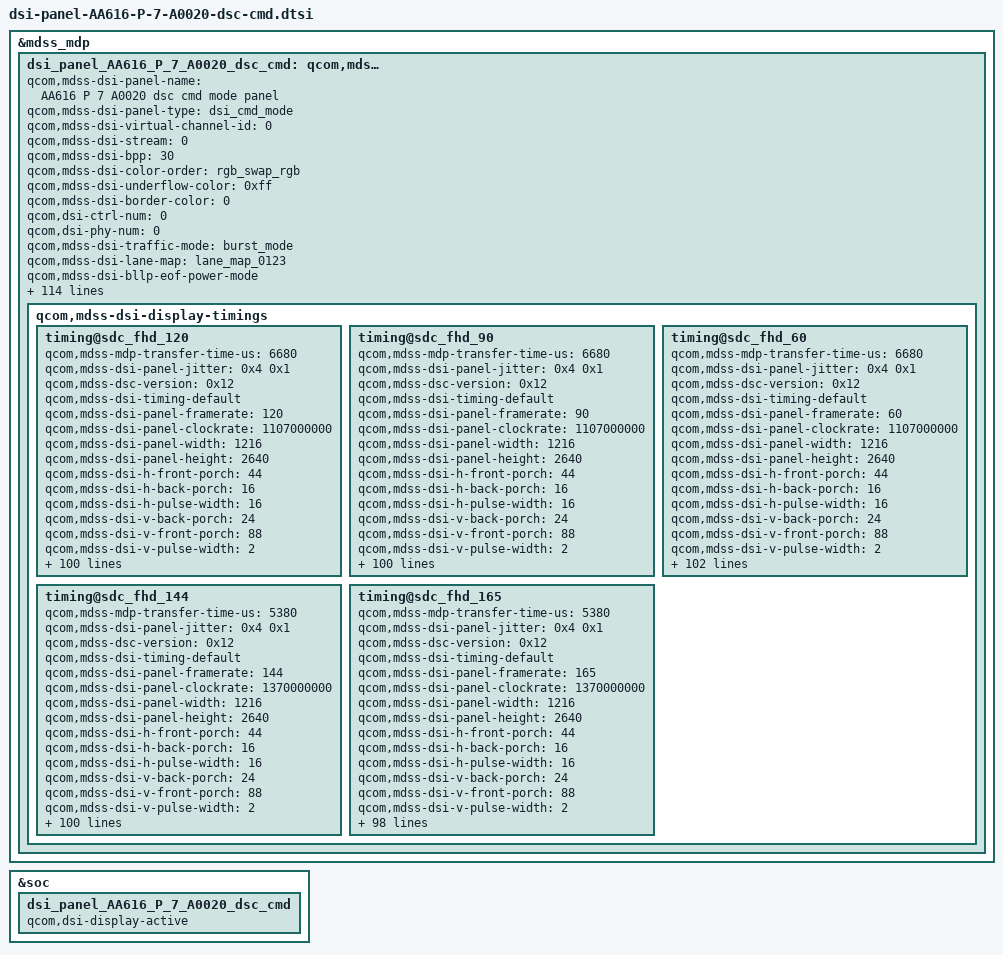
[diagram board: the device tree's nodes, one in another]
&mdss_mdp {
	dsi_panel_AA616_P_7_A0020_dsc_cmd: qcom,mdss_dsi_panel_AA616_P_7_A0020_dsc_cmd {
		qcom,mdss-dsi-panel-name = "AA616 P 7 A0020 dsc cmd mode panel";
		qcom,mdss-dsi-panel-type = "dsi_cmd_mode";
		qcom,mdss-dsi-virtual-channel-id = <0>;
		qcom,mdss-dsi-stream = <0>;
		qcom,mdss-dsi-bpp = <30>;
		qcom,mdss-dsi-color-order = "rgb_swap_rgb";
		qcom,mdss-dsi-underflow-color = <0xff>;
		qcom,mdss-dsi-border-color = <0>;
		qcom,dsi-ctrl-num = <0>;
		qcom,dsi-phy-num = <0>;
		qcom,mdss-dsi-traffic-mode = "burst_mode";
		qcom,mdss-dsi-lane-map = "lane_map_0123";
		qcom,mdss-dsi-bllp-eof-power-mode;
		qcom,mdss-dsi-bllp-power-mode;
		qcom,mdss-dsi-lane-0-state;
		qcom,mdss-dsi-lane-1-state;
		qcom,mdss-dsi-lane-2-state;
		qcom,mdss-dsi-lane-3-state;
		qcom,mdss-dsi-dma-trigger = "trigger_sw";
		qcom,mdss-dsi-dma-schedule-line = <1>;
		qcom,mdss-dsi-dma-schedule-window = <10>;
		qcom,mdss-dsi-mdp-trigger = "none";
		qcom,mdss-dsi-reset-sequence = <1 2>, <0 5>, <1 25>;
		qcom,mdss-dsi-te-pin-select = <1>;
		qcom,mdss-dsi-te-dcs-command = <1>;
		qcom,mdss-pan-physical-width-dimension = <71>;
		qcom,mdss-pan-physical-height-dimension = <157>;
		qcom,mdss-dsi-init-delay-us = <1000>;
		qcom,mdss-dsi-te-check-enable;
		qcom,mdss-dsi-te-using-te-pin;
		//qcom,mdss-dsi-lp11-init;
		qcom,mdss-dsi-wr-mem-start = <0x2c>;
		qcom,mdss-dsi-wr-mem-continue = <0x3c>;
		qcom,mdss-dsi-panel-jitter = <0x4 0x1>;
		qcom,mdss-bl-high2bit;
  		/* HDR Setting */
		qcom,mdss-dsi-panel-hdr-enabled;
		qcom,mdss-dsi-panel-hdr-color-primaries = <15635 16450 34000 16000 13250 34500 7500 3000>;
		//update for [MPC15]android.mediapc.cts.PerformanceClassTest#testDisplayHdr pass
		//qcom,mdss-dsi-panel-peak-brightness = <5400000>;
		qcom,mdss-dsi-panel-peak-brightness = <20000000>;
		qcom,mdss-dsi-panel-average-brightness = <2000000>;
		qcom,mdss-dsi-panel-blackness-level = <4000>;
		qcom,dynamic-mode-switch-enabled;
		qcom,dynamic-mode-switch-type = "dynamic-resolution-switch-immediate";
		qcom,mdss-dsi-display-timings {
			timing@sdc_fhd_120 {
				#include "dsi-panel-AA616-P-7-A0020-common.dtsi"
				#include "dsi-panel-AA616-P-7-A0020-loading-effect.dtsi"
				qcom,mdss-mdp-transfer-time-us = <6680>;
				qcom,mdss-dsi-panel-jitter = <0x4 0x1>;
				qcom,mdss-dsc-version = <0x12>;
				qcom,mdss-dsi-timing-default;
				qcom,mdss-dsi-panel-framerate = <120>;
				qcom,mdss-dsi-panel-clockrate = <1107000000>;
				qcom,mdss-dsi-panel-width = <1216>;
				qcom,mdss-dsi-panel-height = <2640>;

				qcom,mdss-dsi-h-front-porch = <44>;
				qcom,mdss-dsi-h-back-porch = <16>;
				qcom,mdss-dsi-h-pulse-width = <16>;
				qcom,mdss-dsi-v-back-porch = <24>;
				qcom,mdss-dsi-v-front-porch = <88>;
				qcom,mdss-dsi-v-pulse-width = <2>;
				qcom,mdss-dsi-h-sync-pulse = <0>;

				qcom,mdss-dsi-timing-switch-command = [
					39 00 00 40 00 00 04 FF 5A A5 08 // PAGE 08
					15 00 00 40 00 00 02 98 02 //Queue Start Close CDM FIFO Reset
					39 00 00 40 00 00 04 FF 5A A5 4F //CMD_Q
					15 00 00 40 00 00 02 80 01 //Enable MSFC
					15 00 00 40 00 00 02 81 06 //04 Rising,05Falling
					15 00 00 40 00 00 02 88 78 // cmd core0 queue start
					39 00 00 40 00 00 04 FF 5A A5 53
					39 00 00 40 00 00 06 90 44 00 00 04 00
					39 00 00 40 00 00 06 FE 44 00 00 04 00
					39 00 00 40 00 00 06 FE 44 00 00 04 00
					39 00 00 40 00 00 06 FE 44 00 00 04 00
					15 00 00 40 00 00 02 F0 01 //MURA_TUNNING
					15 00 00 40 00 00 02 00 00
					15 00 00 40 00 00 02 00 00
					15 00 00 40 00 00 02 00 00
					15 00 00 40 00 00 02 00 00
					15 00 00 40 00 00 02 00 00
					15 00 00 40 00 00 02 00 00
					15 00 00 40 00 00 02 00 00
					15 00 00 40 00 00 02 00 00
					39 00 00 40 00 00 04 FF 5A A5 63
					39 00 00 40 00 00 06 F1 20 20 20 20 20
					39 00 00 40 00 00 06 FE 20 00 00 00 00
					39 00 00 40 00 00 06 FE 00 00 00 00 00
					15 00 00 40 00 00 02 FE 00
					15 00 00 40 00 00 02 00 00
					15 00 00 40 00 00 02 00 00
					15 00 00 40 00 00 02 00 00
					15 00 00 40 00 00 02 00 00
					15 00 00 40 00 00 02 00 00
					39 00 00 40 00 00 06 F2 00 00 00 00 00
					39 00 00 40 00 00 06 FE 00 00 00 00 00
					39 00 00 40 00 00 06 FE 00 00 00 00 00
					15 00 00 40 00 00 02 FE 00
					15 00 00 40 00 00 02 00 00
					15 00 00 40 00 00 02 00 00
					15 00 00 40 00 00 02 00 00
					15 00 00 40 00 00 02 00 00
					15 00 00 40 00 00 02 00 00
					39 00 00 40 00 00 06 F3 00 00 00 00 00
					39 00 00 40 00 00 06 FE 00 20 20 20 20
					39 00 00 40 00 00 06 FE 00 00 00 00 00
					15 00 00 40 00 00 02 FE 00
					15 00 00 40 00 00 02 00 00
					15 00 00 40 00 00 02 00 00
					15 00 00 40 00 00 02 00 00
					15 00 00 40 00 00 02 00 00
					15 00 00 40 00 00 02 00 00
					39 00 00 40 00 00 06 F4 00 00 00 00 00
					39 00 00 40 00 00 06 FE 00 F0 F0 F0 F0
					39 00 00 40 00 00 06 FE 00 00 00 00 00
					15 00 00 40 00 00 02 FE 00
					15 00 00 40 00 00 02 00 00
					15 00 00 40 00 00 02 00 00
					15 00 00 40 00 00 02 00 00
					15 00 00 40 00 00 02 00 00
					15 00 00 40 00 00 02 00 00
					15 00 00 40 00 00 02 00 00
					15 00 00 40 00 00 02 00 00
					15 00 00 40 00 00 02 00 00
					39 00 00 40 00 00 04 FF 5A A5 53
					15 00 00 40 00 00 02 F0 00
					39 00 00 40 00 00 04 FF 5A A5 00 // PAGE 00
					15 00 00 40 00 00 02 60 00 //120Hz
					15 00 00 40 00 00 02 7D 00
					39 00 00 40 00 00 04 FF 5A A5 20
					15 00 00 40 00 00 02 BB 05 //sync Setting
					39 00 00 40 00 00 04 FF 5A A5 08 //ALL Done open CDM FIFO Reset
					15 00 00 40 00 00 02 98 A6
					39 00 00 40 00 00 04 FF 5A A5 00 //Dummy write
					15 00 00 40 00 00 02 00 00
					39 00 00 40 00 00 04 FF 5A A5 4F // PAGE 4F
					15 00 00 40 00 00 02 8B 78 // cmd core 0 queue all done
					39 00 00 00 00 00 04 FF 5A A5 00
				];
				qcom,mdss-dsi-on-command = [
					39 00 00 40 00 00 04 FF 5A A5 08
					15 00 00 40 00 00 02 C8 62
					39 00 00 40 00 00 04 FF 5A A5 21
					15 00 00 40 00 00 02 A4 38
					39 00 00 40 00 00 04 FF 5A A5 23
					15 00 00 40 00 00 02 85 15
					39 00 00 40 00 00 04 FF 5A A5 06
					15 00 00 40 00 00 02 C6 01
					39 00 00 40 00 00 04 FF 5A A5 08
					15 00 00 40 00 00 02 D2 05
					15 00 00 40 00 00 02 D3 01
					39 00 00 40 00 00 09 ED FF FF FF FF FF FF 45 FF
					39 00 00 40 00 00 09 EE FF FD FF FD F9 FA BE 76

					39 00 00 40 00 00 04 FF 5A A5 07
					15 00 00 40 00 00 02 8A 01
					39 00 00 40 00 00 03 8B 21 E0
					39 00 00 40 00 00 64 81 00 00 00 00 00 12 00 00 AB 21 00 0A 50 04 C0 00 14 02 60 02 60 01 55 01 D3 00 0A 01 08 00 33 00 0D 05 7A 19 5A 08 00 0B F0 07 10 20 00 06 0F 0F 33 0E 1C 2A 38 46 54 62 69 70 77 79 7B 7D 7E 00 82 11 40 19 C0 22 3E 32 7C 3A BA 3A F8 3B 38 3B 38 3B 76 4B 76 4B 74 4B 74 5B B4 73 F4 01 00 00 00 00 00
					15 00 00 40 00 00 02 91 03
					39 00 00 40 00 00 04 FF 5A A5 14
					15 00 00 40 00 00 02 80 00
					15 00 00 40 00 00 02 82 01
					39 00 00 40 00 00 04 FF 5A A5 17
					15 00 00 40 00 00 02 A0 0C
					39 00 00 40 00 00 04 FF 5A A5 13
					15 00 00 40 00 00 02 F9 3C
					39 00 00 40 00 00 04 FF 5A A5 22
					39 00 00 40 00 00 08 D8 00 F4 11 10 3E 17 17
					39 00 00 40 00 00 08 D9 00 F3 11 10 3E 17 17
					39 00 00 40 00 00 08 DA 00 EA 11 10 2B 16 16
					39 00 00 40 00 00 08 DB 00 E9 11 10 2B 16 16
					39 00 00 40 00 00 0A DC 84 94 BB 00 20 C4 A1 CC 10
					15 00 00 40 00 00 02 DD 01
					15 00 00 40 00 00 02 DE F1
					15 00 00 40 00 00 02 DF 80
					39 00 00 00 00 00 07 E0 02 00 5F 21 00 28

					39 00 00 40 00 00 04 FF 5A A5 00
					15 00 00 00 00 00 02 7D 00

					39 00 00 40 00 00 04 FF 5A A5 22
					39 00 00 40 00 00 08 D8 00 F6 11 10 38 17 17
					39 00 00 40 00 00 08 D9 00 F5 11 10 38 17 17
					39 00 00 40 00 00 08 DA 00 EA 11 10 2B 16 16
					39 00 00 40 00 00 08 DB 00 E9 11 10 2B 16 16
					39 00 00 40 00 00 0A DC 84 94 BB 00 20 C4 A1 CC 10
					15 00 00 40 00 00 02 DD 01
					15 00 00 40 00 00 02 DE F1
					15 00 00 40 00 00 02 DF 80
					39 00 00 40 00 00 07 E0 02 00 5F 21 00 28
					15 00 00 40 00 00 02 5E 01 // Skip frame Enable
					15 00 00 40 00 00 02 60 00 // Normal mode1=120Hz
					15 00 00 40 00 00 02 61 02 //AOD in Mode3=30Hz
					15 00 00 40 00 00 02 6D 01 // IRC enable
					15 00 00 40 00 00 02 35 00 // TE on
					15 00 00 00 00 00 02 53 20 // BC On

					// 120Hz
					39 00 00 40 00 00 04 FF 5A A5 00
					15 00 00 00 00 00 02 60 00
					15 00 00 00 78 00 02 11 00
					39 00 00 40 00 00 04 FF 5A A5 49
					39 00 00 40 00 00 0C 80 00 01 09 11 21 41 81 C1 01 00 01
					39 00 00 40 00 00 11 81 01 00 BD 00 18 01 41 02 42 02 A6 03 8B 05 DD 06
					39 00 00 40 00 00 13 82 01 00 BD 00 18 01 41 02 42 02 A6 03 8B 05 DD 06 00 00
					15 00 00 40 00 00 02 83 07
					15 00 00 40 00 00 02 84 0A
					39 00 00 40 00 00 04 85 80 00 02
					39 00 00 40 00 00 04 86 80 00 02
					39 00 00 40 00 00 04 A0 40 40 40
					39 00 00 40 00 00 04 A1 40 40 40
					39 00 00 40 00 00 04 A2 40 40 40
					15 00 00 40 00 00 02 A6 3F
					15 00 00 40 00 00 02 A7 03
					15 00 00 40 00 00 02 AD 01
					15 00 00 40 00 00 02 AE 00
					15 00 00 40 00 00 02 AF 00
					15 00 00 40 00 00 02 D9 02
					15 00 00 40 00 00 02 DA F7
					15 00 00 40 00 00 02 DB 9C
					15 00 00 40 00 00 02 DC 03
					15 00 00 40 00 00 02 DF 06
					15 00 00 40 00 00 02 E0 01
					39 00 00 40 00 00 04 FF 5A A5 5A
					39 00 00 40 00 00 04 80 03 D0 00
					39 00 00 40 00 00 04 81 5D D0 40
					39 00 00 40 00 00 04 82 0F 04 0B
					39 00 00 40 00 00 04 83 6D 80 0C
					39 00 00 40 00 00 04 84 50 20 4A
					39 00 00 40 00 00 04 85 18 10 2D
					39 00 00 40 00 00 04 86 7E 80 0E
					39 00 00 40 00 00 04 87 1D 13 17
					39 00 00 40 00 00 04 88 10 0F 0F
					39 00 00 40 00 00 04 89 0C 0A 06
					39 00 00 40 00 00 04 8A 7F 14 F0
					39 00 00 40 00 00 04 8B 1A 15 1B
					39 00 00 40 00 00 04 8C 18 12 1A
					39 00 00 40 00 00 04 8D 18 11 18
					39 00 00 40 00 00 04 8E 09 06 0A
					39 00 00 40 00 00 04 8F 7F 46 F6
					39 00 00 40 00 00 04 90 1C 14 1D
					39 00 00 40 00 00 04 91 1A 12 1B
					39 00 00 40 00 00 04 92 18 0A 19
					39 00 00 40 00 00 04 93 15 06 16
					39 00 00 40 00 00 04 94 0C 02 0D
					39 00 00 40 00 00 04 95 57 1D 03
					39 00 00 40 00 00 04 96 18 10 1A
					39 00 00 40 00 00 04 97 10 0F 12
					39 00 00 40 00 00 04 98 10 07 10
					39 00 00 40 00 00 04 99 0C 0A 0F
					39 00 00 40 00 00 04 9A 04 03 0A
					39 00 00 40 00 00 04 9B 03 01 03
					39 00 00 40 00 00 04 9C 52 3E 2D
					39 00 00 40 00 00 04 9D 34 32 2D
					39 00 00 40 00 00 04 9E 23 20 22
					39 00 00 40 00 00 04 9F 1D 1A 1D
					39 00 00 40 00 00 04 A0 16 12 16
					39 00 00 40 00 00 04 A1 0A 08 09
					39 00 00 40 00 00 04 A2 07 03 05
					39 00 00 40 00 00 04 A3 06 01 03
					39 00 00 40 00 00 04 A4 02 D0 00
					39 00 00 40 00 00 04 A5 14 DD 0F
					39 00 00 40 00 00 04 A6 0A E4 0C
					39 00 00 40 00 00 04 A7 4A 80 D8
					39 00 00 40 00 00 04 A8 05 02 07
					39 00 00 40 00 00 04 A9 03 00 05
					39 00 00 40 00 00 04 AA 24 80 8F
					39 00 00 40 00 00 04 AB 0A 06 09
					39 00 00 40 00 00 04 AC 07 05 07
					39 00 00 40 00 00 04 AD 03 00 05
					39 00 00 40 00 00 04 AE 32 03 04
					39 00 00 40 00 00 04 AF 13 10 12
					39 00 00 40 00 00 04 B0 10 06 0D
					39 00 00 40 00 00 04 B1 0E 04 0C
					39 00 00 40 00 00 04 B2 03 01 05
					39 00 00 40 00 00 04 B3 2A 16 02
					39 00 00 40 00 00 04 B4 0E 0C 10
					39 00 00 40 00 00 04 B5 0D 0A 0E
					39 00 00 40 00 00 04 B6 0A 07 0A
					39 00 00 40 00 00 04 B7 07 05 0B
					39 00 00 40 00 00 04 B8 05 04 06
					39 00 00 40 00 00 04 B9 1F 10 1D
					39 00 00 40 00 00 04 BA 18 0F 12
					39 00 00 40 00 00 04 BB 13 0D 0A
					39 00 00 40 00 00 04 BC 0E 08 0A
					39 00 00 40 00 00 04 BD 09 06 0C
					39 00 00 40 00 00 04 BE 07 05 08
					39 00 00 40 00 00 04 BF 04 04 06
					39 00 00 40 00 00 04 C0 37 23 2F
					39 00 00 40 00 00 04 C1 27 1F 1F
					39 00 00 40 00 00 04 C2 1D 18 0D
					39 00 00 40 00 00 04 C3 1A 12 08
					39 00 00 40 00 00 04 C4 12 10 06
					39 00 00 40 00 00 04 C5 0A 07 03
					39 00 00 40 00 00 04 C6 08 04 02
					39 00 00 40 00 00 04 C7 03 02 01
					39 00 00 40 00 00 04 C8 40 06 0A
					39 00 00 40 00 00 04 C9 25 00 12
					39 00 00 40 00 00 04 CA 16 00 06
					39 00 00 40 00 00 04 CB 5A 00 00
					39 00 00 40 00 00 04 CC 06 01 06
					39 00 00 40 00 00 04 CD 03 00 05
					39 00 00 40 00 00 04 CE 30 00 00
					39 00 00 40 00 00 04 CF 10 04 06
					39 00 00 40 00 00 04 D0 0D 02 0E
					39 00 00 40 00 00 04 D1 06 00 0A
					39 00 00 40 00 00 04 D2 20 02 08
					39 00 00 40 00 00 04 D3 0D 04 06
					39 00 00 40 00 00 04 D4 08 00 05
					39 00 00 40 00 00 04 D5 06 00 03
					39 00 00 40 00 00 04 D6 05 00 01
					39 00 00 40 00 00 04 D7 26 15 16
					39 00 00 40 00 00 04 D8 12 0D 13
					39 00 00 40 00 00 04 D9 10 0A 12
					39 00 00 40 00 00 04 DA 0D 09 08
					39 00 00 40 00 00 04 DB 07 05 07
					39 00 00 40 00 00 04 DC 04 03 05
					39 00 00 40 00 00 04 DD 26 2A 26
					39 00 00 40 00 00 04 DE 20 28 23
					39 00 00 40 00 00 04 DF 16 1A 1E
					39 00 00 40 00 00 04 E0 12 16 14
					39 00 00 40 00 00 04 E1 0D 0F 0E
					39 00 00 40 00 00 04 E2 03 04 02
					39 00 00 40 00 00 04 E3 02 03 01
					39 00 00 40 00 00 04 E4 34 23 14
					39 00 00 40 00 00 04 E5 16 13 00
					39 00 00 40 00 00 04 E6 08 0D 00
					39 00 00 40 00 00 04 E7 06 0A 00
					39 00 00 40 00 00 04 E8 05 08 00
					39 00 00 40 00 00 04 E9 03 05 00
					39 00 00 40 00 00 04 EA 02 04 00
					39 00 00 40 00 00 04 EB 00 02 00
					39 00 00 40 00 00 04 FF 5A A5 5B
					39 00 00 40 00 00 04 80 05 00 00
					39 00 00 40 00 00 04 81 2A FA 10
					39 00 00 40 00 00 04 82 04 00 01
					39 00 00 40 00 00 04 83 2C FC 15
					39 00 00 40 00 00 04 84 08 01 03
					39 00 00 40 00 00 04 85 03 01 02
					39 00 00 40 00 00 04 86 0D 08 0E
					39 00 00 40 00 00 04 87 05 03 02
					39 00 00 40 00 00 04 88 04 02 03
					39 00 00 40 00 00 04 89 03 00 01
					39 00 00 40 00 00 04 8A 16 03 06
					39 00 00 40 00 00 04 8B 04 03 03
					39 00 00 40 00 00 04 8C 02 02 02
					39 00 00 40 00 00 04 8D 01 00 01
					39 00 00 40 00 00 04 8E 00 00 00
					39 00 00 40 00 00 04 8F 24 18 1B
					39 00 00 40 00 00 04 90 18 1C 1A
					39 00 00 40 00 00 04 91 14 16 14
					39 00 00 40 00 00 04 92 10 0F 11
					39 00 00 40 00 00 04 93 0A 08 0B
					39 00 00 40 00 00 04 94 05 06 04
					39 00 00 40 00 00 04 95 25 1D 1E
					39 00 00 40 00 00 04 96 16 18 1A
					39 00 00 40 00 00 04 97 12 14 16
					39 00 00 40 00 00 04 98 10 11 12
					39 00 00 40 00 00 04 99 0A 0C 0D
					39 00 00 40 00 00 04 9A 07 08 0A
					39 00 00 40 00 00 04 9B 05 06 07
					39 00 00 40 00 00 04 9C 38 2C 44
					39 00 00 40 00 00 04 9D 36 2A 40
					39 00 00 40 00 00 04 9E 32 24 3A
					39 00 00 40 00 00 04 9F 20 1A 2A
					39 00 00 40 00 00 04 A0 1A 16 1F
					39 00 00 40 00 00 04 A1 16 10 14
					39 00 00 40 00 00 04 A2 07 08 07
					39 00 00 40 00 00 04 A3 05 06 06
					39 00 00 40 00 00 04 A4 06 00 00
					39 00 00 40 00 00 04 A5 10 09 02
					39 00 00 40 00 00 04 A6 06 00 02
					39 00 00 40 00 00 04 A7 0F 08 04
					39 00 00 40 00 00 04 A8 06 02 07
					39 00 00 40 00 00 04 A9 05 01 06
					39 00 00 40 00 00 04 AA 10 02 07
					39 00 00 40 00 00 04 AB 04 02 03
					39 00 00 40 00 00 04 AC 03 01 02
					39 00 00 40 00 00 04 AD 02 00 04
					39 00 00 40 00 00 04 AE 1A 06 09
					39 00 00 40 00 00 04 AF 09 06 09
					39 00 00 40 00 00 04 B0 08 05 07
					39 00 00 40 00 00 04 B1 07 03 05
					39 00 00 40 00 00 04 B2 04 01 03
					39 00 00 40 00 00 04 B3 1F 13 16
					39 00 00 40 00 00 04 B4 18 13 19
					39 00 00 40 00 00 04 B5 15 12 17
					39 00 00 40 00 00 04 B6 11 0D 13
					39 00 00 40 00 00 04 B7 0A 08 0D
					39 00 00 40 00 00 04 B8 04 06 07
					39 00 00 40 00 00 04 B9 26 1D 23
					39 00 00 40 00 00 04 BA 1A 18 1C
					39 00 00 40 00 00 04 BB 14 10 15
					39 00 00 40 00 00 04 BC 10 13 12
					39 00 00 40 00 00 04 BD 0B 0F 0F
					39 00 00 40 00 00 04 BE 04 05 04
					39 00 00 40 00 00 04 BF 03 02 03
					39 00 00 40 00 00 04 C0 3C 30 4C
					39 00 00 40 00 00 04 C1 3A 2A 40
					39 00 00 40 00 00 04 C2 32 24 3A
					39 00 00 40 00 00 04 C3 20 1D 2C
					39 00 00 40 00 00 04 C4 1A 16 1F
					39 00 00 40 00 00 04 C5 16 10 14
					39 00 00 40 00 00 04 C6 05 06 08
					39 00 00 40 00 00 04 C7 04 05 06
					39 00 00 40 00 00 04 C8 04 00 00
					39 00 00 40 00 00 04 C9 18 0D 10
					39 00 00 40 00 00 04 CA 18 00 02
					39 00 00 40 00 00 04 CB 0C 04 04
					39 00 00 40 00 00 04 CC 03 02 01
					39 00 00 40 00 00 04 CD 02 01 00
					39 00 00 40 00 00 04 CE 06 03 08
					39 00 00 40 00 00 04 CF 04 02 04
					39 00 00 40 00 00 04 D0 03 01 03
					39 00 00 40 00 00 04 D1 02 00 00
					39 00 00 40 00 00 04 D2 0E 0A 10
					39 00 00 40 00 00 04 D3 0A 08 0D
					39 00 00 40 00 00 04 D4 07 05 0A
					39 00 00 40 00 00 04 D5 04 03 07
					39 00 00 40 00 00 04 D6 03 01 06
					39 00 00 40 00 00 04 D7 18 12 22
					39 00 00 40 00 00 04 D8 16 10 1A
					39 00 00 40 00 00 04 D9 12 0A 14
					39 00 00 40 00 00 04 DA 0D 08 12
					39 00 00 40 00 00 04 DB 06 06 0C
					39 00 00 40 00 00 04 DC 02 04 03
					39 00 00 40 00 00 04 DD 2C 28 34
					39 00 00 40 00 00 04 DE 28 22 30
					39 00 00 40 00 00 04 DF 20 18 2A
					39 00 00 40 00 00 04 E0 16 14 1A
					39 00 00 40 00 00 04 E1 0A 08 0D
					39 00 00 40 00 00 04 E2 03 03 03
					39 00 00 40 00 00 04 E3 02 02 02
					39 00 00 40 00 00 04 E4 3C 34 40
					39 00 00 40 00 00 04 E5 3A 2A 40
					39 00 00 40 00 00 04 E6 32 24 3A
					39 00 00 40 00 00 04 E7 20 1D 2C
					39 00 00 40 00 00 04 E8 1A 16 1F
					39 00 00 40 00 00 04 E9 16 10 14
					39 00 00 40 00 00 04 EA 03 02 03
					39 00 00 40 00 00 04 EB 04 05 06
					39 00 00 40 00 00 04 FF 5A A5 5C
					39 00 00 40 00 00 04 80 03 F4 FA
					39 00 00 40 00 00 04 81 05 00 02
					39 00 00 40 00 00 04 82 02 01 03
					39 00 00 40 00 00 04 83 09 04 06
					39 00 00 40 00 00 04 84 05 02 05
					39 00 00 40 00 00 04 85 04 01 04
					39 00 00 40 00 00 04 86 08 07 05
					39 00 00 40 00 00 04 87 07 05 0A
					39 00 00 40 00 00 04 88 04 04 04
					39 00 00 40 00 00 04 89 02 02 02
					39 00 00 40 00 00 04 8A 0C 08 0F
					39 00 00 40 00 00 04 8B 0A 07 0C
					39 00 00 40 00 00 04 8C 09 06 0A
					39 00 00 00 00 00 04 8D 06 05 08
					39 00 00 40 00 00 04 8E 04 03 05
					39 00 00 40 00 00 04 8F 23 1A 26
					39 00 00 40 00 00 04 90 1C 14 1D
					39 00 00 40 00 00 04 91 12 0A 18
					39 00 00 40 00 00 04 92 0D 07 14
					39 00 00 40 00 00 04 93 06 07 0A
					39 00 00 40 00 00 04 94 02 04 03
					39 00 00 40 00 00 04 95 34 32 3A
					39 00 00 40 00 00 04 96 2B 28 34
					39 00 00 40 00 00 04 97 26 24 2A
					39 00 00 40 00 00 04 98 16 14 1A
					39 00 00 40 00 00 04 99 0A 08 0D
					39 00 00 40 00 00 04 9A 03 03 02
					39 00 00 40 00 00 04 9B 02 02 02
					39 00 00 40 00 00 04 9C 44 3E 54
					39 00 00 40 00 00 04 9D 3A 2A 40
					39 00 00 40 00 00 04 9E 34 26 3A
					39 00 00 40 00 00 04 9F 20 1D 2C
					39 00 00 40 00 00 04 A0 1A 16 1F
					39 00 00 40 00 00 04 A1 16 10 14
					39 00 00 40 00 00 04 A2 03 02 03
					39 00 00 40 00 00 04 A3 04 05 06
					39 00 00 40 00 00 04 A4 04 02 02
					39 00 00 40 00 00 04 A5 06 03 03
					39 00 00 40 00 00 04 A6 02 01 01
					39 00 00 40 00 00 04 A7 03 02 02
					39 00 00 40 00 00 04 A8 02 01 02
					39 00 00 40 00 00 04 A9 02 01 02
					39 00 00 40 00 00 04 AA 05 05 06
					39 00 00 40 00 00 04 AB 04 04 05
					39 00 00 40 00 00 04 AC 03 03 04
					39 00 00 40 00 00 04 AD 02 02 03
					39 00 00 40 00 00 04 AE 08 04 08
					39 00 00 40 00 00 04 AF 06 03 07
					39 00 00 40 00 00 04 B0 05 02 06
					39 00 00 40 00 00 04 B1 03 01 05
					39 00 00 40 00 00 04 B2 02 00 04
					39 00 00 40 00 00 04 B3 25 23 24
					39 00 00 40 00 00 04 B4 23 20 21
					39 00 00 40 00 00 04 B5 13 0D 14
					39 00 00 40 00 00 04 B6 0E 0A 10
					39 00 00 40 00 00 04 B7 06 08 0A
					39 00 00 40 00 00 04 B8 02 04 03
					39 00 00 40 00 00 04 B9 34 31 37
					39 00 00 40 00 00 04 BA 2B 28 34
					39 00 00 40 00 00 04 BB 26 24 2A
					39 00 00 40 00 00 04 BC 16 15 1A
					39 00 00 40 00 00 04 BD 0A 08 0D
					39 00 00 40 00 00 04 BE 02 03 02
					39 00 00 40 00 00 04 BF 02 01 02
					39 00 00 40 00 00 04 C0 35 33 28
					39 00 00 40 00 00 04 C1 34 2A 24
					39 00 00 40 00 00 04 C2 34 26 1C
					39 00 00 40 00 00 04 C3 20 1D 18
					39 00 00 40 00 00 04 C4 1A 16 16
					39 00 00 40 00 00 04 C5 16 10 14
					39 00 00 40 00 00 04 C6 03 02 03
					39 00 00 40 00 00 04 C7 04 05 06
					39 00 00 40 00 00 04 C8 08 04 06
					39 00 00 40 00 00 04 C9 08 04 06
					39 00 00 40 00 00 04 CA 07 03 05
					39 00 00 40 00 00 04 CB 07 03 05
					39 00 00 40 00 00 04 CC 00 00 00
					39 00 00 40 00 00 04 CD 00 00 00
					39 00 00 40 00 00 04 CE 00 00 00
					39 00 00 00 00 00 04 CF 00 00 00
					15 00 00 00 14 00 02 29 00
				];
				qcom,mdss-dsi-off-command=[
					05 00 00 00 14 00 01 28
					05 00 00 00 78 00 01 10
				];
				qcom,mdss-dsi-timing-switch-compensation-command = [
					39 00 00 40 00 00 04 FF 5A A5 08 // PAGE 08
					15 00 00 40 00 00 02 98 02 //Queue Start Close CDM FIFO Reset
					39 00 00 40 00 00 04 FF 5A A5 4F //CMD_Q
					15 00 00 40 00 00 02 80 01 //Enable MSFC
					15 00 00 40 00 00 02 81 06 //04 Rising,05Falling
					15 00 00 40 00 00 02 88 78 // cmd core0 queue start
					//queue1_str
					39 00 00 40 00 00 04 FF 5A A5 24
					39 00 00 40 00 00 06 C9 00 00 00 10 00
					39 00 00 40 00 00 04 FE 30 00 70
					39 00 00 40 00 00 06 CA 00 B0 00 E0 01 //11 13
					39 00 00 40 00 00 04 FE 10 01 30 //15 19
					39 00 00 40 00 00 06 CB 01 70 01 C0 02 //23  27
					39 00 00 40 00 00 04 FE 30 02 90 //33  41
					39 00 00 40 00 00 06 CC 03 70 03 E0 04 //55 63 79
					39 00 00 40 00 00 04 FE F0 05 F0 //95
					39 00 00 40 00 00 06 CD 07 10 08 F0 0A //113 143
					39 00 00 40 00 00 04 FE F0 0B A0 //175 186
					39 00 00 40 00 00 06 CE 0D 30 0E 10 0E //225 239
					39 00 00 40 00 00 04 FE F0 0F F0
					39 00 00 40 00 00 04 FF 5A A5 4F // PAGE 4F
					15 00 00 40 00 00 02 8A 78
					//queue2_str
					39 00 00 40 00 00 04 FF 5A A5 00 // PAGE 00
					15 00 00 40 00 00 02 60 00 //120hz
					15 00 00 40 00 00 02 7D 00
					39 00 00 40 00 00 04 FF 5A A5 20
					15 00 00 40 00 00 02 BB 05 //sync setting
					39 00 00 40 00 00 04 FF 5A A5 24
					39 00 00 40 00 00 06 C9 00 00 00 10 00
					39 00 00 40 00 00 04 FE 30 00 70
					39 00 00 40 00 00 06 CA 00 B0 00 D0 00 //11 13
					39 00 00 40 00 00 04 FE F0 01 30 //15 19
					39 00 00 40 00 00 06 CB 01 70 01 B0 02 //23  27
					39 00 00 40 00 00 04 FE 10 02 90 //33  41
					39 00 00 40 00 00 06 CC 03 70 03 F0 04 //55 63 79
					39 00 00 40 00 00 04 FE F0 05 F0 //95
					39 00 00 40 00 00 06 CD 07 10 08 F0 0A //113 143
					39 00 00 40 00 00 04 FE F0 0B A0 //175 186
					39 00 00 40 00 00 06 CE 0D 30 0E 10 0E //225 239
					39 00 00 40 00 00 04 FE F0 0F F0
					//queue2_end
					39 00 00 40 00 00 04 FF 5A A5 53
					15 00 00 40 00 00 02 F0 01 //MURA_TUNNING
					15 00 00 40 00 00 02 00 00
					15 00 00 40 00 00 02 00 00
					15 00 00 40 00 00 02 00 00
					15 00 00 40 00 00 02 00 00
					15 00 00 40 00 00 02 00 00
					15 00 00 40 00 00 02 00 00
					15 00 00 40 00 00 02 00 00
					15 00 00 40 00 00 02 00 00
					39 00 00 40 00 00 04 FF 5A A5 63
					39 00 00 40 00 00 06 F1 20 20 20 20 20
					39 00 00 40 00 00 06 FE 20 00 00 00 00
					39 00 00 40 00 00 06 FE 00 00 00 00 00
					15 00 00 40 00 00 02 FE 00
					15 00 00 40 00 00 02 00 00
					15 00 00 40 00 00 02 00 00
					15 00 00 40 00 00 02 00 00
					15 00 00 40 00 00 02 00 00
					15 00 00 40 00 00 02 00 00
					39 00 00 40 00 00 06 F2 00 00 00 00 00
					39 00 00 40 00 00 06 FE 00 00 00 00 00
					39 00 00 40 00 00 06 FE 00 00 00 00 00
					15 00 00 40 00 00 02 FE 00
					15 00 00 40 00 00 02 00 00
					15 00 00 40 00 00 02 00 00
					15 00 00 40 00 00 02 00 00
					15 00 00 40 00 00 02 00 00
					15 00 00 40 00 00 02 00 00
					39 00 00 40 00 00 06 F3 00 00 00 00 00
					39 00 00 40 00 00 06 FE 00 20 20 20 20
					39 00 00 40 00 00 06 FE 00 00 00 00 00
					15 00 00 40 00 00 02 FE 00
					15 00 00 40 00 00 02 00 00
					15 00 00 40 00 00 02 00 00
					15 00 00 40 00 00 02 00 00
					15 00 00 40 00 00 02 00 00
					15 00 00 40 00 00 02 00 00
					39 00 00 40 00 00 06 F4 00 00 00 00 00
					39 00 00 40 00 00 06 FE 00 F0 F0 F0 F0
					39 00 00 40 00 00 06 FE 00 00 00 00 00
					15 00 00 40 00 00 02 FE 00
					15 00 00 40 00 00 02 00 00
					15 00 00 40 00 00 02 00 00
					15 00 00 40 00 00 02 00 00
					15 00 00 40 00 00 02 00 00
					15 00 00 40 00 00 02 00 00
					15 00 00 40 00 00 02 00 00
					15 00 00 40 00 00 02 00 00
					15 00 00 40 00 00 02 00 00
					39 00 00 40 00 00 04 FF 5A A5 53
					15 00 00 40 00 00 02 F0 00
					39 00 00 40 00 00 04 FF 5A A5 00
					39 00 00 40 00 00 04 FF 5A A5 08 //ALL Done open CDM FIFO Reset
					15 00 00 40 00 00 02 98 A6
					39 00 00 40 00 00 04 FF 5A A5 00 //Dummy write
					15 00 00 40 00 00 02 00 00
					39 00 00 40 00 00 04 FF 5A A5 4F // PAGE 4F
					15 00 00 00 00 00 02 8B 78 // cmd core 0 queue all done
					39 00 00 00 00 00 04 FF 5A A5 00
					/* wait for te and blocking one frame */
					39 00 00 20 00 00 04 FF 5A A5 00
				];
				oplus,dsi-panel-switch-low-pwm-aod-on-command = [
				];
				oplus,dsi-panel-switch-low-pwm-aod-off-command = [
				];
				qcom,mdss-dsi-hbm-off-command = [
				];
				qcom,mdss-dsi-hbm-on-command = [
				];
				qcom,mdss-dsi-change-voltage-before-bl-0-command = [
				];
				qcom,mdss-dsi-lhbm-pressed-icon-on-command = [
				];
				qcom,mdss-dsi-lhbm-pressed-icon-off-command = [
				];
				qcom,mdss-dsi-aod-off-pwm-mode2-command = [
				];
				qcom,mdss-dsi-aod-off-compensation-command = [
				];
				qcom,mdss-dsi-aod-off-compensation-onepulse-command = [
				];
				/* pwm */
				qcom,mdss-dsi-pwm-state-l3tol2-command = [
				];
				qcom,mdss-dsi-pwm-state-l2tol3-command = [
				];
				qcom,mdss-dsi-pwm-switch-mode0-command= [
				];
				qcom,mdss-dsi-pwm-switch-mode2-command = [
				];
				qcom,mdss-dsi-timming-switch-pwm-mode2-command = [
				];
				qcom,mdss-dsi-pwm-switch-mode2-panel-on-command = [
				];
				qcom,mdss-dsi-pwm-state-l1tol3-command = [
				];
				qcom,mdss-dsi-pwm-state-l3tol1-command = [
				];
				qcom,mdss-dsi-hbm-max-command = [
				];
				qcom,mdss-dsi-hbm-exit-max-command = [
				];
				mdss-dsi-timing-switch-command-state = "dsi_hs_sync1_mode";
				qcom,mdss-dsi-lp1-command-state = "dsi_hs_sync1_mode";
				qcom,mdss-dsi-nolp-command-state = "dsi_hs_sync1_mode";
				oplus,dsi-panel-switch-low-pwm-aod-on-command-state = "dsi_hs_sync1_mode";
				oplus,dsi-panel-switch-low-pwm-aod-off-command-state = "dsi_hs_sync1_mode";
				qcom,mdss-dsi-aod-off-pwm-mode2-command-state = "dsi_hs_sync1_mode";
				qcom,mdss-dsi-aod-off-compensation-command-state = "dsi_lp_sync1_mode";
				qcom,mdss-dsi-aod-off-compensation-onepulse-command-state = "dsi_lp_sync1_mode";
				qcom,mdss-dsi-nolp-hpwm-command-state = "dsi_lp_sync1_mode";
				qcom,mdss-dsi-hbm-on-command-state = "dsi_hs_sync1_mode";
				qcom,mdss-dsi-hbm-off-command-state = "dsi_hs_sync1_mode";
				qcom,mdss-dsi-panel-read-register-open-state = "dsi_lp_mode";
				qcom,mdss-dsi-panel-read-register-close-state = "dsi_lp_mode";
				qcom,mdss-dsi-lhbm-pressed-icon-gamma-command-state = "dsi_lp_mode";
				qcom,mdss-dsi-lhbm-pressed-icon-grayscale-command-state = "dsi_lp_mode";
				qcom,mdss-dsi-lhbm-pressed-icon-on-command-state = "dsi_lp_mode";
				qcom,mdss-dsi-lhbm-pressed-icon-off-command-state = "dsi_lp_mode";
				qcom,mdss-dsi-lhbm-dbv-alpha-command-state = "dsi_hs_mode";

				qcom,mdss-dsi-reset-scanline-command-state = "dsi_hs_mode";
				qcom,mdss-dsi-recovery-scanline-command-state = "dsi_hs_mode";

				qcom,mdss-dsi-osc-track-on-command-state = "dsi_hs_mode";
				qcom,mdss-dsi-osc-track-off-command-state = "dsi_hs_mode";
				qcom,mdss-dsi-hbm-max-command-state = "dsi_hs_mode";
				qcom,mdss-dsi-hbm-exit-max-command-state = "dsi_hs_mode";

				qcom,lm-split = <608 608>;
				qcom,compression-mode = "dsc";
				qcom,mdss-dsc-encoders = <2>;
				qcom,mdss-dsc-slice-height = <20>;
				qcom,mdss-dsc-slice-width = <608>;
				qcom,mdss-dsc-slice-per-pkt = <2>;
				qcom,mdss-dsc-bit-per-component = <10>;
				qcom,mdss-dsc-bit-per-pixel = <8>;
				qcom,mdss-dsc-block-prediction-enable;
			};
			timing@sdc_fhd_90 {
				#include "dsi-panel-AA616-P-7-A0020-common.dtsi"
				#include "dsi-panel-AA616-P-7-A0020-loading-effect.dtsi"
				qcom,mdss-mdp-transfer-time-us = <6680>;
				qcom,mdss-dsi-panel-jitter = <0x4 0x1>;
				qcom,mdss-dsc-version = <0x12>;
				qcom,mdss-dsi-timing-default;
				qcom,mdss-dsi-panel-framerate = <90>;
				qcom,mdss-dsi-panel-clockrate = <1107000000>;
				qcom,mdss-dsi-panel-width = <1216>;
				qcom,mdss-dsi-panel-height = <2640>;

				qcom,mdss-dsi-h-front-porch = <44>;
				qcom,mdss-dsi-h-back-porch = <16>;
				qcom,mdss-dsi-h-pulse-width = <16>;
				qcom,mdss-dsi-v-back-porch = <24>;
				qcom,mdss-dsi-v-front-porch = <88>;
				qcom,mdss-dsi-v-pulse-width = <2>;
				qcom,mdss-dsi-h-sync-pulse = <0>;

				qcom,mdss-dsi-timing-switch-command = [
					39 00 00 40 00 00 04 FF 5A A5 08
					15 00 00 40 00 00 02 98 02
					39 00 00 40 00 00 04 FF 5A A5 4F
					15 00 00 40 00 00 02 80 01
					15 00 00 40 00 00 02 81 06
					15 00 00 40 00 00 02 88 78
					39 00 00 40 00 00 04 FF 5A A5 53
					39 00 00 40 00 00 06 90 44 00 00 03 F0
					39 00 00 40 00 00 06 FE 44 00 00 04 00
					39 00 00 40 00 00 06 FE 44 00 00 04 00
					39 00 00 40 00 00 06 FE 44 00 00 04 00
					15 00 00 40 00 00 02 F0 01
					15 00 00 40 00 00 02 00 00
					15 00 00 40 00 00 02 00 00
					15 00 00 40 00 00 02 00 00
					15 00 00 40 00 00 02 00 00
					15 00 00 40 00 00 02 00 00
					15 00 00 40 00 00 02 00 00
					15 00 00 40 00 00 02 00 00
					15 00 00 40 00 00 02 00 00
					39 00 00 40 00 00 04 FF 5A A5 63
					39 00 00 40 00 00 06 F1 20 20 20 20 20
					39 00 00 40 00 00 06 FE 20 00 00 00 00
					39 00 00 40 00 00 06 FE 00 00 00 00 00
					15 00 00 40 00 00 02 FE 00
					15 00 00 40 00 00 02 00 00
					15 00 00 40 00 00 02 00 00
					15 00 00 40 00 00 02 00 00
					15 00 00 40 00 00 02 00 00
					15 00 00 40 00 00 02 00 00
					39 00 00 40 00 00 06 F2 00 00 00 00 00
					39 00 00 40 00 00 06 FE 00 00 00 00 00
					39 00 00 40 00 00 06 FE 00 00 00 00 00
					15 00 00 40 00 00 02 FE 00
					15 00 00 40 00 00 02 00 00
					15 00 00 40 00 00 02 00 00
					15 00 00 40 00 00 02 00 00
					15 00 00 40 00 00 02 00 00
					15 00 00 40 00 00 02 00 00
					39 00 00 40 00 00 06 F3 00 00 00 00 00
					39 00 00 40 00 00 06 FE 00 20 20 20 20
					39 00 00 40 00 00 06 FE 00 00 00 00 00
					15 00 00 40 00 00 02 FE 00
					15 00 00 40 00 00 02 00 00
					15 00 00 40 00 00 02 00 00
					15 00 00 40 00 00 02 00 00
					15 00 00 40 00 00 02 00 00
					15 00 00 40 00 00 02 00 00
					39 00 00 40 00 00 06 F4 00 00 00 00 00
					39 00 00 40 00 00 06 FE 00 F0 F0 F0 F0
					39 00 00 40 00 00 06 FE 00 00 00 00 00
					15 00 00 40 00 00 02 FE 00
					15 00 00 40 00 00 02 00 00
					15 00 00 40 00 00 02 00 00
					15 00 00 40 00 00 02 00 00
					15 00 00 40 00 00 02 00 00
					15 00 00 40 00 00 02 00 00
					15 00 00 40 00 00 02 00 00
					15 00 00 40 00 00 02 00 00
					15 00 00 40 00 00 02 00 00
					39 00 00 40 00 00 04 FF 5A A5 53
					15 00 00 40 00 00 02 F0 00
					39 00 00 40 00 00 04 FF 5A A5 00
					15 00 00 40 00 00 02 60 04
					15 00 00 40 00 00 02 7D 01
					39 00 00 40 00 00 04 FF 5A A5 20
					15 00 00 40 00 00 02 BB 00
					39 00 00 40 00 00 04 FF 5A A5 08
					15 00 00 40 00 00 02 98 A6
					39 00 00 40 00 00 04 FF 5A A5 00
					15 00 00 40 00 00 02 00 00
					39 00 00 40 00 00 04 FF 5A A5 4F
					15 00 00 40 00 00 02 8B 78
					39 00 00 00 00 00 04 FF 5A A5 00
				];
				qcom,mdss-dsi-on-command = [
					39 00 00 40 00 00 04 FF 5A A5 08
					15 00 00 40 00 00 02 C8 62
					39 00 00 40 00 00 04 FF 5A A5 21
					15 00 00 40 00 00 02 A4 38
					39 00 00 40 00 00 04 FF 5A A5 23
					15 00 00 40 00 00 02 85 15
					39 00 00 40 00 00 04 FF 5A A5 06
					15 00 00 40 00 00 02 C6 01
					39 00 00 40 00 00 04 FF 5A A5 08
					15 00 00 40 00 00 02 D2 05
					15 00 00 40 00 00 02 D3 01
					39 00 00 40 00 00 09 ED FF FF FF FF FF FF 45 FF
					39 00 00 40 00 00 09 EE FF FD FF FD F9 FA BE 76

					39 00 00 40 00 00 04 FF 5A A5 07
					15 00 00 40 00 00 02 8A 01
					39 00 00 40 00 00 03 8B 21 E0
					39 00 00 40 00 00 64 81 00 00 00 00 00 12 00 00 AB 21 00 0A 50 04 C0 00 14 02 60 02 60 01 55 01 D3 00 0A 01 08 00 33 00 0D 05 7A 19 5A 08 00 0B F0 07 10 20 00 06 0F 0F 33 0E 1C 2A 38 46 54 62 69 70 77 79 7B 7D 7E 00 82 11 40 19 C0 22 3E 32 7C 3A BA 3A F8 3B 38 3B 38 3B 76 4B 76 4B 74 4B 74 5B B4 73 F4 01 00 00 00 00 00
					15 00 00 40 00 00 02 91 03
					39 00 00 40 00 00 04 FF 5A A5 14
					15 00 00 40 00 00 02 80 00
					15 00 00 40 00 00 02 82 01
					39 00 00 40 00 00 04 FF 5A A5 17
					15 00 00 40 00 00 02 A0 0C
					39 00 00 40 00 00 04 FF 5A A5 13
					15 00 00 40 00 00 02 F9 3C
					39 00 00 40 00 00 04 FF 5A A5 22
					39 00 00 40 00 00 08 D8 00 F4 11 10 3E 17 17
					39 00 00 40 00 00 08 D9 00 F3 11 10 3E 17 17
					39 00 00 40 00 00 08 DA 00 EA 11 10 2B 16 16
					39 00 00 40 00 00 08 DB 00 E9 11 10 2B 16 16
					39 00 00 40 00 00 0A DC 84 94 BB 00 20 C4 A1 CC 10
					15 00 00 40 00 00 02 DD 01
					15 00 00 40 00 00 02 DE F1
					15 00 00 40 00 00 02 DF 80
					39 00 00 00 00 00 07 E0 02 00 5F 21 00 28

					39 00 00 40 00 00 04 FF 5A A5 00
					15 00 00 00 00 00 02 7D 00

					39 00 00 40 00 00 04 FF 5A A5 22
					39 00 00 40 00 00 08 D8 00 F6 11 10 38 17 17
					39 00 00 40 00 00 08 D9 00 F5 11 10 38 17 17
					39 00 00 40 00 00 08 DA 00 EA 11 10 2B 16 16
					39 00 00 40 00 00 08 DB 00 E9 11 10 2B 16 16
					39 00 00 40 00 00 0A DC 84 94 BB 00 20 C4 A1 CC 10
					15 00 00 40 00 00 02 DD 01
					15 00 00 40 00 00 02 DE F1
					15 00 00 40 00 00 02 DF 80
					39 00 00 40 00 00 07 E0 02 00 5F 21 00 28
					15 00 00 40 00 00 02 5E 01 // Skip frame Enable
					15 00 00 40 00 00 02 60 00 // Normal mode1=120Hz
					15 00 00 40 00 00 02 61 02 //AOD in Mode3=30Hz
					15 00 00 40 00 00 02 6D 01 // IRC enable
					15 00 00 40 00 00 02 35 00 // TE on
					15 00 00 00 00 00 02 53 20 // BC On

					// 90Hz
					39 00 00 40 00 00 04 FF 5A A5 00
					15 00 00 00 00 00 02 60 04
					15 00 00 00 78 00 02 11 00
					39 00 00 40 00 00 04 FF 5A A5 49
					39 00 00 40 00 00 0C 80 00 01 09 11 21 41 81 C1 01 00 01
					39 00 00 40 00 00 11 81 01 00 BD 00 18 01 41 02 42 02 A6 03 8B 05 DD 06
					39 00 00 40 00 00 13 82 01 00 BD 00 18 01 41 02 42 02 A6 03 8B 05 DD 06 00 00
					15 00 00 40 00 00 02 83 07
					15 00 00 40 00 00 02 84 0A
					39 00 00 40 00 00 04 85 80 00 02
					39 00 00 40 00 00 04 86 80 00 02
					39 00 00 40 00 00 04 A0 40 40 40
					39 00 00 40 00 00 04 A1 40 40 40
					39 00 00 40 00 00 04 A2 40 40 40
					15 00 00 40 00 00 02 A6 3F
					15 00 00 40 00 00 02 A7 03
					15 00 00 40 00 00 02 AD 01
					15 00 00 40 00 00 02 AE 00
					15 00 00 40 00 00 02 AF 00
					15 00 00 40 00 00 02 D9 02
					15 00 00 40 00 00 02 DA F7
					15 00 00 40 00 00 02 DB 9C
					15 00 00 40 00 00 02 DC 03
					15 00 00 40 00 00 02 DF 06
					15 00 00 40 00 00 02 E0 01
					39 00 00 40 00 00 04 FF 5A A5 5A
					39 00 00 40 00 00 04 80 03 D0 00
					39 00 00 40 00 00 04 81 5D D0 40
					39 00 00 40 00 00 04 82 0F 04 0B
					39 00 00 40 00 00 04 83 6D 80 0C
					39 00 00 40 00 00 04 84 50 20 4A
					39 00 00 40 00 00 04 85 18 10 2D
					39 00 00 40 00 00 04 86 7E 80 0E
					39 00 00 40 00 00 04 87 1D 13 17
					39 00 00 40 00 00 04 88 10 0F 0F
					39 00 00 40 00 00 04 89 0C 0A 06
					39 00 00 40 00 00 04 8A 7F 14 F0
					39 00 00 40 00 00 04 8B 1A 15 1B
					39 00 00 40 00 00 04 8C 18 12 1A
					39 00 00 40 00 00 04 8D 18 11 18
					39 00 00 40 00 00 04 8E 09 06 0A
					39 00 00 40 00 00 04 8F 7F 46 F6
					39 00 00 40 00 00 04 90 1C 14 1D
					39 00 00 40 00 00 04 91 1A 12 1B
					39 00 00 40 00 00 04 92 18 0A 19
					39 00 00 40 00 00 04 93 15 06 16
					39 00 00 40 00 00 04 94 0C 02 0D
					39 00 00 40 00 00 04 95 57 1D 03
					39 00 00 40 00 00 04 96 18 10 1A
					39 00 00 40 00 00 04 97 10 0F 12
					39 00 00 40 00 00 04 98 10 07 10
					39 00 00 40 00 00 04 99 0C 0A 0F
					39 00 00 40 00 00 04 9A 04 03 0A
					39 00 00 40 00 00 04 9B 03 01 03
					39 00 00 40 00 00 04 9C 52 3E 2D
					39 00 00 40 00 00 04 9D 34 32 2D
					39 00 00 40 00 00 04 9E 23 20 22
					39 00 00 40 00 00 04 9F 1D 1A 1D
					39 00 00 40 00 00 04 A0 16 12 16
					39 00 00 40 00 00 04 A1 0A 08 09
					39 00 00 40 00 00 04 A2 07 03 05
					39 00 00 40 00 00 04 A3 06 01 03
					39 00 00 40 00 00 04 A4 02 D0 00
					39 00 00 40 00 00 04 A5 14 DD 0F
					39 00 00 40 00 00 04 A6 0A E4 0C
					39 00 00 40 00 00 04 A7 4A 80 D8
					39 00 00 40 00 00 04 A8 05 02 07
					39 00 00 40 00 00 04 A9 03 00 05
					39 00 00 40 00 00 04 AA 24 80 8F
					39 00 00 40 00 00 04 AB 0A 06 09
					39 00 00 40 00 00 04 AC 07 05 07
					39 00 00 40 00 00 04 AD 03 00 05
					39 00 00 40 00 00 04 AE 32 03 04
					39 00 00 40 00 00 04 AF 13 10 12
					39 00 00 40 00 00 04 B0 10 06 0D
					39 00 00 40 00 00 04 B1 0E 04 0C
					39 00 00 40 00 00 04 B2 03 01 05
					39 00 00 40 00 00 04 B3 2A 16 02
					39 00 00 40 00 00 04 B4 0E 0C 10
					39 00 00 40 00 00 04 B5 0D 0A 0E
					39 00 00 40 00 00 04 B6 0A 07 0A
					39 00 00 40 00 00 04 B7 07 05 0B
					39 00 00 40 00 00 04 B8 05 04 06
					39 00 00 40 00 00 04 B9 1F 10 1D
					39 00 00 40 00 00 04 BA 18 0F 12
					39 00 00 40 00 00 04 BB 13 0D 0A
					39 00 00 40 00 00 04 BC 0E 08 0A
					39 00 00 40 00 00 04 BD 09 06 0C
					39 00 00 40 00 00 04 BE 07 05 08
					39 00 00 40 00 00 04 BF 04 04 06
					39 00 00 40 00 00 04 C0 37 23 2F
					39 00 00 40 00 00 04 C1 27 1F 1F
					39 00 00 40 00 00 04 C2 1D 18 0D
					39 00 00 40 00 00 04 C3 1A 12 08
					39 00 00 40 00 00 04 C4 12 10 06
					39 00 00 40 00 00 04 C5 0A 07 03
					39 00 00 40 00 00 04 C6 08 04 02
					39 00 00 40 00 00 04 C7 03 02 01
					39 00 00 40 00 00 04 C8 40 06 0A
					39 00 00 40 00 00 04 C9 25 00 12
					39 00 00 40 00 00 04 CA 16 00 06
					39 00 00 40 00 00 04 CB 5A 00 00
					39 00 00 40 00 00 04 CC 06 01 06
					39 00 00 40 00 00 04 CD 03 00 05
					39 00 00 40 00 00 04 CE 30 00 00
					39 00 00 40 00 00 04 CF 10 04 06
					39 00 00 40 00 00 04 D0 0D 02 0E
					39 00 00 40 00 00 04 D1 06 00 0A
					39 00 00 40 00 00 04 D2 20 02 08
					39 00 00 40 00 00 04 D3 0D 04 06
					39 00 00 40 00 00 04 D4 08 00 05
					39 00 00 40 00 00 04 D5 06 00 03
					39 00 00 40 00 00 04 D6 05 00 01
					39 00 00 40 00 00 04 D7 26 15 16
					39 00 00 40 00 00 04 D8 12 0D 13
					39 00 00 40 00 00 04 D9 10 0A 12
					39 00 00 40 00 00 04 DA 0D 09 08
					39 00 00 40 00 00 04 DB 07 05 07
					39 00 00 40 00 00 04 DC 04 03 05
					39 00 00 40 00 00 04 DD 26 2A 26
					39 00 00 40 00 00 04 DE 20 28 23
					39 00 00 40 00 00 04 DF 16 1A 1E
					39 00 00 40 00 00 04 E0 12 16 14
					39 00 00 40 00 00 04 E1 0D 0F 0E
					39 00 00 40 00 00 04 E2 03 04 02
					39 00 00 40 00 00 04 E3 02 03 01
					39 00 00 40 00 00 04 E4 34 23 14
					39 00 00 40 00 00 04 E5 16 13 00
					39 00 00 40 00 00 04 E6 08 0D 00
					39 00 00 40 00 00 04 E7 06 0A 00
					39 00 00 40 00 00 04 E8 05 08 00
					39 00 00 40 00 00 04 E9 03 05 00
					39 00 00 40 00 00 04 EA 02 04 00
					39 00 00 40 00 00 04 EB 00 02 00
					39 00 00 40 00 00 04 FF 5A A5 5B
					39 00 00 40 00 00 04 80 05 00 00
					39 00 00 40 00 00 04 81 2A FA 10
					39 00 00 40 00 00 04 82 04 00 01
					39 00 00 40 00 00 04 83 2C FC 15
					39 00 00 40 00 00 04 84 08 01 03
					39 00 00 40 00 00 04 85 03 01 02
					39 00 00 40 00 00 04 86 0D 08 0E
					39 00 00 40 00 00 04 87 05 03 02
					39 00 00 40 00 00 04 88 04 02 03
					39 00 00 40 00 00 04 89 03 00 01
					39 00 00 40 00 00 04 8A 16 03 06
					39 00 00 40 00 00 04 8B 04 03 03
					39 00 00 40 00 00 04 8C 02 02 02
					39 00 00 40 00 00 04 8D 01 00 01
					39 00 00 40 00 00 04 8E 00 00 00
					39 00 00 40 00 00 04 8F 24 18 1B
					39 00 00 40 00 00 04 90 18 1C 1A
					39 00 00 40 00 00 04 91 14 16 14
					39 00 00 40 00 00 04 92 10 0F 11
					39 00 00 40 00 00 04 93 0A 08 0B
					39 00 00 40 00 00 04 94 05 06 04
					39 00 00 40 00 00 04 95 25 1D 1E
					39 00 00 40 00 00 04 96 16 18 1A
					39 00 00 40 00 00 04 97 12 14 16
					39 00 00 40 00 00 04 98 10 11 12
					39 00 00 40 00 00 04 99 0A 0C 0D
					39 00 00 40 00 00 04 9A 07 08 0A
					39 00 00 40 00 00 04 9B 05 06 07
					39 00 00 40 00 00 04 9C 38 2C 44
					39 00 00 40 00 00 04 9D 36 2A 40
					39 00 00 40 00 00 04 9E 32 24 3A
					39 00 00 40 00 00 04 9F 20 1A 2A
					39 00 00 40 00 00 04 A0 1A 16 1F
					39 00 00 40 00 00 04 A1 16 10 14
					39 00 00 40 00 00 04 A2 07 08 07
					39 00 00 40 00 00 04 A3 05 06 06
					39 00 00 40 00 00 04 A4 06 00 00
					39 00 00 40 00 00 04 A5 10 09 02
					39 00 00 40 00 00 04 A6 06 00 02
					39 00 00 40 00 00 04 A7 0F 08 04
					39 00 00 40 00 00 04 A8 06 02 07
					39 00 00 40 00 00 04 A9 05 01 06
					39 00 00 40 00 00 04 AA 10 02 07
					39 00 00 40 00 00 04 AB 04 02 03
					39 00 00 40 00 00 04 AC 03 01 02
					39 00 00 40 00 00 04 AD 02 00 04
					39 00 00 40 00 00 04 AE 1A 06 09
					39 00 00 40 00 00 04 AF 09 06 09
					39 00 00 40 00 00 04 B0 08 05 07
					39 00 00 40 00 00 04 B1 07 03 05
					39 00 00 40 00 00 04 B2 04 01 03
					39 00 00 40 00 00 04 B3 1F 13 16
					39 00 00 40 00 00 04 B4 18 13 19
					39 00 00 40 00 00 04 B5 15 12 17
					39 00 00 40 00 00 04 B6 11 0D 13
					39 00 00 40 00 00 04 B7 0A 08 0D
					39 00 00 40 00 00 04 B8 04 06 07
					39 00 00 40 00 00 04 B9 26 1D 23
					39 00 00 40 00 00 04 BA 1A 18 1C
					39 00 00 40 00 00 04 BB 14 10 15
					39 00 00 40 00 00 04 BC 10 13 12
					39 00 00 40 00 00 04 BD 0B 0F 0F
					39 00 00 40 00 00 04 BE 04 05 04
					39 00 00 40 00 00 04 BF 03 02 03
					39 00 00 40 00 00 04 C0 3C 30 4C
					39 00 00 40 00 00 04 C1 3A 2A 40
					39 00 00 40 00 00 04 C2 32 24 3A
					39 00 00 40 00 00 04 C3 20 1D 2C
					39 00 00 40 00 00 04 C4 1A 16 1F
					39 00 00 40 00 00 04 C5 16 10 14
					39 00 00 40 00 00 04 C6 05 06 08
					39 00 00 40 00 00 04 C7 04 05 06
					39 00 00 40 00 00 04 C8 04 00 00
					39 00 00 40 00 00 04 C9 18 0D 10
					39 00 00 40 00 00 04 CA 18 00 02
					39 00 00 40 00 00 04 CB 0C 04 04
					39 00 00 40 00 00 04 CC 03 02 01
					39 00 00 40 00 00 04 CD 02 01 00
					39 00 00 40 00 00 04 CE 06 03 08
					39 00 00 40 00 00 04 CF 04 02 04
					39 00 00 40 00 00 04 D0 03 01 03
					39 00 00 40 00 00 04 D1 02 00 00
					39 00 00 40 00 00 04 D2 0E 0A 10
					39 00 00 40 00 00 04 D3 0A 08 0D
					39 00 00 40 00 00 04 D4 07 05 0A
					39 00 00 40 00 00 04 D5 04 03 07
					39 00 00 40 00 00 04 D6 03 01 06
					39 00 00 40 00 00 04 D7 18 12 22
					39 00 00 40 00 00 04 D8 16 10 1A
					39 00 00 40 00 00 04 D9 12 0A 14
					39 00 00 40 00 00 04 DA 0D 08 12
					39 00 00 40 00 00 04 DB 06 06 0C
					39 00 00 40 00 00 04 DC 02 04 03
					39 00 00 40 00 00 04 DD 2C 28 34
					39 00 00 40 00 00 04 DE 28 22 30
					39 00 00 40 00 00 04 DF 20 18 2A
					39 00 00 40 00 00 04 E0 16 14 1A
					39 00 00 40 00 00 04 E1 0A 08 0D
					39 00 00 40 00 00 04 E2 03 03 03
					39 00 00 40 00 00 04 E3 02 02 02
					39 00 00 40 00 00 04 E4 3C 34 40
					39 00 00 40 00 00 04 E5 3A 2A 40
					39 00 00 40 00 00 04 E6 32 24 3A
					39 00 00 40 00 00 04 E7 20 1D 2C
					39 00 00 40 00 00 04 E8 1A 16 1F
					39 00 00 40 00 00 04 E9 16 10 14
					39 00 00 40 00 00 04 EA 03 02 03
					39 00 00 40 00 00 04 EB 04 05 06
					39 00 00 40 00 00 04 FF 5A A5 5C
					39 00 00 40 00 00 04 80 03 F4 FA
					39 00 00 40 00 00 04 81 05 00 02
					39 00 00 40 00 00 04 82 02 01 03
					39 00 00 40 00 00 04 83 09 04 06
					39 00 00 40 00 00 04 84 05 02 05
					39 00 00 40 00 00 04 85 04 01 04
					39 00 00 40 00 00 04 86 08 07 05
					39 00 00 40 00 00 04 87 07 05 0A
					39 00 00 40 00 00 04 88 04 04 04
					39 00 00 40 00 00 04 89 02 02 02
					39 00 00 40 00 00 04 8A 0C 08 0F
					39 00 00 40 00 00 04 8B 0A 07 0C
					39 00 00 40 00 00 04 8C 09 06 0A
					39 00 00 00 00 00 04 8D 06 05 08
					39 00 00 40 00 00 04 8E 04 03 05
					39 00 00 40 00 00 04 8F 23 1A 26
					39 00 00 40 00 00 04 90 1C 14 1D
					39 00 00 40 00 00 04 91 12 0A 18
					39 00 00 40 00 00 04 92 0D 07 14
					39 00 00 40 00 00 04 93 06 07 0A
					39 00 00 40 00 00 04 94 02 04 03
					39 00 00 40 00 00 04 95 34 32 3A
					39 00 00 40 00 00 04 96 2B 28 34
					39 00 00 40 00 00 04 97 26 24 2A
					39 00 00 40 00 00 04 98 16 14 1A
					39 00 00 40 00 00 04 99 0A 08 0D
					39 00 00 40 00 00 04 9A 03 03 02
					39 00 00 40 00 00 04 9B 02 02 02
					39 00 00 40 00 00 04 9C 44 3E 54
					39 00 00 40 00 00 04 9D 3A 2A 40
					39 00 00 40 00 00 04 9E 34 26 3A
					39 00 00 40 00 00 04 9F 20 1D 2C
					39 00 00 40 00 00 04 A0 1A 16 1F
					39 00 00 40 00 00 04 A1 16 10 14
					39 00 00 40 00 00 04 A2 03 02 03
					39 00 00 40 00 00 04 A3 04 05 06
					39 00 00 40 00 00 04 A4 04 02 02
					39 00 00 40 00 00 04 A5 06 03 03
					39 00 00 40 00 00 04 A6 02 01 01
					39 00 00 40 00 00 04 A7 03 02 02
					39 00 00 40 00 00 04 A8 02 01 02
					39 00 00 40 00 00 04 A9 02 01 02
					39 00 00 40 00 00 04 AA 05 05 06
					39 00 00 40 00 00 04 AB 04 04 05
					39 00 00 40 00 00 04 AC 03 03 04
					39 00 00 40 00 00 04 AD 02 02 03
					39 00 00 40 00 00 04 AE 08 04 08
					39 00 00 40 00 00 04 AF 06 03 07
					39 00 00 40 00 00 04 B0 05 02 06
					39 00 00 40 00 00 04 B1 03 01 05
					39 00 00 40 00 00 04 B2 02 00 04
					39 00 00 40 00 00 04 B3 25 23 24
					39 00 00 40 00 00 04 B4 23 20 21
					39 00 00 40 00 00 04 B5 13 0D 14
					39 00 00 40 00 00 04 B6 0E 0A 10
					39 00 00 40 00 00 04 B7 06 08 0A
					39 00 00 40 00 00 04 B8 02 04 03
					39 00 00 40 00 00 04 B9 34 31 37
					39 00 00 40 00 00 04 BA 2B 28 34
					39 00 00 40 00 00 04 BB 26 24 2A
					39 00 00 40 00 00 04 BC 16 15 1A
					39 00 00 40 00 00 04 BD 0A 08 0D
					39 00 00 40 00 00 04 BE 02 03 02
					39 00 00 40 00 00 04 BF 02 01 02
					39 00 00 40 00 00 04 C0 35 33 28
					39 00 00 40 00 00 04 C1 34 2A 24
					39 00 00 40 00 00 04 C2 34 26 1C
					39 00 00 40 00 00 04 C3 20 1D 18
					39 00 00 40 00 00 04 C4 1A 16 16
					39 00 00 40 00 00 04 C5 16 10 14
					39 00 00 40 00 00 04 C6 03 02 03
					39 00 00 40 00 00 04 C7 04 05 06
					39 00 00 40 00 00 04 C8 08 04 06
					39 00 00 40 00 00 04 C9 08 04 06
					39 00 00 40 00 00 04 CA 07 03 05
					39 00 00 40 00 00 04 CB 07 03 05
					39 00 00 40 00 00 04 CC 00 00 00
					39 00 00 40 00 00 04 CD 00 00 00
					39 00 00 40 00 00 04 CE 00 00 00
					39 00 00 00 00 00 04 CF 00 00 00
					15 00 00 00 14 00 02 29 00
				];
				qcom,mdss-dsi-off-command=[
					05 00 00 00 14 00 01 28
					05 00 00 00 78 00 01 10
				];
				oplus,dsi-panel-switch-low-pwm-aod-on-command = [
				];
				oplus,dsi-panel-switch-low-pwm-aod-off-command = [
				];
				qcom,mdss-dsi-timing-switch-compensation-command = [
					39 00 00 40 00 00 04 FF 5A A5 08 // PAGE 08
					15 00 00 40 00 00 02 98 02 //Queue Start Close CDM FIFO Reset
					39 00 00 40 00 00 04 FF 5A A5 4F //CMD_Q
					15 00 00 40 00 00 02 80 01 //Enable MSFC
					15 00 00 40 00 00 02 81 06 //04 Rising,05Falling
					15 00 00 40 00 00 02 88 78 // cmd core0 queue start
					//queue1_str
					39 00 00 40 00 00 04 FF 5A A5 24
					39 00 00 40 00 00 06 C9 00 00 00 10 00 //0  1
					39 00 00 40 00 00 04 FE 30 00 70 //3  7
					39 00 00 40 00 00 06 CA 00 B0 00 E0 01 //11 13
					39 00 00 40 00 00 04 FE 10 01 30 //15 19
					39 00 00 40 00 00 06 CB 01 70 01 C0 02 //23  27
					39 00 00 40 00 00 04 FE 30 02 90 //33  41
					39 00 00 40 00 00 06 CC 03 70 03 E0 04 //55 63
					39 00 00 40 00 00 04 FE F0 05 F0 //79  95
					39 00 00 40 00 00 06 CD 07 10 08 F0 0A //113 143
					39 00 00 40 00 00 04 FE F0 0B A0 //175 186
					39 00 00 40 00 00 06 CE 0D 30 0E 10 0E //211 225
					39 00 00 40 00 00 04 FE F0 0F F0 //239 255
					//queue1_end
					39 00 00 40 00 00 04 FF 5A A5 4F // PAGE 4F
					15 00 00 40 00 00 02 8A 78
					//queue2_str
					39 00 00 40 00 00 04 FF 5A A5 00 // PAGE 00
					15 00 00 40 00 00 02 60 04 //90hz
					15 00 00 40 00 00 02 7D 01
					39 00 00 40 00 00 04 FF 5A A5 20
					15 00 00 40 00 00 02 BB 00 //sync setting
					39 00 00 40 00 00 04 FF 5A A5 24
					39 00 00 40 00 00 06 C9 00 00 00 10 00
					39 00 00 40 00 00 04 FE 30 00 70
					39 00 00 40 00 00 06 CA 00 B0 00 D0 00 //11 13
					39 00 00 40 00 00 04 FE F0 01 30 //15 19
					39 00 00 40 00 00 06 CB 01 70 01 B0 02 //23  27
					39 00 00 40 00 00 04 FE 10 02 90 //33  41
					39 00 00 40 00 00 06 CC 03 70 03 F0 04 //55 63 79
					39 00 00 40 00 00 04 FE F0 05 F0 //95
					39 00 00 40 00 00 06 CD 07 10 08 F0 0A //113 143
					39 00 00 40 00 00 04 FE F0 0B A0 //175 186
					39 00 00 40 00 00 06 CE 0D 30 0E 10 0E //225 239
					39 00 00 40 00 00 04 FE F0 0F F0
					//queue2_end
					39 00 00 40 00 00 04 FF 5A A5 53
					39 00 00 40 00 00 06 90 44 00 00 03 F0
					39 00 00 40 00 00 06 FE 44 00 00 04 00
					39 00 00 40 00 00 06 FE 44 00 00 04 00
					39 00 00 40 00 00 06 FE 44 00 00 04 00
					15 00 00 40 00 00 02 F0 01 //MURA_TUNNING
					15 00 00 40 00 00 02 00 00
					15 00 00 40 00 00 02 00 00
					15 00 00 40 00 00 02 00 00
					15 00 00 40 00 00 02 00 00
					15 00 00 40 00 00 02 00 00
					15 00 00 40 00 00 02 00 00
					15 00 00 40 00 00 02 00 00
					15 00 00 40 00 00 02 00 00
					39 00 00 40 00 00 04 FF 5A A5 63
					39 00 00 40 00 00 06 F1 20 20 20 20 20
					39 00 00 40 00 00 06 FE 20 00 00 00 00
					39 00 00 40 00 00 06 FE 00 00 00 00 00
					15 00 00 40 00 00 02 FE 00
					15 00 00 40 00 00 02 00 00
					15 00 00 40 00 00 02 00 00
					15 00 00 40 00 00 02 00 00
					15 00 00 40 00 00 02 00 00
					15 00 00 40 00 00 02 00 00
					39 00 00 40 00 00 06 F2 00 00 00 00 00
					39 00 00 40 00 00 06 FE 00 00 00 00 00
					39 00 00 40 00 00 06 FE 00 00 00 00 00
					15 00 00 40 00 00 02 FE 00
					15 00 00 40 00 00 02 00 00
					15 00 00 40 00 00 02 00 00
					15 00 00 40 00 00 02 00 00
					15 00 00 40 00 00 02 00 00
					15 00 00 40 00 00 02 00 00
					39 00 00 40 00 00 06 F3 00 00 00 00 00
					39 00 00 40 00 00 06 FE 00 20 20 20 20
					39 00 00 40 00 00 06 FE 00 00 00 00 00
					15 00 00 40 00 00 02 FE 00
					15 00 00 40 00 00 02 00 00
					15 00 00 40 00 00 02 00 00
					15 00 00 40 00 00 02 00 00
					15 00 00 40 00 00 02 00 00
					15 00 00 40 00 00 02 00 00
					39 00 00 40 00 00 06 F4 00 00 00 00 00
					39 00 00 40 00 00 06 FE 00 F0 F0 F0 F0
					39 00 00 40 00 00 06 FE 00 00 00 00 00
					15 00 00 40 00 00 02 FE 00
					15 00 00 40 00 00 02 00 00
					15 00 00 40 00 00 02 00 00
					15 00 00 40 00 00 02 00 00
					15 00 00 40 00 00 02 00 00
					15 00 00 40 00 00 02 00 00
					15 00 00 40 00 00 02 00 00
					15 00 00 40 00 00 02 00 00
					15 00 00 40 00 00 02 00 00
					39 00 00 40 00 00 04 FF 5A A5 53
					15 00 00 40 00 00 02 F0 00
					39 00 00 40 00 00 04 FF 5A A5 00
					39 00 00 40 00 00 04 FF 5A A5 08 //ALL Done open CDM FIFO Reset
					15 00 00 40 00 00 02 98 A6
					39 00 00 40 00 00 04 FF 5A A5 00 //Dummy write
					15 00 00 40 00 00 02 00 00
					39 00 00 40 00 00 04 FF 5A A5 4F // PAGE 4F
					15 00 00 40 00 00 02 8B 78 // cmd core 0 queue all done
					39 00 00 00 00 00 04 FF 5A A5 00
					/* wait for te and blocking one frame */
					39 00 00 20 00 00 04 FF 5A A5 00
				];
				qcom,mdss-dsi-hbm-off-command = [
				];
				qcom,mdss-dsi-hbm-on-command = [
				];
				qcom,mdss-dsi-change-voltage-before-bl-0-command = [
				];
				qcom,mdss-dsi-lhbm-pressed-icon-on-command = [
				];
				qcom,mdss-dsi-lhbm-pressed-icon-off-command = [
				];
				qcom,mdss-dsi-aod-off-pwm-mode2-command = [
				];
				qcom,mdss-dsi-aod-off-compensation-command = [
				];
				qcom,mdss-dsi-aod-off-compensation-onepulse-command = [
				];
				/* pwm */
				qcom,mdss-dsi-pwm-state-l3tol2-command = [
				];
				qcom,mdss-dsi-pwm-state-l2tol3-command = [
				];
				qcom,mdss-dsi-pwm-switch-mode0-command= [
				];
				qcom,mdss-dsi-pwm-switch-mode2-command = [
				];
				qcom,mdss-dsi-timming-switch-pwm-mode2-command = [
				];
				qcom,mdss-dsi-pwm-switch-mode2-panel-on-command = [
				];
				qcom,mdss-dsi-pwm-state-l1tol3-command = [
				];
				qcom,mdss-dsi-pwm-state-l3tol1-command = [
				];
				qcom,mdss-dsi-hbm-max-command = [
				];
				qcom,mdss-dsi-hbm-exit-max-command = [
				];
				mdss-dsi-timing-switch-command-state = "dsi_hs_sync1_mode";
				qcom,mdss-dsi-lp1-command-state = "dsi_hs_sync1_mode";
				qcom,mdss-dsi-nolp-command-state = "dsi_hs_sync1_mode";
				oplus,dsi-panel-switch-low-pwm-aod-on-command-state = "dsi_hs_sync1_mode";
				oplus,dsi-panel-switch-low-pwm-aod-off-command-state = "dsi_hs_sync1_mode";
				qcom,mdss-dsi-aod-off-pwm-mode2-command-state = "dsi_hs_sync1_mode";
				qcom,mdss-dsi-aod-off-compensation-command-state = "dsi_lp_sync1_mode";
				qcom,mdss-dsi-aod-off-compensation-onepulse-command-state = "dsi_lp_sync1_mode";
				qcom,mdss-dsi-nolp-hpwm-command-state = "dsi_lp_sync1_mode";
				qcom,mdss-dsi-hbm-on-command-state = "dsi_hs_sync1_mode";
				qcom,mdss-dsi-hbm-off-command-state = "dsi_hs_sync1_mode";
				qcom,mdss-dsi-panel-read-register-open-state = "dsi_lp_mode";
				qcom,mdss-dsi-panel-read-register-close-state = "dsi_lp_mode";
				qcom,mdss-dsi-lhbm-pressed-icon-gamma-command-state = "dsi_lp_mode";
				qcom,mdss-dsi-lhbm-pressed-icon-grayscale-command-state = "dsi_lp_mode";
				qcom,mdss-dsi-lhbm-pressed-icon-on-command-state = "dsi_lp_mode";
				qcom,mdss-dsi-lhbm-pressed-icon-off-command-state = "dsi_lp_mode";
				qcom,mdss-dsi-lhbm-dbv-alpha-command-state = "dsi_hs_mode";

				qcom,mdss-dsi-reset-scanline-command-state = "dsi_hs_mode";
				qcom,mdss-dsi-recovery-scanline-command-state = "dsi_hs_mode";

				qcom,mdss-dsi-osc-track-on-command-state = "dsi_hs_mode";
				qcom,mdss-dsi-osc-track-off-command-state = "dsi_hs_mode";
				qcom,mdss-dsi-hbm-max-command-state = "dsi_hs_mode";
				qcom,mdss-dsi-hbm-exit-max-command-state = "dsi_hs_mode";

				qcom,lm-split = <608 608>;
				qcom,compression-mode = "dsc";
				qcom,mdss-dsc-encoders = <2>;
				qcom,mdss-dsc-slice-height = <20>;
				qcom,mdss-dsc-slice-width = <608>;
				qcom,mdss-dsc-slice-per-pkt = <2>;
				qcom,mdss-dsc-bit-per-component = <10>;
				qcom,mdss-dsc-bit-per-pixel = <8>;
				qcom,mdss-dsc-block-prediction-enable;
			};
			timing@sdc_fhd_60 {
				#include "dsi-panel-AA616-P-7-A0020-common.dtsi"
				#include "dsi-panel-AA616-P-7-A0020-loading-effect.dtsi"
				qcom,mdss-mdp-transfer-time-us = <6680>;
				qcom,mdss-dsi-panel-jitter = <0x4 0x1>;
				qcom,mdss-dsc-version = <0x12>;
				qcom,mdss-dsi-timing-default;
				qcom,mdss-dsi-panel-framerate = <60>;
				qcom,mdss-dsi-panel-clockrate = <1107000000>;
				qcom,mdss-dsi-panel-width = <1216>;
				qcom,mdss-dsi-panel-height = <2640>;

				qcom,mdss-dsi-h-front-porch = <44>;
				qcom,mdss-dsi-h-back-porch = <16>;
				qcom,mdss-dsi-h-pulse-width = <16>;
				qcom,mdss-dsi-v-back-porch = <24>;
				qcom,mdss-dsi-v-front-porch = <88>;
				qcom,mdss-dsi-v-pulse-width = <2>;
				qcom,mdss-dsi-h-sync-pulse = <0>;

				/* Send 51 cmd in the second half frame at 60Hz timing */
				oplus,apollo-panel-async-bl-delay = <9000>;
				oplus,apollo-panel-vsync-width = <9000>;

				qcom,mdss-dsi-timing-switch-command = [
					39 00 00 40 00 00 04 FF 5A A5 08 // PAGE 08
					15 00 00 40 00 00 02 98 02 //Queue Start Close CDM FIFO Reset
					39 00 00 40 00 00 04 FF 5A A5 4F //CMD_Q
					15 00 00 40 00 00 02 80 01 //Enable MSFC
					15 00 00 40 00 00 02 81 06 //04 Rising,05Falling
					15 00 00 40 00 00 02 88 78 // cmd core0 queue start
					39 00 00 40 00 00 04 FF 5A A5 53
					39 00 00 40 00 00 06 90 44 00 00 03 70
					39 00 00 40 00 00 06 FE 44 00 00 04 00
					39 00 00 40 00 00 06 FE 44 00 00 04 00
					39 00 00 40 00 00 06 FE 44 00 00 04 00
					15 00 00 40 00 00 02 F0 01 //MURA_TUNNING
					15 00 00 40 00 00 02 00 00
					15 00 00 40 00 00 02 00 00
					15 00 00 40 00 00 02 00 00
					15 00 00 40 00 00 02 00 00
					15 00 00 40 00 00 02 00 00
					15 00 00 40 00 00 02 00 00
					15 00 00 40 00 00 02 00 00
					15 00 00 40 00 00 02 00 00
					39 00 00 40 00 00 04 FF 5A A5 63
					39 00 00 40 00 00 06 F1 20 20 20 20 20
					39 00 00 40 00 00 06 FE 20 00 00 00 00
					39 00 00 40 00 00 06 FE 00 00 00 00 00
					15 00 00 40 00 00 02 FE 00
					15 00 00 40 00 00 02 00 00
					15 00 00 40 00 00 02 00 00
					15 00 00 40 00 00 02 00 00
					15 00 00 40 00 00 02 00 00
					15 00 00 40 00 00 02 00 00
					39 00 00 40 00 00 06 F2 00 00 00 00 00
					39 00 00 40 00 00 06 FE 00 00 00 00 00
					39 00 00 40 00 00 06 FE 00 00 00 00 00
					15 00 00 40 00 00 02 FE 00
					15 00 00 40 00 00 02 00 00
					15 00 00 40 00 00 02 00 00
					15 00 00 40 00 00 02 00 00
					15 00 00 40 00 00 02 00 00
					15 00 00 40 00 00 02 00 00
					39 00 00 40 00 00 06 F3 00 00 00 00 00
					39 00 00 40 00 00 06 FE 00 20 20 20 20
					39 00 00 40 00 00 06 FE 00 00 00 00 00
					15 00 00 40 00 00 02 FE 00
					15 00 00 40 00 00 02 00 00
					15 00 00 40 00 00 02 00 00
					15 00 00 40 00 00 02 00 00
					15 00 00 40 00 00 02 00 00
					15 00 00 40 00 00 02 00 00
					39 00 00 40 00 00 06 F4 00 00 00 00 00
					39 00 00 40 00 00 06 FE 00 F0 F0 F0 F0
					39 00 00 40 00 00 06 FE 00 00 00 00 00
					15 00 00 40 00 00 02 FE 00
					15 00 00 40 00 00 02 00 00
					15 00 00 40 00 00 02 00 00
					15 00 00 40 00 00 02 00 00
					15 00 00 40 00 00 02 00 00
					15 00 00 40 00 00 02 00 00
					15 00 00 40 00 00 02 00 00
					15 00 00 40 00 00 02 00 00
					15 00 00 40 00 00 02 00 00
					39 00 00 40 00 00 04 FF 5A A5 53
					15 00 00 40 00 00 02 F0 00
					39 00 00 40 00 00 04 FF 5A A5 00 // PAGE 00
					15 00 00 40 00 00 02 60 05 //60Hz
					15 00 00 40 00 00 02 7D 00
					39 00 00 40 00 00 04 FF 5A A5 20
					15 00 00 40 00 00 02 BB 06 //sync Setting
					39 00 00 40 00 00 04 FF 5A A5 08 //ALL Done open CDM FIFO Reset
					15 00 00 40 00 00 02 98 A6
					39 00 00 40 00 00 04 FF 5A A5 00 //Dummy write
					15 00 00 40 00 00 02 00 00
					39 00 00 40 00 00 04 FF 5A A5 4F // PAGE 4F
					15 00 00 40 00 00 02 8B 78 // cmd core 0 queue all done
					39 00 00 00 00 00 04 FF 5A A5 00
				];
				qcom,mdss-dsi-on-command = [
					39 00 00 40 00 00 04 FF 5A A5 08
					15 00 00 40 00 00 02 C8 62
					39 00 00 40 00 00 04 FF 5A A5 21
					15 00 00 40 00 00 02 A4 38
					39 00 00 40 00 00 04 FF 5A A5 23
					15 00 00 40 00 00 02 85 15
					39 00 00 40 00 00 04 FF 5A A5 06
					15 00 00 40 00 00 02 C6 01
					39 00 00 40 00 00 04 FF 5A A5 08
					15 00 00 40 00 00 02 D2 05
					15 00 00 40 00 00 02 D3 01
					39 00 00 40 00 00 09 ED FF FF FF FF FF FF 45 FF
					39 00 00 40 00 00 09 EE FF FD FF FD F9 FA BE 76

					39 00 00 40 00 00 04 FF 5A A5 07
					15 00 00 40 00 00 02 8A 01
					39 00 00 40 00 00 03 8B 21 E0
					39 00 00 40 00 00 64 81 00 00 00 00 00 12 00 00 AB 21 00 0A 50 04 C0 00 14 02 60 02 60 01 55 01 D3 00 0A 01 08 00 33 00 0D 05 7A 19 5A 08 00 0B F0 07 10 20 00 06 0F 0F 33 0E 1C 2A 38 46 54 62 69 70 77 79 7B 7D 7E 00 82 11 40 19 C0 22 3E 32 7C 3A BA 3A F8 3B 38 3B 38 3B 76 4B 76 4B 74 4B 74 5B B4 73 F4 01 00 00 00 00 00
					15 00 00 40 00 00 02 91 03
					39 00 00 40 00 00 04 FF 5A A5 14
					15 00 00 40 00 00 02 80 00
					15 00 00 40 00 00 02 82 01
					39 00 00 40 00 00 04 FF 5A A5 17
					15 00 00 40 00 00 02 A0 0C
					39 00 00 40 00 00 04 FF 5A A5 13
					15 00 00 40 00 00 02 F9 3C
					39 00 00 40 00 00 04 FF 5A A5 22
					39 00 00 40 00 00 08 D8 00 F4 11 10 3E 17 17
					39 00 00 40 00 00 08 D9 00 F3 11 10 3E 17 17
					39 00 00 40 00 00 08 DA 00 EA 11 10 2B 16 16
					39 00 00 40 00 00 08 DB 00 E9 11 10 2B 16 16
					39 00 00 40 00 00 0A DC 84 94 BB 00 20 C4 A1 CC 10
					15 00 00 40 00 00 02 DD 01
					15 00 00 40 00 00 02 DE F1
					15 00 00 40 00 00 02 DF 80
					39 00 00 00 00 00 07 E0 02 00 5F 21 00 28

					39 00 00 40 00 00 04 FF 5A A5 00
					15 00 00 00 00 00 02 7D 00

					39 00 00 40 00 00 04 FF 5A A5 22
					39 00 00 40 00 00 08 D8 00 F6 11 10 38 17 17
					39 00 00 40 00 00 08 D9 00 F5 11 10 38 17 17
					39 00 00 40 00 00 08 DA 00 EA 11 10 2B 16 16
					39 00 00 40 00 00 08 DB 00 E9 11 10 2B 16 16
					39 00 00 40 00 00 0A DC 84 94 BB 00 20 C4 A1 CC 10
					15 00 00 40 00 00 02 DD 01
					15 00 00 40 00 00 02 DE F1
					15 00 00 40 00 00 02 DF 80
					39 00 00 40 00 00 07 E0 02 00 5F 21 00 28
					15 00 00 40 00 00 02 5E 01 // Skip frame Enable
					15 00 00 40 00 00 02 60 00 // Normal mode1=120Hz
					15 00 00 40 00 00 02 61 02 //AOD in Mode3=30Hz
					15 00 00 40 00 00 02 6D 01 // IRC enable
					15 00 00 40 00 00 02 35 00 // TE on
					15 00 00 00 00 00 02 53 20 // BC On

					// 60Hz
					39 00 00 40 00 00 04 FF 5A A5 00
					15 00 00 00 00 00 02 60 05
					15 00 00 00 78 00 02 11 00
					39 00 00 40 00 00 04 FF 5A A5 49
					39 00 00 40 00 00 0C 80 00 01 09 11 21 41 81 C1 01 00 01
					39 00 00 40 00 00 11 81 01 00 BD 00 18 01 41 02 42 02 A6 03 8B 05 DD 06
					39 00 00 40 00 00 13 82 01 00 BD 00 18 01 41 02 42 02 A6 03 8B 05 DD 06 00 00
					15 00 00 40 00 00 02 83 07
					15 00 00 40 00 00 02 84 0A
					39 00 00 40 00 00 04 85 80 00 02
					39 00 00 40 00 00 04 86 80 00 02
					39 00 00 40 00 00 04 A0 40 40 40
					39 00 00 40 00 00 04 A1 40 40 40
					39 00 00 40 00 00 04 A2 40 40 40
					15 00 00 40 00 00 02 A6 3F
					15 00 00 40 00 00 02 A7 03
					15 00 00 40 00 00 02 AD 01
					15 00 00 40 00 00 02 AE 00
					15 00 00 40 00 00 02 AF 00
					15 00 00 40 00 00 02 D9 02
					15 00 00 40 00 00 02 DA F7
					15 00 00 40 00 00 02 DB 9C
					15 00 00 40 00 00 02 DC 03
					15 00 00 40 00 00 02 DF 06
					15 00 00 40 00 00 02 E0 01
					39 00 00 40 00 00 04 FF 5A A5 5A
					39 00 00 40 00 00 04 80 03 D0 00
					39 00 00 40 00 00 04 81 5D D0 40
					39 00 00 40 00 00 04 82 0F 04 0B
					39 00 00 40 00 00 04 83 6D 80 0C
					39 00 00 40 00 00 04 84 50 20 4A
					39 00 00 40 00 00 04 85 18 10 2D
					39 00 00 40 00 00 04 86 7E 80 0E
					39 00 00 40 00 00 04 87 1D 13 17
					39 00 00 40 00 00 04 88 10 0F 0F
					39 00 00 40 00 00 04 89 0C 0A 06
					39 00 00 40 00 00 04 8A 7F 14 F0
					39 00 00 40 00 00 04 8B 1A 15 1B
					39 00 00 40 00 00 04 8C 18 12 1A
					39 00 00 40 00 00 04 8D 18 11 18
					39 00 00 40 00 00 04 8E 09 06 0A
					39 00 00 40 00 00 04 8F 7F 46 F6
					39 00 00 40 00 00 04 90 1C 14 1D
					39 00 00 40 00 00 04 91 1A 12 1B
					39 00 00 40 00 00 04 92 18 0A 19
					39 00 00 40 00 00 04 93 15 06 16
					39 00 00 40 00 00 04 94 0C 02 0D
					39 00 00 40 00 00 04 95 57 1D 03
					39 00 00 40 00 00 04 96 18 10 1A
					39 00 00 40 00 00 04 97 10 0F 12
					39 00 00 40 00 00 04 98 10 07 10
					39 00 00 40 00 00 04 99 0C 0A 0F
					39 00 00 40 00 00 04 9A 04 03 0A
					39 00 00 40 00 00 04 9B 03 01 03
					39 00 00 40 00 00 04 9C 52 3E 2D
					39 00 00 40 00 00 04 9D 34 32 2D
					39 00 00 40 00 00 04 9E 23 20 22
					39 00 00 40 00 00 04 9F 1D 1A 1D
					39 00 00 40 00 00 04 A0 16 12 16
					39 00 00 40 00 00 04 A1 0A 08 09
					39 00 00 40 00 00 04 A2 07 03 05
					39 00 00 40 00 00 04 A3 06 01 03
					39 00 00 40 00 00 04 A4 02 D0 00
					39 00 00 40 00 00 04 A5 14 DD 0F
					39 00 00 40 00 00 04 A6 0A E4 0C
					39 00 00 40 00 00 04 A7 4A 80 D8
					39 00 00 40 00 00 04 A8 05 02 07
					39 00 00 40 00 00 04 A9 03 00 05
					39 00 00 40 00 00 04 AA 24 80 8F
					39 00 00 40 00 00 04 AB 0A 06 09
					39 00 00 40 00 00 04 AC 07 05 07
					39 00 00 40 00 00 04 AD 03 00 05
					39 00 00 40 00 00 04 AE 32 03 04
					39 00 00 40 00 00 04 AF 13 10 12
					39 00 00 40 00 00 04 B0 10 06 0D
					39 00 00 40 00 00 04 B1 0E 04 0C
					39 00 00 40 00 00 04 B2 03 01 05
					39 00 00 40 00 00 04 B3 2A 16 02
					39 00 00 40 00 00 04 B4 0E 0C 10
					39 00 00 40 00 00 04 B5 0D 0A 0E
					39 00 00 40 00 00 04 B6 0A 07 0A
					39 00 00 40 00 00 04 B7 07 05 0B
					39 00 00 40 00 00 04 B8 05 04 06
					39 00 00 40 00 00 04 B9 1F 10 1D
					39 00 00 40 00 00 04 BA 18 0F 12
					39 00 00 40 00 00 04 BB 13 0D 0A
					39 00 00 40 00 00 04 BC 0E 08 0A
					39 00 00 40 00 00 04 BD 09 06 0C
					39 00 00 40 00 00 04 BE 07 05 08
					39 00 00 40 00 00 04 BF 04 04 06
					39 00 00 40 00 00 04 C0 37 23 2F
					39 00 00 40 00 00 04 C1 27 1F 1F
					39 00 00 40 00 00 04 C2 1D 18 0D
					39 00 00 40 00 00 04 C3 1A 12 08
					39 00 00 40 00 00 04 C4 12 10 06
					39 00 00 40 00 00 04 C5 0A 07 03
					39 00 00 40 00 00 04 C6 08 04 02
					39 00 00 40 00 00 04 C7 03 02 01
					39 00 00 40 00 00 04 C8 40 06 0A
					39 00 00 40 00 00 04 C9 25 00 12
					39 00 00 40 00 00 04 CA 16 00 06
					39 00 00 40 00 00 04 CB 5A 00 00
					39 00 00 40 00 00 04 CC 06 01 06
					39 00 00 40 00 00 04 CD 03 00 05
					39 00 00 40 00 00 04 CE 30 00 00
					39 00 00 40 00 00 04 CF 10 04 06
					39 00 00 40 00 00 04 D0 0D 02 0E
					39 00 00 40 00 00 04 D1 06 00 0A
					39 00 00 40 00 00 04 D2 20 02 08
					39 00 00 40 00 00 04 D3 0D 04 06
					39 00 00 40 00 00 04 D4 08 00 05
					39 00 00 40 00 00 04 D5 06 00 03
					39 00 00 40 00 00 04 D6 05 00 01
					39 00 00 40 00 00 04 D7 26 15 16
					39 00 00 40 00 00 04 D8 12 0D 13
					39 00 00 40 00 00 04 D9 10 0A 12
					39 00 00 40 00 00 04 DA 0D 09 08
					39 00 00 40 00 00 04 DB 07 05 07
					39 00 00 40 00 00 04 DC 04 03 05
					39 00 00 40 00 00 04 DD 26 2A 26
					39 00 00 40 00 00 04 DE 20 28 23
					39 00 00 40 00 00 04 DF 16 1A 1E
					39 00 00 40 00 00 04 E0 12 16 14
					39 00 00 40 00 00 04 E1 0D 0F 0E
					39 00 00 40 00 00 04 E2 03 04 02
					39 00 00 40 00 00 04 E3 02 03 01
					39 00 00 40 00 00 04 E4 34 23 14
					39 00 00 40 00 00 04 E5 16 13 00
					39 00 00 40 00 00 04 E6 08 0D 00
					39 00 00 40 00 00 04 E7 06 0A 00
					39 00 00 40 00 00 04 E8 05 08 00
					39 00 00 40 00 00 04 E9 03 05 00
					39 00 00 40 00 00 04 EA 02 04 00
					39 00 00 40 00 00 04 EB 00 02 00
					39 00 00 40 00 00 04 FF 5A A5 5B
					39 00 00 40 00 00 04 80 05 00 00
					39 00 00 40 00 00 04 81 2A FA 10
					39 00 00 40 00 00 04 82 04 00 01
					39 00 00 40 00 00 04 83 2C FC 15
					39 00 00 40 00 00 04 84 08 01 03
					39 00 00 40 00 00 04 85 03 01 02
					39 00 00 40 00 00 04 86 0D 08 0E
					39 00 00 40 00 00 04 87 05 03 02
					39 00 00 40 00 00 04 88 04 02 03
					39 00 00 40 00 00 04 89 03 00 01
					39 00 00 40 00 00 04 8A 16 03 06
					39 00 00 40 00 00 04 8B 04 03 03
					39 00 00 40 00 00 04 8C 02 02 02
					39 00 00 40 00 00 04 8D 01 00 01
					39 00 00 40 00 00 04 8E 00 00 00
					39 00 00 40 00 00 04 8F 24 18 1B
					39 00 00 40 00 00 04 90 18 1C 1A
					39 00 00 40 00 00 04 91 14 16 14
					39 00 00 40 00 00 04 92 10 0F 11
					39 00 00 40 00 00 04 93 0A 08 0B
					39 00 00 40 00 00 04 94 05 06 04
					39 00 00 40 00 00 04 95 25 1D 1E
					39 00 00 40 00 00 04 96 16 18 1A
					39 00 00 40 00 00 04 97 12 14 16
					39 00 00 40 00 00 04 98 10 11 12
					39 00 00 40 00 00 04 99 0A 0C 0D
					39 00 00 40 00 00 04 9A 07 08 0A
					39 00 00 40 00 00 04 9B 05 06 07
					39 00 00 40 00 00 04 9C 38 2C 44
					39 00 00 40 00 00 04 9D 36 2A 40
					39 00 00 40 00 00 04 9E 32 24 3A
					39 00 00 40 00 00 04 9F 20 1A 2A
					39 00 00 40 00 00 04 A0 1A 16 1F
					39 00 00 40 00 00 04 A1 16 10 14
					39 00 00 40 00 00 04 A2 07 08 07
					39 00 00 40 00 00 04 A3 05 06 06
					39 00 00 40 00 00 04 A4 06 00 00
					39 00 00 40 00 00 04 A5 10 09 02
					39 00 00 40 00 00 04 A6 06 00 02
					39 00 00 40 00 00 04 A7 0F 08 04
					39 00 00 40 00 00 04 A8 06 02 07
					39 00 00 40 00 00 04 A9 05 01 06
					39 00 00 40 00 00 04 AA 10 02 07
					39 00 00 40 00 00 04 AB 04 02 03
					39 00 00 40 00 00 04 AC 03 01 02
					39 00 00 40 00 00 04 AD 02 00 04
					39 00 00 40 00 00 04 AE 1A 06 09
					39 00 00 40 00 00 04 AF 09 06 09
					39 00 00 40 00 00 04 B0 08 05 07
					39 00 00 40 00 00 04 B1 07 03 05
					39 00 00 40 00 00 04 B2 04 01 03
					39 00 00 40 00 00 04 B3 1F 13 16
					39 00 00 40 00 00 04 B4 18 13 19
					39 00 00 40 00 00 04 B5 15 12 17
					39 00 00 40 00 00 04 B6 11 0D 13
					39 00 00 40 00 00 04 B7 0A 08 0D
					39 00 00 40 00 00 04 B8 04 06 07
					39 00 00 40 00 00 04 B9 26 1D 23
					39 00 00 40 00 00 04 BA 1A 18 1C
					39 00 00 40 00 00 04 BB 14 10 15
					39 00 00 40 00 00 04 BC 10 13 12
					39 00 00 40 00 00 04 BD 0B 0F 0F
					39 00 00 40 00 00 04 BE 04 05 04
					39 00 00 40 00 00 04 BF 03 02 03
					39 00 00 40 00 00 04 C0 3C 30 4C
					39 00 00 40 00 00 04 C1 3A 2A 40
					39 00 00 40 00 00 04 C2 32 24 3A
					39 00 00 40 00 00 04 C3 20 1D 2C
					39 00 00 40 00 00 04 C4 1A 16 1F
					39 00 00 40 00 00 04 C5 16 10 14
					39 00 00 40 00 00 04 C6 05 06 08
					39 00 00 40 00 00 04 C7 04 05 06
					39 00 00 40 00 00 04 C8 04 00 00
					39 00 00 40 00 00 04 C9 18 0D 10
					39 00 00 40 00 00 04 CA 18 00 02
					39 00 00 40 00 00 04 CB 0C 04 04
					39 00 00 40 00 00 04 CC 03 02 01
					39 00 00 40 00 00 04 CD 02 01 00
					39 00 00 40 00 00 04 CE 06 03 08
					39 00 00 40 00 00 04 CF 04 02 04
					39 00 00 40 00 00 04 D0 03 01 03
					39 00 00 40 00 00 04 D1 02 00 00
					39 00 00 40 00 00 04 D2 0E 0A 10
					39 00 00 40 00 00 04 D3 0A 08 0D
					39 00 00 40 00 00 04 D4 07 05 0A
					39 00 00 40 00 00 04 D5 04 03 07
					39 00 00 40 00 00 04 D6 03 01 06
					39 00 00 40 00 00 04 D7 18 12 22
					39 00 00 40 00 00 04 D8 16 10 1A
					39 00 00 40 00 00 04 D9 12 0A 14
					39 00 00 40 00 00 04 DA 0D 08 12
					39 00 00 40 00 00 04 DB 06 06 0C
					39 00 00 40 00 00 04 DC 02 04 03
					39 00 00 40 00 00 04 DD 2C 28 34
					39 00 00 40 00 00 04 DE 28 22 30
					39 00 00 40 00 00 04 DF 20 18 2A
					39 00 00 40 00 00 04 E0 16 14 1A
					39 00 00 40 00 00 04 E1 0A 08 0D
					39 00 00 40 00 00 04 E2 03 03 03
					39 00 00 40 00 00 04 E3 02 02 02
					39 00 00 40 00 00 04 E4 3C 34 40
					39 00 00 40 00 00 04 E5 3A 2A 40
					39 00 00 40 00 00 04 E6 32 24 3A
					39 00 00 40 00 00 04 E7 20 1D 2C
					39 00 00 40 00 00 04 E8 1A 16 1F
					39 00 00 40 00 00 04 E9 16 10 14
					39 00 00 40 00 00 04 EA 03 02 03
					39 00 00 40 00 00 04 EB 04 05 06
					39 00 00 40 00 00 04 FF 5A A5 5C
					39 00 00 40 00 00 04 80 03 F4 FA
					39 00 00 40 00 00 04 81 05 00 02
					39 00 00 40 00 00 04 82 02 01 03
					39 00 00 40 00 00 04 83 09 04 06
					39 00 00 40 00 00 04 84 05 02 05
					39 00 00 40 00 00 04 85 04 01 04
					39 00 00 40 00 00 04 86 08 07 05
					39 00 00 40 00 00 04 87 07 05 0A
					39 00 00 40 00 00 04 88 04 04 04
					39 00 00 40 00 00 04 89 02 02 02
					39 00 00 40 00 00 04 8A 0C 08 0F
					39 00 00 40 00 00 04 8B 0A 07 0C
					39 00 00 40 00 00 04 8C 09 06 0A
					39 00 00 00 00 00 04 8D 06 05 08
					39 00 00 40 00 00 04 8E 04 03 05
					39 00 00 40 00 00 04 8F 23 1A 26
					39 00 00 40 00 00 04 90 1C 14 1D
					39 00 00 40 00 00 04 91 12 0A 18
					39 00 00 40 00 00 04 92 0D 07 14
					39 00 00 40 00 00 04 93 06 07 0A
					39 00 00 40 00 00 04 94 02 04 03
					39 00 00 40 00 00 04 95 34 32 3A
					39 00 00 40 00 00 04 96 2B 28 34
					39 00 00 40 00 00 04 97 26 24 2A
					39 00 00 40 00 00 04 98 16 14 1A
					39 00 00 40 00 00 04 99 0A 08 0D
					39 00 00 40 00 00 04 9A 03 03 02
					39 00 00 40 00 00 04 9B 02 02 02
					39 00 00 40 00 00 04 9C 44 3E 54
					39 00 00 40 00 00 04 9D 3A 2A 40
					39 00 00 40 00 00 04 9E 34 26 3A
					39 00 00 40 00 00 04 9F 20 1D 2C
					39 00 00 40 00 00 04 A0 1A 16 1F
					39 00 00 40 00 00 04 A1 16 10 14
					39 00 00 40 00 00 04 A2 03 02 03
					39 00 00 40 00 00 04 A3 04 05 06
					39 00 00 40 00 00 04 A4 04 02 02
					39 00 00 40 00 00 04 A5 06 03 03
					39 00 00 40 00 00 04 A6 02 01 01
					39 00 00 40 00 00 04 A7 03 02 02
					39 00 00 40 00 00 04 A8 02 01 02
					39 00 00 40 00 00 04 A9 02 01 02
					39 00 00 40 00 00 04 AA 05 05 06
					39 00 00 40 00 00 04 AB 04 04 05
					39 00 00 40 00 00 04 AC 03 03 04
					39 00 00 40 00 00 04 AD 02 02 03
					39 00 00 40 00 00 04 AE 08 04 08
					39 00 00 40 00 00 04 AF 06 03 07
					39 00 00 40 00 00 04 B0 05 02 06
					39 00 00 40 00 00 04 B1 03 01 05
					39 00 00 40 00 00 04 B2 02 00 04
					39 00 00 40 00 00 04 B3 25 23 24
					39 00 00 40 00 00 04 B4 23 20 21
					39 00 00 40 00 00 04 B5 13 0D 14
					39 00 00 40 00 00 04 B6 0E 0A 10
					39 00 00 40 00 00 04 B7 06 08 0A
					39 00 00 40 00 00 04 B8 02 04 03
					39 00 00 40 00 00 04 B9 34 31 37
					39 00 00 40 00 00 04 BA 2B 28 34
					39 00 00 40 00 00 04 BB 26 24 2A
					39 00 00 40 00 00 04 BC 16 15 1A
					39 00 00 40 00 00 04 BD 0A 08 0D
					39 00 00 40 00 00 04 BE 02 03 02
					39 00 00 40 00 00 04 BF 02 01 02
					39 00 00 40 00 00 04 C0 35 33 28
					39 00 00 40 00 00 04 C1 34 2A 24
					39 00 00 40 00 00 04 C2 34 26 1C
					39 00 00 40 00 00 04 C3 20 1D 18
					39 00 00 40 00 00 04 C4 1A 16 16
					39 00 00 40 00 00 04 C5 16 10 14
					39 00 00 40 00 00 04 C6 03 02 03
					39 00 00 40 00 00 04 C7 04 05 06
					39 00 00 40 00 00 04 C8 08 04 06
					39 00 00 40 00 00 04 C9 08 04 06
					39 00 00 40 00 00 04 CA 07 03 05
					39 00 00 40 00 00 04 CB 07 03 05
					39 00 00 40 00 00 04 CC 00 00 00
					39 00 00 40 00 00 04 CD 00 00 00
					39 00 00 40 00 00 04 CE 00 00 00
					39 00 00 00 00 00 04 CF 00 00 00
					15 00 00 00 14 00 02 29 00
				];
				qcom,mdss-dsi-off-command=[
					05 00 00 00 14 00 01 28
					05 00 00 00 78 00 01 10
				];
				qcom,mdss-dsi-timing-switch-compensation-command = [
					39 00 00 40 00 00 04 FF 5A A5 08 // PAGE 08
					15 00 00 40 00 00 02 98 02 //Queue Start Close CDM FIFO Reset
					39 00 00 40 00 00 04 FF 5A A5 4F //CMD_Q
					15 00 00 40 00 00 02 80 01 //Enable MSFC
					15 00 00 40 00 00 02 81 06 //04 Rising,05Falling
					15 00 00 40 00 00 02 88 78 // cmd core0 queue start
					//queue1_str
					39 00 00 40 00 00 04 FF 5A A5 24
					39 00 00 40 00 00 06 C9 00 00 00 10 00 //0  1
					39 00 00 40 00 00 04 FE 30 00 70 //3  7
					39 00 00 40 00 00 06 CA 00 B0 00 E0 01 //11 13
					39 00 00 40 00 00 04 FE 10 01 30 //15 19
					39 00 00 40 00 00 06 CB 01 70 01 C0 02 //23  27
					39 00 00 40 00 00 04 FE 30 02 90 //33  41
					39 00 00 40 00 00 06 CC 03 70 03 E0 04 //55 63
					39 00 00 40 00 00 04 FE F0 05 F0 //79  95
					39 00 00 40 00 00 06 CD 07 10 08 F0 0A //113 143
					39 00 00 40 00 00 04 FE F0 0B A0 //175 186
					39 00 00 40 00 00 06 CE 0D 30 0E 10 0E //211 225
					39 00 00 40 00 00 04 FE F0 0F F0 //239 255
					//queue1_end
					39 00 00 40 00 00 04 FF 5A A5 4F // PAGE 4F
					15 00 00 40 00 00 02 8A 78
					//queue2_str
					39 00 00 40 00 00 04 FF 5A A5 00 // PAGE 00
					15 00 00 40 00 00 02 60 05 // 60hz-64Pulse
					15 00 00 40 00 00 02 7D 00
					39 00 00 40 00 00 04 FF 5A A5 20
					15 00 00 40 00 00 02 BB 06 //sync setting
					39 00 00 40 00 00 04 FF 5A A5 24
					39 00 00 40 00 00 06 C9 00 00 00 10 00
					39 00 00 40 00 00 04 FE 30 00 70
					39 00 00 40 00 00 06 CA 00 B0 00 D0 00 //11 13
					39 00 00 40 00 00 04 FE F0 01 30 //15 19
					39 00 00 40 00 00 06 CB 01 70 01 B0 02 //23  27
					39 00 00 40 00 00 04 FE 10 02 90 //33  41
					39 00 00 40 00 00 06 CC 03 70 03 F0 04 //55 63 79
					39 00 00 40 00 00 04 FE F0 05 F0 //95
					39 00 00 40 00 00 06 CD 07 10 08 F0 0A //113 143
					39 00 00 40 00 00 04 FE F0 0B A0 //175 186
					39 00 00 40 00 00 06 CE 0D 30 0E 10 0E //225 239
					39 00 00 40 00 00 04 FE F0 0F F0
					//queue2_end
					39 00 00 40 00 00 04 FF 5A A5 53
					39 00 00 40 00 00 06 90 44 00 00 03 70
					39 00 00 40 00 00 06 FE 44 00 00 04 00
					39 00 00 40 00 00 06 FE 44 00 00 04 00
					39 00 00 40 00 00 06 FE 44 00 00 04 00
					15 00 00 40 00 00 02 F0 01 //MURA_TUNNING
					15 00 00 40 00 00 02 00 00
					15 00 00 40 00 00 02 00 00
					15 00 00 40 00 00 02 00 00
					15 00 00 40 00 00 02 00 00
					15 00 00 40 00 00 02 00 00
					15 00 00 40 00 00 02 00 00
					15 00 00 40 00 00 02 00 00
					15 00 00 40 00 00 02 00 00
					39 00 00 40 00 00 04 FF 5A A5 63
					39 00 00 40 00 00 06 F1 20 20 20 20 20
					39 00 00 40 00 00 06 FE 20 00 00 00 00
					39 00 00 40 00 00 06 FE 00 00 00 00 00
					15 00 00 40 00 00 02 FE 00
					15 00 00 40 00 00 02 00 00
					15 00 00 40 00 00 02 00 00
					15 00 00 40 00 00 02 00 00
					15 00 00 40 00 00 02 00 00
					15 00 00 40 00 00 02 00 00
					39 00 00 40 00 00 06 F2 00 00 00 00 00
					39 00 00 40 00 00 06 FE 00 00 00 00 00
					39 00 00 40 00 00 06 FE 00 00 00 00 00
					15 00 00 40 00 00 02 FE 00
					15 00 00 40 00 00 02 00 00
					15 00 00 40 00 00 02 00 00
					15 00 00 40 00 00 02 00 00
					15 00 00 40 00 00 02 00 00
					15 00 00 40 00 00 02 00 00
					39 00 00 40 00 00 06 F3 00 00 00 00 00
					39 00 00 40 00 00 06 FE 00 20 20 20 20
					39 00 00 40 00 00 06 FE 00 00 00 00 00
					15 00 00 40 00 00 02 FE 00
					15 00 00 40 00 00 02 00 00
					15 00 00 40 00 00 02 00 00
					15 00 00 40 00 00 02 00 00
					15 00 00 40 00 00 02 00 00
					15 00 00 40 00 00 02 00 00
					39 00 00 40 00 00 06 F4 00 00 00 00 00
					39 00 00 40 00 00 06 FE 00 F0 F0 F0 F0
					39 00 00 40 00 00 06 FE 00 00 00 00 00
					15 00 00 40 00 00 02 FE 00
					15 00 00 40 00 00 02 00 00
					15 00 00 40 00 00 02 00 00
					15 00 00 40 00 00 02 00 00
					15 00 00 40 00 00 02 00 00
					15 00 00 40 00 00 02 00 00
					15 00 00 40 00 00 02 00 00
					15 00 00 40 00 00 02 00 00
					15 00 00 40 00 00 02 00 00
					39 00 00 40 00 00 04 FF 5A A5 53
					15 00 00 40 00 00 02 F0 00
					39 00 00 40 00 00 04 FF 5A A5 00
					39 00 00 40 00 00 04 FF 5A A5 08 //ALL Done open CDM FIFO Reset
					15 00 00 40 00 00 02 98 A6
					39 00 00 40 00 00 04 FF 5A A5 00 //Dummy write
					15 00 00 40 00 00 02 00 00
					39 00 00 40 00 00 04 FF 5A A5 4F // PAGE 4F
					15 00 00 40 00 00 02 8B 78 // cmd core 0 queue all done
					39 00 00 00 00 00 04 FF 5A A5 00
					/* wait for te and blocking one frame */
					39 00 00 20 00 00 04 FF 5A A5 00
				];
				oplus,dsi-panel-switch-low-pwm-aod-on-command = [
					39 00 00 40 00 00 04 FF 5A A5 53
					39 00 00 40 00 00 15 90 44 00 00 03 00 44 00 00 04 00 44 00 00 04 00 44 00 00 04 00
                                        39 00 00 40 00 00 04 FF 5A A5 00
					15 00 00 00 00 00 02 60 06
				];
				oplus,dsi-panel-switch-low-pwm-aod-off-command = [
                                        39 00 00 40 00 00 04 FF 5A A5 53
                                        39 00 00 40 00 00 15 90 44 00 00 03 70 44 00 00 04 00 44 00 00 04 00 44 00 00 04 00
					39 00 00 40 00 00 04 FF 5A A5 00
					15 00 00 00 00 00 02 60 05
				];
				qcom,mdss-dsi-hbm-off-command = [
				];
				qcom,mdss-dsi-hbm-on-command = [
				];
				qcom,mdss-dsi-change-voltage-before-bl-0-command = [
				];
				qcom,mdss-dsi-lhbm-pressed-icon-on-command = [
				];
				qcom,mdss-dsi-lhbm-pressed-icon-off-command = [
				];
				qcom,mdss-dsi-aod-off-pwm-mode2-command = [
				];
				qcom,mdss-dsi-aod-off-compensation-command = [
				];
				qcom,mdss-dsi-aod-off-compensation-onepulse-command = [
				];
				/* pwm */
				qcom,mdss-dsi-pwm-state-l3tol2-command = [
				];
				qcom,mdss-dsi-pwm-state-l2tol3-command = [
				];
				qcom,mdss-dsi-pwm-switch-mode0-command= [
				];
				qcom,mdss-dsi-pwm-switch-mode2-command = [
				];
				qcom,mdss-dsi-timming-switch-pwm-mode2-command = [
				];
				qcom,mdss-dsi-pwm-switch-mode2-panel-on-command = [
				];
				qcom,mdss-dsi-pwm-state-l1tol3-command = [
				];
				qcom,mdss-dsi-pwm-state-l3tol1-command = [
				];
				qcom,mdss-dsi-hbm-max-command = [
				];
				qcom,mdss-dsi-hbm-exit-max-command = [
				];
				mdss-dsi-timing-switch-command-state = "dsi_hs_sync1_mode";
				qcom,mdss-dsi-lp1-command-state = "dsi_hs_sync1_mode";
				qcom,mdss-dsi-nolp-command-state = "dsi_hs_sync1_mode";
				oplus,dsi-panel-switch-low-pwm-aod-on-command-state = "dsi_hs_sync1_mode";
				oplus,dsi-panel-switch-low-pwm-aod-off-command-state = "dsi_hs_sync1_mode";
				qcom,mdss-dsi-aod-off-pwm-mode2-command-state = "dsi_hs_sync1_mode";
				qcom,mdss-dsi-aod-off-compensation-command-state = "dsi_lp_sync1_mode";
				qcom,mdss-dsi-aod-off-compensation-onepulse-command-state = "dsi_lp_sync1_mode";
				qcom,mdss-dsi-nolp-hpwm-command-state = "dsi_lp_sync1_mode";
				qcom,mdss-dsi-hbm-on-command-state = "dsi_hs_sync1_mode";
				qcom,mdss-dsi-hbm-off-command-state = "dsi_hs_sync1_mode";
				qcom,mdss-dsi-panel-read-register-open-state = "dsi_lp_mode";
				qcom,mdss-dsi-panel-read-register-close-state = "dsi_lp_mode";
				qcom,mdss-dsi-lhbm-pressed-icon-gamma-command-state = "dsi_lp_mode";
				qcom,mdss-dsi-lhbm-pressed-icon-grayscale-command-state = "dsi_lp_mode";
				qcom,mdss-dsi-lhbm-pressed-icon-on-command-state = "dsi_lp_mode";
				qcom,mdss-dsi-lhbm-pressed-icon-off-command-state = "dsi_lp_mode";
				qcom,mdss-dsi-lhbm-dbv-alpha-command-state = "dsi_hs_mode";

				qcom,mdss-dsi-reset-scanline-command-state = "dsi_hs_mode";
				qcom,mdss-dsi-recovery-scanline-command-state = "dsi_hs_mode";

				qcom,mdss-dsi-osc-track-on-command-state = "dsi_hs_mode";
				qcom,mdss-dsi-osc-track-off-command-state = "dsi_hs_mode";
				qcom,mdss-dsi-hbm-max-command-state = "dsi_hs_mode";
				qcom,mdss-dsi-hbm-exit-max-command-state = "dsi_hs_mode";

				qcom,lm-split = <608 608>;
				qcom,compression-mode = "dsc";
				qcom,mdss-dsc-encoders = <2>;
				qcom,mdss-dsc-slice-height = <20>;
				qcom,mdss-dsc-slice-width = <608>;
				qcom,mdss-dsc-slice-per-pkt = <2>;
				qcom,mdss-dsc-bit-per-component = <10>;
				qcom,mdss-dsc-bit-per-pixel = <8>;
				qcom,mdss-dsc-block-prediction-enable;
			};
			timing@sdc_fhd_144 {
				#include "dsi-panel-AA616-P-7-A0020-common.dtsi"
				#include "dsi-panel-AA616-P-7-A0020-loading-effect.dtsi"
				qcom,mdss-mdp-transfer-time-us = <5380>;
				qcom,mdss-dsi-panel-jitter = <0x4 0x1>;
				qcom,mdss-dsc-version = <0x12>;
				qcom,mdss-dsi-timing-default;
				qcom,mdss-dsi-panel-framerate = <144>;
				qcom,mdss-dsi-panel-clockrate = <1370000000>;
				qcom,mdss-dsi-panel-width = <1216>;
				qcom,mdss-dsi-panel-height = <2640>;

				qcom,mdss-dsi-h-front-porch = <44>;
				qcom,mdss-dsi-h-back-porch = <16>;
				qcom,mdss-dsi-h-pulse-width = <16>;
				qcom,mdss-dsi-v-back-porch = <24>;
				qcom,mdss-dsi-v-front-porch = <88>;
				qcom,mdss-dsi-v-pulse-width = <2>;
				qcom,mdss-dsi-h-sync-pulse = <0>;


				qcom,mdss-dsi-timing-switch-command = [
					39 00 00 40 00 00 04 FF 5A A5 08 // PAGE 08
					15 00 00 40 00 00 02 98 02 //Queue Start Close CDM FIFO Reset
					39 00 00 40 00 00 04 FF 5A A5 4F // PAGE 4F
					15 00 00 40 00 00 02 80 01 //Enable MSFC
					15 00 00 40 00 00 02 81 06 //04 Rising,05Falling
					15 00 00 40 00 00 02 88 78 // cmd core0 queue start
					39 00 00 40 00 00 04 FF 5A A5 53
					39 00 00 40 00 00 06 90 44 00 00 04 00
					39 00 00 40 00 00 06 FE 44 00 00 04 00
					39 00 00 40 00 00 06 FE 44 00 00 04 00
					39 00 00 40 00 00 06 FE 44 00 00 04 00
					15 00 00 40 00 00 02 F0 01 //MURA_TUNNING
					15 00 00 40 00 00 02 00 00
					15 00 00 40 00 00 02 00 00
					15 00 00 40 00 00 02 00 00
					15 00 00 40 00 00 02 00 00
					15 00 00 40 00 00 02 00 00
					15 00 00 40 00 00 02 00 00
					15 00 00 40 00 00 02 00 00
					15 00 00 40 00 00 02 00 00
					39 00 00 40 00 00 04 FF 5A A5 63
					39 00 00 40 00 00 06 F1 20 20 20 20 20
					39 00 00 40 00 00 06 FE 20 00 00 00 00
					39 00 00 40 00 00 06 FE 00 00 00 00 00
					15 00 00 40 00 00 02 FE 00
					15 00 00 40 00 00 02 00 00
					15 00 00 40 00 00 02 00 00
					15 00 00 40 00 00 02 00 00
					15 00 00 40 00 00 02 00 00
					15 00 00 40 00 00 02 00 00
					39 00 00 40 00 00 06 F2 00 00 00 00 00
					39 00 00 40 00 00 06 FE 00 00 00 00 00
					39 00 00 40 00 00 06 FE 00 00 00 00 00
					15 00 00 40 00 00 02 FE 00
					15 00 00 40 00 00 02 00 00
					15 00 00 40 00 00 02 00 00
					15 00 00 40 00 00 02 00 00
					15 00 00 40 00 00 02 00 00
					15 00 00 40 00 00 02 00 00
					39 00 00 40 00 00 06 F3 00 00 00 00 00
					39 00 00 40 00 00 06 FE 00 20 20 20 20
					39 00 00 40 00 00 06 FE 00 00 00 00 00
					15 00 00 40 00 00 02 FE 00
					15 00 00 40 00 00 02 00 00
					15 00 00 40 00 00 02 00 00
					15 00 00 40 00 00 02 00 00
					15 00 00 40 00 00 02 00 00
					15 00 00 40 00 00 02 00 00
					39 00 00 40 00 00 06 F4 00 00 00 00 00
					39 00 00 40 00 00 06 FE 00 F0 F0 F0 F0
					39 00 00 40 00 00 06 FE 00 00 00 00 00
					15 00 00 40 00 00 02 FE 00
					15 00 00 40 00 00 02 00 00
					15 00 00 40 00 00 02 00 00
					15 00 00 40 00 00 02 00 00
					15 00 00 40 00 00 02 00 00
					15 00 00 40 00 00 02 00 00
					15 00 00 40 00 00 02 00 00
					15 00 00 40 00 00 02 00 00
					15 00 00 40 00 00 02 00 00
					39 00 00 40 00 00 04 FF 5A A5 53
					15 00 00 40 00 00 02 F0 00
					39 00 00 40 00 00 04 FF 5A A5 00 // PAGE 00
					15 00 00 40 00 00 02 60 01 //144Hz
					15 00 00 40 00 00 02 7D 02
					39 00 00 40 00 00 04 FF 5A A5 20
					15 00 00 40 00 00 02 BB 05 //sync setting
					39 00 00 40 00 00 04 FF 5A A5 08 //ALL Done open CDM FIFO Reset
					15 00 00 40 00 00 02 98 A6
					39 00 00 40 00 00 04 FF 5A A5 00 //Dummy write
					15 00 00 40 00 00 02 00 00
					39 00 00 40 00 00 04 FF 5A A5 4F // PAGE 4F
					15 00 00 40 00 00 02 8B 78 // cmd core 0 queue all done
					39 00 00 00 00 00 04 FF 5A A5 00
				];
				qcom,mdss-dsi-on-command = [
					39 00 00 40 00 00 04 FF 5A A5 08
					15 00 00 40 00 00 02 C8 62
					39 00 00 40 00 00 04 FF 5A A5 21
					15 00 00 40 00 00 02 A4 38
					39 00 00 40 00 00 04 FF 5A A5 23
					15 00 00 40 00 00 02 85 15
					39 00 00 40 00 00 04 FF 5A A5 06
					15 00 00 40 00 00 02 C6 01
					39 00 00 40 00 00 04 FF 5A A5 08
					15 00 00 40 00 00 02 D2 05
					15 00 00 40 00 00 02 D3 01
					39 00 00 40 00 00 09 ED FF FF FF FF FF FF 45 FF
					39 00 00 40 00 00 09 EE FF FD FF FD F9 FA BE 76

					39 00 00 40 00 00 04 FF 5A A5 07
					15 00 00 40 00 00 02 8A 01
					39 00 00 40 00 00 03 8B 21 E0
					39 00 00 40 00 00 64 81 00 00 00 00 00 12 00 00 AB 21 00 0A 50 04 C0 00 14 02 60 02 60 01 55 01 D3 00 0A 01 08 00 33 00 0D 05 7A 19 5A 08 00 0B F0 07 10 20 00 06 0F 0F 33 0E 1C 2A 38 46 54 62 69 70 77 79 7B 7D 7E 00 82 11 40 19 C0 22 3E 32 7C 3A BA 3A F8 3B 38 3B 38 3B 76 4B 76 4B 74 4B 74 5B B4 73 F4 01 00 00 00 00 00
					15 00 00 40 00 00 02 91 03
					39 00 00 40 00 00 04 FF 5A A5 14
					15 00 00 40 00 00 02 80 00
					15 00 00 40 00 00 02 82 01
					39 00 00 40 00 00 04 FF 5A A5 17
					15 00 00 40 00 00 02 A0 0C
					39 00 00 40 00 00 04 FF 5A A5 13
					15 00 00 40 00 00 02 F9 3C
					39 00 00 40 00 00 04 FF 5A A5 22
					39 00 00 40 00 00 08 D8 00 F4 11 10 3E 17 17
					39 00 00 40 00 00 08 D9 00 F3 11 10 3E 17 17
					39 00 00 40 00 00 08 DA 00 EA 11 10 2B 16 16
					39 00 00 40 00 00 08 DB 00 E9 11 10 2B 16 16
					39 00 00 40 00 00 0A DC 84 94 BB 00 20 C4 A1 CC 10
					15 00 00 40 00 00 02 DD 01
					15 00 00 40 00 00 02 DE F1
					15 00 00 40 00 00 02 DF 80
					39 00 00 00 00 00 07 E0 02 00 5F 21 00 28

					39 00 00 40 00 00 04 FF 5A A5 00
					15 00 00 00 00 00 02 7D 00

					39 00 00 40 00 00 04 FF 5A A5 53
					39 00 00 40 00 00 06 90 44 00 00 04 00
					39 00 00 40 00 00 06 FE 44 00 00 04 00
					39 00 00 40 00 00 06 FE 44 00 00 04 00
					39 00 00 40 00 00 06 FE 44 00 00 04 00
					15 00 00 40 00 00 02 F0 01 //MURA_TUNNING
					15 00 00 40 00 00 02 00 00
					15 00 00 40 00 00 02 00 00
					15 00 00 40 00 00 02 00 00
					15 00 00 40 00 00 02 00 00
					15 00 00 40 00 00 02 00 00
					15 00 00 40 00 00 02 00 00
					15 00 00 40 00 00 02 00 00
					15 00 00 40 00 00 02 00 00
					39 00 00 40 00 00 04 FF 5A A5 63
					39 00 00 40 00 00 06 F1 20 20 20 20 20
					39 00 00 40 00 00 06 FE 20 00 00 00 00
					39 00 00 40 00 00 06 FE 00 00 00 00 00
					15 00 00 40 00 00 02 FE 00
					15 00 00 40 00 00 02 00 00
					15 00 00 40 00 00 02 00 00
					15 00 00 40 00 00 02 00 00
					15 00 00 40 00 00 02 00 00
					15 00 00 40 00 00 02 00 00
					39 00 00 40 00 00 06 F2 00 00 00 00 00
					39 00 00 40 00 00 06 FE 00 00 00 00 00
					39 00 00 40 00 00 06 FE 00 00 00 00 00
					15 00 00 40 00 00 02 FE 00
					15 00 00 40 00 00 02 00 00
					15 00 00 40 00 00 02 00 00
					15 00 00 40 00 00 02 00 00
					15 00 00 40 00 00 02 00 00
					15 00 00 40 00 00 02 00 00
					39 00 00 40 00 00 06 F3 00 00 00 00 00
					39 00 00 40 00 00 06 FE 00 20 20 20 20
					39 00 00 40 00 00 06 FE 00 00 00 00 00
					15 00 00 40 00 00 02 FE 00
					15 00 00 40 00 00 02 00 00
					15 00 00 40 00 00 02 00 00
					15 00 00 40 00 00 02 00 00
					15 00 00 40 00 00 02 00 00
					15 00 00 40 00 00 02 00 00
					39 00 00 40 00 00 06 F4 00 00 00 00 00
					39 00 00 40 00 00 06 FE 00 F0 F0 F0 F0
					39 00 00 40 00 00 06 FE 00 00 00 00 00
					15 00 00 40 00 00 02 FE 00
					15 00 00 40 00 00 02 00 00
					15 00 00 40 00 00 02 00 00
					15 00 00 40 00 00 02 00 00
					15 00 00 40 00 00 02 00 00
					15 00 00 40 00 00 02 00 00
					15 00 00 40 00 00 02 00 00
					15 00 00 40 00 00 02 00 00
					15 00 00 40 00 00 02 00 00
					39 00 00 40 00 00 04 FF 5A A5 53
					15 00 00 40 00 00 02 F0 00
					39 00 00 40 00 00 04 FF 5A A5 00 // PAGE 00
					15 00 00 40 00 00 02 60 01 //144Hz
					15 00 00 40 00 00 02 7D 02
					39 00 00 40 00 00 04 FF 5A A5 20
					15 00 00 40 00 00 02 BB 05 //sync setting
					39 00 00 40 00 00 04 FF 5A A5 22
					39 00 00 40 00 00 08 D8 00 F6 11 10 38 17 17
					39 00 00 40 00 00 08 D9 00 F5 11 10 38 17 17
					39 00 00 40 00 00 08 DA 00 EA 11 10 2B 16 16
					39 00 00 40 00 00 08 DB 00 E9 11 10 2B 16 16
					39 00 00 40 00 00 0A DC 84 94 BB 00 20 C4 A1 CC 10
					15 00 00 40 00 00 02 DD 01
					15 00 00 40 00 00 02 DE F1
					15 00 00 40 00 00 02 DF 80
					39 00 00 40 00 00 07 E0 02 00 5F 21 00 28
					15 00 00 40 00 00 02 5E 01 // Skip frame Enable
					15 00 00 40 00 00 02 60 00 // Normal mode1=120Hz
					15 00 00 40 00 00 02 61 02 //AOD in Mode3=30Hz
					15 00 00 40 00 00 02 6D 01 // IRC enable
					15 00 00 40 00 00 02 35 00 // TE on
					15 00 00 00 00 00 02 53 20 // BC On

					//144Hz
					39 00 00 40 00 00 04 FF 5A A5 00
					15 00 00 00 00 00 02 60 01
					15 00 00 00 78 00 02 11 00
					39 00 00 40 00 00 04 FF 5A A5 49
					39 00 00 40 00 00 0C 80 00 01 09 11 21 41 81 C1 01 00 01
					39 00 00 40 00 00 11 81 01 00 BD 00 18 01 41 02 42 02 A6 03 8B 05 DD 06
					39 00 00 40 00 00 13 82 01 00 BD 00 18 01 41 02 42 02 A6 03 8B 05 DD 06 00 00
					15 00 00 40 00 00 02 83 07
					15 00 00 40 00 00 02 84 0A
					39 00 00 40 00 00 04 85 80 00 02
					39 00 00 40 00 00 04 86 80 00 02
					39 00 00 40 00 00 04 A0 40 40 40
					39 00 00 40 00 00 04 A1 40 40 40
					39 00 00 40 00 00 04 A2 40 40 40
					15 00 00 40 00 00 02 A6 3F
					15 00 00 40 00 00 02 A7 03
					15 00 00 40 00 00 02 AD 01
					15 00 00 40 00 00 02 AE 00
					15 00 00 40 00 00 02 AF 00
					15 00 00 40 00 00 02 D9 02
					15 00 00 40 00 00 02 DA F7
					15 00 00 40 00 00 02 DB 9C
					15 00 00 40 00 00 02 DC 03
					15 00 00 40 00 00 02 DF 06
					15 00 00 40 00 00 02 E0 01
					39 00 00 40 00 00 04 FF 5A A5 5A
					39 00 00 40 00 00 04 80 03 D0 00
					39 00 00 40 00 00 04 81 5D D0 40
					39 00 00 40 00 00 04 82 0F 04 0B
					39 00 00 40 00 00 04 83 6D 80 0C
					39 00 00 40 00 00 04 84 50 20 4A
					39 00 00 40 00 00 04 85 18 10 2D
					39 00 00 40 00 00 04 86 7E 80 0E
					39 00 00 40 00 00 04 87 1D 13 17
					39 00 00 40 00 00 04 88 10 0F 0F
					39 00 00 40 00 00 04 89 0C 0A 06
					39 00 00 40 00 00 04 8A 7F 14 F0
					39 00 00 40 00 00 04 8B 1A 15 1B
					39 00 00 40 00 00 04 8C 18 12 1A
					39 00 00 40 00 00 04 8D 18 11 18
					39 00 00 40 00 00 04 8E 09 06 0A
					39 00 00 40 00 00 04 8F 7F 46 F6
					39 00 00 40 00 00 04 90 1C 14 1D
					39 00 00 40 00 00 04 91 1A 12 1B
					39 00 00 40 00 00 04 92 18 0A 19
					39 00 00 40 00 00 04 93 15 06 16
					39 00 00 40 00 00 04 94 0C 02 0D
					39 00 00 40 00 00 04 95 57 1D 03
					39 00 00 40 00 00 04 96 18 10 1A
					39 00 00 40 00 00 04 97 10 0F 12
					39 00 00 40 00 00 04 98 10 07 10
					39 00 00 40 00 00 04 99 0C 0A 0F
					39 00 00 40 00 00 04 9A 04 03 0A
					39 00 00 40 00 00 04 9B 03 01 03
					39 00 00 40 00 00 04 9C 52 3E 2D
					39 00 00 40 00 00 04 9D 34 32 2D
					39 00 00 40 00 00 04 9E 23 20 22
					39 00 00 40 00 00 04 9F 1D 1A 1D
					39 00 00 40 00 00 04 A0 16 12 16
					39 00 00 40 00 00 04 A1 0A 08 09
					39 00 00 40 00 00 04 A2 07 03 05
					39 00 00 40 00 00 04 A3 06 01 03
					39 00 00 40 00 00 04 A4 02 D0 00
					39 00 00 40 00 00 04 A5 14 DD 0F
					39 00 00 40 00 00 04 A6 0A E4 0C
					39 00 00 40 00 00 04 A7 4A 80 D8
					39 00 00 40 00 00 04 A8 05 02 07
					39 00 00 40 00 00 04 A9 03 00 05
					39 00 00 40 00 00 04 AA 24 80 8F
					39 00 00 40 00 00 04 AB 0A 06 09
					39 00 00 40 00 00 04 AC 07 05 07
					39 00 00 40 00 00 04 AD 03 00 05
					39 00 00 40 00 00 04 AE 32 03 04
					39 00 00 40 00 00 04 AF 13 10 12
					39 00 00 40 00 00 04 B0 10 06 0D
					39 00 00 40 00 00 04 B1 0E 04 0C
					39 00 00 40 00 00 04 B2 03 01 05
					39 00 00 40 00 00 04 B3 2A 16 02
					39 00 00 40 00 00 04 B4 0E 0C 10
					39 00 00 40 00 00 04 B5 0D 0A 0E
					39 00 00 40 00 00 04 B6 0A 07 0A
					39 00 00 40 00 00 04 B7 07 05 0B
					39 00 00 40 00 00 04 B8 05 04 06
					39 00 00 40 00 00 04 B9 1F 10 1D
					39 00 00 40 00 00 04 BA 18 0F 12
					39 00 00 40 00 00 04 BB 13 0D 0A
					39 00 00 40 00 00 04 BC 0E 08 0A
					39 00 00 40 00 00 04 BD 09 06 0C
					39 00 00 40 00 00 04 BE 07 05 08
					39 00 00 40 00 00 04 BF 04 04 06
					39 00 00 40 00 00 04 C0 37 23 2F
					39 00 00 40 00 00 04 C1 27 1F 1F
					39 00 00 40 00 00 04 C2 1D 18 0D
					39 00 00 40 00 00 04 C3 1A 12 08
					39 00 00 40 00 00 04 C4 12 10 06
					39 00 00 40 00 00 04 C5 0A 07 03
					39 00 00 40 00 00 04 C6 08 04 02
					39 00 00 40 00 00 04 C7 03 02 01
					39 00 00 40 00 00 04 C8 40 06 0A
					39 00 00 40 00 00 04 C9 25 00 12
					39 00 00 40 00 00 04 CA 16 00 06
					39 00 00 40 00 00 04 CB 5A 00 00
					39 00 00 40 00 00 04 CC 06 01 06
					39 00 00 40 00 00 04 CD 03 00 05
					39 00 00 40 00 00 04 CE 30 00 00
					39 00 00 40 00 00 04 CF 10 04 06
					39 00 00 40 00 00 04 D0 0D 02 0E
					39 00 00 40 00 00 04 D1 06 00 0A
					39 00 00 40 00 00 04 D2 20 02 08
					39 00 00 40 00 00 04 D3 0D 04 06
					39 00 00 40 00 00 04 D4 08 00 05
					39 00 00 40 00 00 04 D5 06 00 03
					39 00 00 40 00 00 04 D6 05 00 01
					39 00 00 40 00 00 04 D7 26 15 16
					39 00 00 40 00 00 04 D8 12 0D 13
					39 00 00 40 00 00 04 D9 10 0A 12
					39 00 00 40 00 00 04 DA 0D 09 08
					39 00 00 40 00 00 04 DB 07 05 07
					39 00 00 40 00 00 04 DC 04 03 05
					39 00 00 40 00 00 04 DD 26 2A 26
					39 00 00 40 00 00 04 DE 20 28 23
					39 00 00 40 00 00 04 DF 16 1A 1E
					39 00 00 40 00 00 04 E0 12 16 14
					39 00 00 40 00 00 04 E1 0D 0F 0E
					39 00 00 40 00 00 04 E2 03 04 02
					39 00 00 40 00 00 04 E3 02 03 01
					39 00 00 40 00 00 04 E4 34 23 14
					39 00 00 40 00 00 04 E5 16 13 00
					39 00 00 40 00 00 04 E6 08 0D 00
					39 00 00 40 00 00 04 E7 06 0A 00
					39 00 00 40 00 00 04 E8 05 08 00
					39 00 00 40 00 00 04 E9 03 05 00
					39 00 00 40 00 00 04 EA 02 04 00
					39 00 00 40 00 00 04 EB 00 02 00
					39 00 00 40 00 00 04 FF 5A A5 5B
					39 00 00 40 00 00 04 80 05 00 00
					39 00 00 40 00 00 04 81 2A FA 10
					39 00 00 40 00 00 04 82 04 00 01
					39 00 00 40 00 00 04 83 2C FC 15
					39 00 00 40 00 00 04 84 08 01 03
					39 00 00 40 00 00 04 85 03 01 02
					39 00 00 40 00 00 04 86 0D 08 0E
					39 00 00 40 00 00 04 87 05 03 02
					39 00 00 40 00 00 04 88 04 02 03
					39 00 00 40 00 00 04 89 03 00 01
					39 00 00 40 00 00 04 8A 16 03 06
					39 00 00 40 00 00 04 8B 04 03 03
					39 00 00 40 00 00 04 8C 02 02 02
					39 00 00 40 00 00 04 8D 01 00 01
					39 00 00 40 00 00 04 8E 00 00 00
					39 00 00 40 00 00 04 8F 24 18 1B
					39 00 00 40 00 00 04 90 18 1C 1A
					39 00 00 40 00 00 04 91 14 16 14
					39 00 00 40 00 00 04 92 10 0F 11
					39 00 00 40 00 00 04 93 0A 08 0B
					39 00 00 40 00 00 04 94 05 06 04
					39 00 00 40 00 00 04 95 25 1D 1E
					39 00 00 40 00 00 04 96 16 18 1A
					39 00 00 40 00 00 04 97 12 14 16
					39 00 00 40 00 00 04 98 10 11 12
					39 00 00 40 00 00 04 99 0A 0C 0D
					39 00 00 40 00 00 04 9A 07 08 0A
					39 00 00 40 00 00 04 9B 05 06 07
					39 00 00 40 00 00 04 9C 38 2C 44
					39 00 00 40 00 00 04 9D 36 2A 40
					39 00 00 40 00 00 04 9E 32 24 3A
					39 00 00 40 00 00 04 9F 20 1A 2A
					39 00 00 40 00 00 04 A0 1A 16 1F
					39 00 00 40 00 00 04 A1 16 10 14
					39 00 00 40 00 00 04 A2 07 08 07
					39 00 00 40 00 00 04 A3 05 06 06
					39 00 00 40 00 00 04 A4 06 00 00
					39 00 00 40 00 00 04 A5 10 09 02
					39 00 00 40 00 00 04 A6 06 00 02
					39 00 00 40 00 00 04 A7 0F 08 04
					39 00 00 40 00 00 04 A8 06 02 07
					39 00 00 40 00 00 04 A9 05 01 06
					39 00 00 40 00 00 04 AA 10 02 07
					39 00 00 40 00 00 04 AB 04 02 03
					39 00 00 40 00 00 04 AC 03 01 02
					39 00 00 40 00 00 04 AD 02 00 04
					39 00 00 40 00 00 04 AE 1A 06 09
					39 00 00 40 00 00 04 AF 09 06 09
					39 00 00 40 00 00 04 B0 08 05 07
					39 00 00 40 00 00 04 B1 07 03 05
					39 00 00 40 00 00 04 B2 04 01 03
					39 00 00 40 00 00 04 B3 1F 13 16
					39 00 00 40 00 00 04 B4 18 13 19
					39 00 00 40 00 00 04 B5 15 12 17
					39 00 00 40 00 00 04 B6 11 0D 13
					39 00 00 40 00 00 04 B7 0A 08 0D
					39 00 00 40 00 00 04 B8 04 06 07
					39 00 00 40 00 00 04 B9 26 1D 23
					39 00 00 40 00 00 04 BA 1A 18 1C
					39 00 00 40 00 00 04 BB 14 10 15
					39 00 00 40 00 00 04 BC 10 13 12
					39 00 00 40 00 00 04 BD 0B 0F 0F
					39 00 00 40 00 00 04 BE 04 05 04
					39 00 00 40 00 00 04 BF 03 02 03
					39 00 00 40 00 00 04 C0 3C 30 4C
					39 00 00 40 00 00 04 C1 3A 2A 40
					39 00 00 40 00 00 04 C2 32 24 3A
					39 00 00 40 00 00 04 C3 20 1D 2C
					39 00 00 40 00 00 04 C4 1A 16 1F
					39 00 00 40 00 00 04 C5 16 10 14
					39 00 00 40 00 00 04 C6 05 06 08
					39 00 00 40 00 00 04 C7 04 05 06
					39 00 00 40 00 00 04 C8 04 00 00
					39 00 00 40 00 00 04 C9 18 0D 10
					39 00 00 40 00 00 04 CA 18 00 02
					39 00 00 40 00 00 04 CB 0C 04 04
					39 00 00 40 00 00 04 CC 03 02 01
					39 00 00 40 00 00 04 CD 02 01 00
					39 00 00 40 00 00 04 CE 06 03 08
					39 00 00 40 00 00 04 CF 04 02 04
					39 00 00 40 00 00 04 D0 03 01 03
					39 00 00 40 00 00 04 D1 02 00 00
					39 00 00 40 00 00 04 D2 0E 0A 10
					39 00 00 40 00 00 04 D3 0A 08 0D
					39 00 00 40 00 00 04 D4 07 05 0A
					39 00 00 40 00 00 04 D5 04 03 07
					39 00 00 40 00 00 04 D6 03 01 06
					39 00 00 40 00 00 04 D7 18 12 22
					39 00 00 40 00 00 04 D8 16 10 1A
					39 00 00 40 00 00 04 D9 12 0A 14
					39 00 00 40 00 00 04 DA 0D 08 12
					39 00 00 40 00 00 04 DB 06 06 0C
					39 00 00 40 00 00 04 DC 02 04 03
					39 00 00 40 00 00 04 DD 2C 28 34
					39 00 00 40 00 00 04 DE 28 22 30
					39 00 00 40 00 00 04 DF 20 18 2A
					39 00 00 40 00 00 04 E0 16 14 1A
					39 00 00 40 00 00 04 E1 0A 08 0D
					39 00 00 40 00 00 04 E2 03 03 03
					39 00 00 40 00 00 04 E3 02 02 02
					39 00 00 40 00 00 04 E4 3C 34 40
					39 00 00 40 00 00 04 E5 3A 2A 40
					39 00 00 40 00 00 04 E6 32 24 3A
					39 00 00 40 00 00 04 E7 20 1D 2C
					39 00 00 40 00 00 04 E8 1A 16 1F
					39 00 00 40 00 00 04 E9 16 10 14
					39 00 00 40 00 00 04 EA 03 02 03
					39 00 00 40 00 00 04 EB 04 05 06
					39 00 00 40 00 00 04 FF 5A A5 5C
					39 00 00 40 00 00 04 80 03 F4 FA
					39 00 00 40 00 00 04 81 05 00 02
					39 00 00 40 00 00 04 82 02 01 03
					39 00 00 40 00 00 04 83 09 04 06
					39 00 00 40 00 00 04 84 05 02 05
					39 00 00 40 00 00 04 85 04 01 04
					39 00 00 40 00 00 04 86 08 07 05
					39 00 00 40 00 00 04 87 07 05 0A
					39 00 00 40 00 00 04 88 04 04 04
					39 00 00 40 00 00 04 89 02 02 02
					39 00 00 40 00 00 04 8A 0C 08 0F
					39 00 00 40 00 00 04 8B 0A 07 0C
					39 00 00 40 00 00 04 8C 09 06 0A
					39 00 00 00 00 00 04 8D 06 05 08
					39 00 00 40 00 00 04 8E 04 03 05
					39 00 00 40 00 00 04 8F 23 1A 26
					39 00 00 40 00 00 04 90 1C 14 1D
					39 00 00 40 00 00 04 91 12 0A 18
					39 00 00 40 00 00 04 92 0D 07 14
					39 00 00 40 00 00 04 93 06 07 0A
					39 00 00 40 00 00 04 94 02 04 03
					39 00 00 40 00 00 04 95 34 32 3A
					39 00 00 40 00 00 04 96 2B 28 34
					39 00 00 40 00 00 04 97 26 24 2A
					39 00 00 40 00 00 04 98 16 14 1A
					39 00 00 40 00 00 04 99 0A 08 0D
					39 00 00 40 00 00 04 9A 03 03 02
					39 00 00 40 00 00 04 9B 02 02 02
					39 00 00 40 00 00 04 9C 44 3E 54
					39 00 00 40 00 00 04 9D 3A 2A 40
					39 00 00 40 00 00 04 9E 34 26 3A
					39 00 00 40 00 00 04 9F 20 1D 2C
					39 00 00 40 00 00 04 A0 1A 16 1F
					39 00 00 40 00 00 04 A1 16 10 14
					39 00 00 40 00 00 04 A2 03 02 03
					39 00 00 40 00 00 04 A3 04 05 06
					39 00 00 40 00 00 04 A4 04 02 02
					39 00 00 40 00 00 04 A5 06 03 03
					39 00 00 40 00 00 04 A6 02 01 01
					39 00 00 40 00 00 04 A7 03 02 02
					39 00 00 40 00 00 04 A8 02 01 02
					39 00 00 40 00 00 04 A9 02 01 02
					39 00 00 40 00 00 04 AA 05 05 06
					39 00 00 40 00 00 04 AB 04 04 05
					39 00 00 40 00 00 04 AC 03 03 04
					39 00 00 40 00 00 04 AD 02 02 03
					39 00 00 40 00 00 04 AE 08 04 08
					39 00 00 40 00 00 04 AF 06 03 07
					39 00 00 40 00 00 04 B0 05 02 06
					39 00 00 40 00 00 04 B1 03 01 05
					39 00 00 40 00 00 04 B2 02 00 04
					39 00 00 40 00 00 04 B3 25 23 24
					39 00 00 40 00 00 04 B4 23 20 21
					39 00 00 40 00 00 04 B5 13 0D 14
					39 00 00 40 00 00 04 B6 0E 0A 10
					39 00 00 40 00 00 04 B7 06 08 0A
					39 00 00 40 00 00 04 B8 02 04 03
					39 00 00 40 00 00 04 B9 34 31 37
					39 00 00 40 00 00 04 BA 2B 28 34
					39 00 00 40 00 00 04 BB 26 24 2A
					39 00 00 40 00 00 04 BC 16 15 1A
					39 00 00 40 00 00 04 BD 0A 08 0D
					39 00 00 40 00 00 04 BE 02 03 02
					39 00 00 40 00 00 04 BF 02 01 02
					39 00 00 40 00 00 04 C0 35 33 28
					39 00 00 40 00 00 04 C1 34 2A 24
					39 00 00 40 00 00 04 C2 34 26 1C
					39 00 00 40 00 00 04 C3 20 1D 18
					39 00 00 40 00 00 04 C4 1A 16 16
					39 00 00 40 00 00 04 C5 16 10 14
					39 00 00 40 00 00 04 C6 03 02 03
					39 00 00 40 00 00 04 C7 04 05 06
					39 00 00 40 00 00 04 C8 08 04 06
					39 00 00 40 00 00 04 C9 08 04 06
					39 00 00 40 00 00 04 CA 07 03 05
					39 00 00 40 00 00 04 CB 07 03 05
					39 00 00 40 00 00 04 CC 00 00 00
					39 00 00 40 00 00 04 CD 00 00 00
					39 00 00 40 00 00 04 CE 00 00 00
					39 00 00 00 00 00 04 CF 00 00 00
					15 00 00 00 14 00 02 29 00
				];
				qcom,mdss-dsi-off-command=[
					05 00 00 00 14 00 01 28
					05 00 00 00 78 00 01 10
				];
				oplus,dsi-panel-switch-low-pwm-aod-on-command = [
				];
				oplus,dsi-panel-switch-low-pwm-aod-off-command = [
				];
				qcom,mdss-dsi-timing-switch-compensation-command = [
					39 00 00 40 00 00 04 FF 5A A5 08 // PAGE 08
					15 00 00 40 00 00 02 98 02 //Queue Start Close CDM FIFO Reset
					39 00 00 40 00 00 04 FF 5A A5 4F //CMD_Q
					15 00 00 40 00 00 02 80 01 //Enable MSFC
					15 00 00 40 00 00 02 81 06 //04 Rising,05Falling
					15 00 00 40 00 00 02 88 78 // cmd core0 queue start
					//queue1_str
					39 00 00 40 00 00 04 FF 5A A5 24
					39 00 00 40 00 00 06 C9 00 00 00 10 00
					39 00 00 40 00 00 04 FE 30 00 70
					39 00 00 40 00 00 06 CA 00 B0 00 E0 01 //11 13
					39 00 00 40 00 00 04 FE 10 01 30 //15 19
					39 00 00 40 00 00 06 CB 01 70 01 C0 02 //23  27
					39 00 00 40 00 00 04 FE 30 02 90 //33  41
					39 00 00 40 00 00 06 CC 03 70 03 E0 04 //55 63 79
					39 00 00 40 00 00 04 FE F0 05 F0 //95
					39 00 00 40 00 00 06 CD 07 10 08 F0 0A //113 143
					39 00 00 40 00 00 04 FE F0 0B A0 //175 186
					39 00 00 40 00 00 06 CE 0D 30 0E 10 0E //225 239
					39 00 00 40 00 00 04 FE F0 0F F0
					39 00 00 40 00 00 04 FF 5A A5 4F // PAGE 4F
					15 00 00 40 00 00 02 8A 78
					//queue2_str
					39 00 00 40 00 00 04 FF 5A A5 00 // PAGE 00
					15 00 00 40 00 00 02 60 01 //144hz
					15 00 00 40 00 00 02 7D 02
					39 00 00 40 00 00 04 FF 5A A5 20
					15 00 00 40 00 00 02 BB 05 //sync setting
					39 00 00 40 00 00 04 FF 5A A5 24
					39 00 00 40 00 00 06 C9 00 00 00 10 00
					39 00 00 40 00 00 04 FE 30 00 70
					39 00 00 40 00 00 06 CA 00 B0 00 D0 00 //11 13
					39 00 00 40 00 00 04 FE F0 01 30 //15 19
					39 00 00 40 00 00 06 CB 01 70 01 B0 02 //23  27
					39 00 00 40 00 00 04 FE 10 02 90 //33  41
					39 00 00 40 00 00 06 CC 03 70 03 F0 04 //55 63 79
					39 00 00 40 00 00 04 FE F0 05 F0 //95
					39 00 00 40 00 00 06 CD 07 10 08 F0 0A //113 143
					39 00 00 40 00 00 04 FE F0 0B A0 //175 186
					39 00 00 40 00 00 06 CE 0D 30 0E 10 0E //225 239
					39 00 00 40 00 00 04 FE F0 0F F0
					//queue2_end
					39 00 00 40 00 00 04 FF 5A A5 00
					39 00 00 40 00 00 04 FF 5A A5 08 //ALL Done open CDM FIFO Reset
					15 00 00 40 00 00 02 98 A6
					39 00 00 40 00 00 04 FF 5A A5 00 //Dummy write
					15 00 00 40 00 00 02 00 00
					39 00 00 40 00 00 04 FF 5A A5 4F // PAGE 4F
					15 00 00 00 00 00 02 8B 78 // cmd core 0 queue all done
					39 00 00 00 00 00 04 FF 5A A5 00
					/* wait for te and blocking one frame */
					39 00 00 20 00 00 04 FF 5A A5 00
				];
				qcom,mdss-dsi-hbm-off-command = [
				];
				qcom,mdss-dsi-hbm-on-command = [
				];
				qcom,mdss-dsi-change-voltage-before-bl-0-command = [
				];
				qcom,mdss-dsi-lhbm-pressed-icon-on-command = [
				];
				qcom,mdss-dsi-lhbm-pressed-icon-off-command = [
				];
				qcom,mdss-dsi-aod-off-pwm-mode2-command = [
				];
				qcom,mdss-dsi-aod-off-compensation-command = [
				];
				qcom,mdss-dsi-aod-off-compensation-onepulse-command = [
				];
				/* pwm */
				qcom,mdss-dsi-pwm-state-l3tol2-command = [
				];
				qcom,mdss-dsi-pwm-state-l2tol3-command = [
				];
				qcom,mdss-dsi-pwm-switch-mode0-command= [
				];
				qcom,mdss-dsi-pwm-switch-mode2-command = [
				];
				qcom,mdss-dsi-timming-switch-pwm-mode2-command = [
				];
				qcom,mdss-dsi-pwm-switch-mode2-panel-on-command = [
				];
				qcom,mdss-dsi-pwm-state-l1tol3-command = [
				];
				qcom,mdss-dsi-pwm-state-l3tol1-command = [
				];
				qcom,mdss-dsi-hbm-max-command = [
				];
				qcom,mdss-dsi-hbm-exit-max-command = [
				];
				mdss-dsi-timing-switch-command-state = "dsi_hs_sync1_mode";
				qcom,mdss-dsi-lp1-command-state = "dsi_hs_sync1_mode";
				qcom,mdss-dsi-nolp-command-state = "dsi_hs_sync1_mode";
				oplus,dsi-panel-switch-low-pwm-aod-on-command-state = "dsi_hs_sync1_mode";
				oplus,dsi-panel-switch-low-pwm-aod-off-command-state = "dsi_hs_sync1_mode";
				qcom,mdss-dsi-aod-off-pwm-mode2-command-state = "dsi_hs_sync1_mode";
				qcom,mdss-dsi-aod-off-compensation-command-state = "dsi_lp_sync1_mode";
				qcom,mdss-dsi-aod-off-compensation-onepulse-command-state = "dsi_lp_sync1_mode";
				qcom,mdss-dsi-nolp-hpwm-command-state = "dsi_lp_sync1_mode";
				qcom,mdss-dsi-hbm-on-command-state = "dsi_hs_sync1_mode";
				qcom,mdss-dsi-hbm-off-command-state = "dsi_hs_sync1_mode";
				qcom,mdss-dsi-panel-read-register-open-state = "dsi_lp_mode";
				qcom,mdss-dsi-panel-read-register-close-state = "dsi_lp_mode";
				qcom,mdss-dsi-lhbm-pressed-icon-gamma-command-state = "dsi_lp_mode";
				qcom,mdss-dsi-lhbm-pressed-icon-grayscale-command-state = "dsi_lp_mode";
				qcom,mdss-dsi-lhbm-pressed-icon-on-command-state = "dsi_lp_mode";
				qcom,mdss-dsi-lhbm-pressed-icon-off-command-state = "dsi_lp_mode";
				qcom,mdss-dsi-lhbm-dbv-alpha-command-state = "dsi_hs_mode";

				qcom,mdss-dsi-reset-scanline-command-state = "dsi_hs_mode";
				qcom,mdss-dsi-recovery-scanline-command-state = "dsi_hs_mode";

				qcom,mdss-dsi-osc-track-on-command-state = "dsi_hs_mode";
				qcom,mdss-dsi-osc-track-off-command-state = "dsi_hs_mode";
				qcom,mdss-dsi-hbm-max-command-state = "dsi_hs_mode";
				qcom,mdss-dsi-hbm-exit-max-command-state = "dsi_hs_mode";

				qcom,lm-split = <608 608>;
				qcom,compression-mode = "dsc";
				qcom,mdss-dsc-encoders = <2>;
				qcom,mdss-dsc-slice-height = <20>;
				qcom,mdss-dsc-slice-width = <608>;
				qcom,mdss-dsc-slice-per-pkt = <2>;
				qcom,mdss-dsc-bit-per-component = <10>;
				qcom,mdss-dsc-bit-per-pixel = <8>;
				qcom,mdss-dsc-block-prediction-enable;
			};
			timing@sdc_fhd_165 {
				#include "dsi-panel-AA616-P-7-A0020-common.dtsi"
				#include "dsi-panel-AA616-P-7-A0020-loading-effect.dtsi"
				qcom,mdss-mdp-transfer-time-us = <5380>;
				qcom,mdss-dsi-panel-jitter = <0x4 0x1>;
				qcom,mdss-dsc-version = <0x12>;
				qcom,mdss-dsi-timing-default;
				qcom,mdss-dsi-panel-framerate = <165>;
				qcom,mdss-dsi-panel-clockrate = <1370000000>;
				qcom,mdss-dsi-panel-width = <1216>;
				qcom,mdss-dsi-panel-height = <2640>;

				qcom,mdss-dsi-h-front-porch = <44>;
				qcom,mdss-dsi-h-back-porch = <16>;
				qcom,mdss-dsi-h-pulse-width = <16>;
				qcom,mdss-dsi-v-back-porch = <24>;
				qcom,mdss-dsi-v-front-porch = <88>;
				qcom,mdss-dsi-v-pulse-width = <2>;
				qcom,mdss-dsi-h-sync-pulse = <0>;

				qcom,mdss-dsi-timing-switch-compensation-command = [
					39 00 00 40 00 00 04 FF 5A A5 08 // PAGE 08
					15 00 00 40 00 00 02 98 02 //Queue Start Close CDM FIFO Reset
					39 00 00 40 00 00 04 FF 5A A5 4F // PAGE 4F
					15 00 00 40 00 00 02 80 01 //Enable MSFC
					15 00 00 40 00 00 02 81 06 //04 Rising,05Falling
					15 00 00 40 00 00 02 88 78 // cmd core0 queue start
					//queue1_str
					39 00 00 40 00 00 04 FF 5A A5 24
					39 00 00 40 00 00 06 C9 00 00 00 10 00 //0 1
					39 00 00 40 00 00 04 FE 30 00 70 //3  7
					39 00 00 40 00 00 06 CA 00 A0 00 B0 00 //11  13
					39 00 00 40 00 00 04 FE D0 01 30 //15  19
					39 00 00 40 00 00 06 CB 01 70 01 A0 02 //23  27
					39 00 00 40 00 00 04 FE 10 02 90 //33  41
					39 00 00 40 00 00 06 CC 03 70 04 00 04 //55  63
					39 00 00 40 00 00 04 FE F0 05 F0 //79 95
					39 00 00 40 00 00 06 CD 07 10 08 F0 0A //113 143
					39 00 00 40 00 00 04 FE F0 0B A0 //175 186
					39 00 00 40 00 00 06 CE 0D 30 0E 10 0E //211 225
					39 00 00 40 00 00 04 FE F0 0F F0 //239 255
					//queue1_end
					39 00 00 40 00 00 04 FF 5A A5 4F // PAGE 4F
					15 00 00 40 00 00 02 8A 78
					//queue2_str
					39 00 00 40 00 00 04 FF 5A A5 00 // PAGE 00
					15 00 00 40 00 00 02 60 03 //165Hz
					15 00 00 40 00 00 02 7D 03
					39 00 00 40 00 00 04 FF 5A A5 20
					15 00 00 40 00 00 02 BB 05 //sync setting
					//queue1_str
					39 00 00 40 00 00 04 FF 5A A5 24
					39 00 00 40 00 00 06 C9 00 00 00 10 00
					39 00 00 40 00 00 04 FE 30 00 70
					39 00 00 40 00 00 06 CA 00 B0 00 D0 00 //11 13
					39 00 00 40 00 00 04 FE F0 01 30 //15 19
					39 00 00 40 00 00 06 CB 01 70 01 B0 02 //23  27
					39 00 00 40 00 00 04 FE 10 02 90 //33  41
					39 00 00 40 00 00 06 CC 03 70 03 F0 04 //55 63 79
					39 00 00 40 00 00 04 FE F0 05 F0 //95
					39 00 00 40 00 00 06 CD 07 10 08 F0 0A //113 143
					39 00 00 40 00 00 04 FE F0 0B A0 //175 186
					39 00 00 40 00 00 06 CE 0D 30 0E 10 0E //225 239
					39 00 00 40 00 00 04 FE F0 0F F0
					39 00 00 40 00 00 04 FF 5A A5 53
					39 00 00 40 00 00 06 90 44 00 00 04 00
					39 00 00 40 00 00 06 FE 44 00 00 04 00
					39 00 00 40 00 00 06 FE 44 00 00 04 00
					39 00 00 40 00 00 06 FE 44 00 00 04 00
					15 00 00 40 00 00 02 F0 01 //MURA_TUNNING
					15 00 00 40 00 00 02 00 00
					15 00 00 40 00 00 02 00 00
					15 00 00 40 00 00 02 00 00
					15 00 00 40 00 00 02 00 00
					15 00 00 40 00 00 02 00 00
					15 00 00 40 00 00 02 00 00
					15 00 00 40 00 00 02 00 00
					15 00 00 40 00 00 02 00 00
					39 00 00 40 00 00 04 FF 5A A5 63
					39 00 00 40 00 00 06 F1 20 20 20 20 20
					39 00 00 40 00 00 06 FE 20 00 00 00 00
					39 00 00 40 00 00 06 FE 00 00 00 00 00
					15 00 00 40 00 00 02 FE 00
					15 00 00 40 00 00 02 00 00
					15 00 00 40 00 00 02 00 00
					15 00 00 40 00 00 02 00 00
					15 00 00 40 00 00 02 00 00
					15 00 00 40 00 00 02 00 00
					39 00 00 40 00 00 06 F2 00 00 00 00 00
					39 00 00 40 00 00 06 FE 00 20 20 20 20
					39 00 00 40 00 00 06 FE 00 00 00 00 00
					15 00 00 40 00 00 02 FE 00
					15 00 00 40 00 00 02 00 00
					15 00 00 40 00 00 02 00 00
					15 00 00 40 00 00 02 00 00
					15 00 00 40 00 00 02 00 00
					15 00 00 40 00 00 02 00 00
					39 00 00 40 00 00 06 F3 00 00 00 00 00
					39 00 00 40 00 00 06 FE 00 00 00 00 00
					39 00 00 40 00 00 06 FE 00 00 00 00 00
					15 00 00 40 00 00 02 FE 00
					15 00 00 40 00 00 02 00 00
					15 00 00 40 00 00 02 00 00
					15 00 00 40 00 00 02 00 00
					15 00 00 40 00 00 02 00 00
					15 00 00 40 00 00 02 00 00
					39 00 00 40 00 00 06 F4 00 00 00 00 00
					39 00 00 40 00 00 06 FE 00 F0 F0 F0 F0
					39 00 00 40 00 00 06 FE 00 00 00 00 00
					15 00 00 40 00 00 02 FE 00
					15 00 00 40 00 00 02 00 00
					15 00 00 40 00 00 02 00 00
					15 00 00 40 00 00 02 00 00
					15 00 00 40 00 00 02 00 00
					15 00 00 40 00 00 02 00 00
					15 00 00 40 00 00 02 00 00
					15 00 00 40 00 00 02 00 00
					15 00 00 40 00 00 02 00 00
					39 00 00 40 00 00 04 FF 5A A5 53
					15 00 00 40 00 00 02 F0 00
					39 00 00 40 00 00 04 FF 5A A5 00
					39 00 00 40 00 00 04 FF 5A A5 08 //ALL Done open CDM FIFO Reset
					15 00 00 40 00 00 02 98 A6
					39 00 00 40 00 00 04 FF 5A A5 00 //Dummy write
					15 00 00 40 00 00 02 00 00
					39 00 00 40 00 00 04 FF 5A A5 4F // PAGE 4F
					15 00 00 40 00 00 02 8B 78 // cmd core 0 queue all done
					39 00 00 00 00 00 04 FF 5A A5 00
					/* wait for te and blocking one frame */
					39 00 00 20 00 00 04 FF 5A A5 00
				];
				qcom,mdss-dsi-on-command = [
					39 00 00 40 00 00 04 FF 5A A5 08
					15 00 00 40 00 00 02 C8 62
					39 00 00 40 00 00 04 FF 5A A5 21
					15 00 00 40 00 00 02 A4 38
					39 00 00 40 00 00 04 FF 5A A5 23
					15 00 00 40 00 00 02 85 15
					39 00 00 40 00 00 04 FF 5A A5 06
					15 00 00 40 00 00 02 C6 01
					39 00 00 40 00 00 04 FF 5A A5 08
					15 00 00 40 00 00 02 D2 05
					15 00 00 40 00 00 02 D3 01
					39 00 00 40 00 00 09 ED FF FF FF FF FF FF 45 FF
					39 00 00 40 00 00 09 EE FF FD FF FD F9 FA BE 76

					39 00 00 40 00 00 04 FF 5A A5 07
					15 00 00 40 00 00 02 8A 01
					39 00 00 40 00 00 03 8B 21 E0
					39 00 00 40 00 00 64 81 00 00 00 00 00 12 00 00 AB 21 00 0A 50 04 C0 00 14 02 60 02 60 01 55 01 D3 00 0A 01 08 00 33 00 0D 05 7A 19 5A 08 00 0B F0 07 10 20 00 06 0F 0F 33 0E 1C 2A 38 46 54 62 69 70 77 79 7B 7D 7E 00 82 11 40 19 C0 22 3E 32 7C 3A BA 3A F8 3B 38 3B 38 3B 76 4B 76 4B 74 4B 74 5B B4 73 F4 01 00 00 00 00 00
					15 00 00 40 00 00 02 91 03
					39 00 00 40 00 00 04 FF 5A A5 14
					15 00 00 40 00 00 02 80 00
					15 00 00 40 00 00 02 82 01
					39 00 00 40 00 00 04 FF 5A A5 17
					15 00 00 40 00 00 02 A0 0C
					39 00 00 40 00 00 04 FF 5A A5 13
					15 00 00 40 00 00 02 F9 3C
					39 00 00 40 00 00 04 FF 5A A5 22
					39 00 00 40 00 00 08 D8 00 F4 11 10 3E 17 17
					39 00 00 40 00 00 08 D9 00 F3 11 10 3E 17 17
					39 00 00 40 00 00 08 DA 00 EA 11 10 2B 16 16
					39 00 00 40 00 00 08 DB 00 E9 11 10 2B 16 16
					39 00 00 40 00 00 0A DC 84 94 BB 00 20 C4 A1 CC 10
					15 00 00 40 00 00 02 DD 01
					15 00 00 40 00 00 02 DE F1
					15 00 00 40 00 00 02 DF 80
					39 00 00 00 00 00 07 E0 02 00 5F 21 00 28

					39 00 00 40 00 00 04 FF 5A A5 00
					15 00 00 00 00 00 02 7D 03 //165Hz FFC

					39 00 00 40 00 00 04 FF 5A A5 22
					39 00 00 40 00 00 08 D8 00 F6 11 10 38 17 17
					39 00 00 40 00 00 08 D9 00 F5 11 10 38 17 17
					39 00 00 40 00 00 08 DA 00 EA 11 10 2B 16 16
					39 00 00 40 00 00 08 DB 00 E9 11 10 2B 16 16
					39 00 00 40 00 00 0A DC 84 94 BB 00 20 C4 A1 CC 10
					15 00 00 40 00 00 02 DD 01
					15 00 00 40 00 00 02 DE F1
					15 00 00 40 00 00 02 DF 80
					39 00 00 40 00 00 07 E0 02 00 5F 21 00 28
					15 00 00 40 00 00 02 5E 01 // Skip frame Enable
					15 00 00 40 00 00 02 60 00 // Normal mode1=120Hz
					15 00 00 40 00 00 02 61 02 //AOD in Mode3=30Hz
					15 00 00 40 00 00 02 6D 01 // IRC enable
					15 00 00 40 00 00 02 35 00 // TE on
					15 00 00 00 00 00 02 53 20 // BC On

					// 165Hz
					39 00 00 40 00 00 04 FF 5A A5 00
					15 00 00 00 00 00 02 60 03
					39 00 00 40 00 00 04 FF 5A A5 00 // PAGE 00
					15 00 00 40 00 00 02 60 03 //165Hz
					15 00 00 40 00 00 02 7D 03
					39 00 00 40 00 00 04 FF 5A A5 20
					15 00 00 40 00 00 02 BB 05 //sync setting
					39 00 00 40 00 00 04 FF 5A A5 24
					39 00 00 40 00 00 06 C9 00 00 00 10 00
					39 00 00 40 00 00 04 FE 30 00 70
					39 00 00 40 00 00 06 CA 00 B0 00 D0 00 //11 13
					39 00 00 40 00 00 04 FE F0 01 30 //15 19
					39 00 00 40 00 00 06 CB 01 70 01 B0 02 //23  27
					39 00 00 40 00 00 04 FE 10 02 90 //33  41
					39 00 00 40 00 00 06 CC 03 70 03 F0 04 //55 63 79
					39 00 00 40 00 00 04 FE F0 05 F0 //95
					39 00 00 40 00 00 06 CD 07 10 08 F0 0A //113 143
					39 00 00 40 00 00 04 FE F0 0B A0 //175 186
					39 00 00 40 00 00 06 CE 0D 30 0E 10 0E //225 239
					39 00 00 40 00 00 04 FE F0 0F F0
					39 00 00 40 00 00 04 FF 5A A5 53
					39 00 00 40 00 00 06 90 44 00 00 04 00
					39 00 00 40 00 00 06 FE 44 00 00 04 00
					39 00 00 40 00 00 06 FE 44 00 00 04 00
					39 00 00 40 00 00 06 FE 44 00 00 04 00
					15 00 00 40 00 00 02 F0 01 //MURA_TUNNING
					15 00 00 40 00 00 02 00 00
					15 00 00 40 00 00 02 00 00
					15 00 00 40 00 00 02 00 00
					15 00 00 40 00 00 02 00 00
					15 00 00 40 00 00 02 00 00
					15 00 00 40 00 00 02 00 00
					15 00 00 40 00 00 02 00 00
					15 00 00 40 00 00 02 00 00
					39 00 00 40 00 00 04 FF 5A A5 63
					39 00 00 40 00 00 06 F1 20 20 20 20 20
					39 00 00 40 00 00 06 FE 20 00 00 00 00
					39 00 00 40 00 00 06 FE 00 00 00 00 00
					15 00 00 40 00 00 02 FE 00
					15 00 00 40 00 00 02 00 00
					15 00 00 40 00 00 02 00 00
					15 00 00 40 00 00 02 00 00
					15 00 00 40 00 00 02 00 00
					15 00 00 40 00 00 02 00 00
					39 00 00 40 00 00 06 F2 00 00 00 00 00
					39 00 00 40 00 00 06 FE 00 20 20 20 20
					39 00 00 40 00 00 06 FE 00 00 00 00 00
					15 00 00 40 00 00 02 FE 00
					15 00 00 40 00 00 02 00 00
					15 00 00 40 00 00 02 00 00
					15 00 00 40 00 00 02 00 00
					15 00 00 40 00 00 02 00 00
					15 00 00 40 00 00 02 00 00
					39 00 00 40 00 00 06 F3 00 00 00 00 00
					39 00 00 40 00 00 06 FE 00 00 00 00 00
					39 00 00 40 00 00 06 FE 00 00 00 00 00
					15 00 00 40 00 00 02 FE 00
					15 00 00 40 00 00 02 00 00
					15 00 00 40 00 00 02 00 00
					15 00 00 40 00 00 02 00 00
					15 00 00 40 00 00 02 00 00
					15 00 00 40 00 00 02 00 00
					39 00 00 40 00 00 06 F4 00 00 00 00 00
					39 00 00 40 00 00 06 FE 00 F0 F0 F0 F0
					39 00 00 40 00 00 06 FE 00 00 00 00 00
					15 00 00 40 00 00 02 FE 00
					15 00 00 40 00 00 02 00 00
					15 00 00 40 00 00 02 00 00
					15 00 00 40 00 00 02 00 00
					15 00 00 40 00 00 02 00 00
					15 00 00 40 00 00 02 00 00
					15 00 00 40 00 00 02 00 00
					15 00 00 40 00 00 02 00 00
					15 00 00 40 00 00 02 00 00
					39 00 00 40 00 00 04 FF 5A A5 53
					15 00 00 40 00 00 02 F0 00
					15 00 00 00 78 00 02 11 00
					39 00 00 40 00 00 04 FF 5A A5 49
					39 00 00 40 00 00 0C 80 00 01 09 11 21 41 81 C1 01 00 01
					39 00 00 40 00 00 11 81 01 00 BD 00 18 01 41 02 42 02 A6 03 8B 05 DD 06
					39 00 00 40 00 00 13 82 01 00 BD 00 18 01 41 02 42 02 A6 03 8B 05 DD 06 00 00
					15 00 00 40 00 00 02 83 07
					15 00 00 40 00 00 02 84 0A
					39 00 00 40 00 00 04 85 80 00 02
					39 00 00 40 00 00 04 86 80 00 02
					39 00 00 40 00 00 04 A0 40 40 40
					39 00 00 40 00 00 04 A1 40 40 40
					39 00 00 40 00 00 04 A2 40 40 40
					15 00 00 40 00 00 02 A6 3F
					15 00 00 40 00 00 02 A7 03
					15 00 00 40 00 00 02 AD 01
					15 00 00 40 00 00 02 AE 00
					15 00 00 40 00 00 02 AF 00
					15 00 00 40 00 00 02 D9 02
					15 00 00 40 00 00 02 DA F7
					15 00 00 40 00 00 02 DB 9C
					15 00 00 40 00 00 02 DC 03
					15 00 00 40 00 00 02 DF 06
					15 00 00 40 00 00 02 E0 01
					39 00 00 40 00 00 04 FF 5A A5 5A
					39 00 00 40 00 00 04 80 03 D0 00
					39 00 00 40 00 00 04 81 5D D0 40
					39 00 00 40 00 00 04 82 0F 04 0B
					39 00 00 40 00 00 04 83 6D 80 0C
					39 00 00 40 00 00 04 84 50 20 4A
					39 00 00 40 00 00 04 85 18 10 2D
					39 00 00 40 00 00 04 86 7E 80 0E
					39 00 00 40 00 00 04 87 1D 13 17
					39 00 00 40 00 00 04 88 10 0F 0F
					39 00 00 40 00 00 04 89 0C 0A 06
					39 00 00 40 00 00 04 8A 7F 14 F0
					39 00 00 40 00 00 04 8B 1A 15 1B
					39 00 00 40 00 00 04 8C 18 12 1A
					39 00 00 40 00 00 04 8D 18 11 18
					39 00 00 40 00 00 04 8E 09 06 0A
					39 00 00 40 00 00 04 8F 7F 46 F6
					39 00 00 40 00 00 04 90 1C 14 1D
					39 00 00 40 00 00 04 91 1A 12 1B
					39 00 00 40 00 00 04 92 18 0A 19
					39 00 00 40 00 00 04 93 15 06 16
					39 00 00 40 00 00 04 94 0C 02 0D
					39 00 00 40 00 00 04 95 57 1D 03
					39 00 00 40 00 00 04 96 18 10 1A
					39 00 00 40 00 00 04 97 10 0F 12
					39 00 00 40 00 00 04 98 10 07 10
					39 00 00 40 00 00 04 99 0C 0A 0F
					39 00 00 40 00 00 04 9A 04 03 0A
					39 00 00 40 00 00 04 9B 03 01 03
					39 00 00 40 00 00 04 9C 52 3E 2D
					39 00 00 40 00 00 04 9D 34 32 2D
					39 00 00 40 00 00 04 9E 23 20 22
					39 00 00 40 00 00 04 9F 1D 1A 1D
					39 00 00 40 00 00 04 A0 16 12 16
					39 00 00 40 00 00 04 A1 0A 08 09
					39 00 00 40 00 00 04 A2 07 03 05
					39 00 00 40 00 00 04 A3 06 01 03
					39 00 00 40 00 00 04 A4 02 D0 00
					39 00 00 40 00 00 04 A5 14 DD 0F
					39 00 00 40 00 00 04 A6 0A E4 0C
					39 00 00 40 00 00 04 A7 4A 80 D8
					39 00 00 40 00 00 04 A8 05 02 07
					39 00 00 40 00 00 04 A9 03 00 05
					39 00 00 40 00 00 04 AA 24 80 8F
					39 00 00 40 00 00 04 AB 0A 06 09
					39 00 00 40 00 00 04 AC 07 05 07
					39 00 00 40 00 00 04 AD 03 00 05
					39 00 00 40 00 00 04 AE 32 03 04
					39 00 00 40 00 00 04 AF 13 10 12
					39 00 00 40 00 00 04 B0 10 06 0D
					39 00 00 40 00 00 04 B1 0E 04 0C
					39 00 00 40 00 00 04 B2 03 01 05
					39 00 00 40 00 00 04 B3 2A 16 02
					39 00 00 40 00 00 04 B4 0E 0C 10
					39 00 00 40 00 00 04 B5 0D 0A 0E
					39 00 00 40 00 00 04 B6 0A 07 0A
					39 00 00 40 00 00 04 B7 07 05 0B
					39 00 00 40 00 00 04 B8 05 04 06
					39 00 00 40 00 00 04 B9 1F 10 1D
					39 00 00 40 00 00 04 BA 18 0F 12
					39 00 00 40 00 00 04 BB 13 0D 0A
					39 00 00 40 00 00 04 BC 0E 08 0A
					39 00 00 40 00 00 04 BD 09 06 0C
					39 00 00 40 00 00 04 BE 07 05 08
					39 00 00 40 00 00 04 BF 04 04 06
					39 00 00 40 00 00 04 C0 37 23 2F
					39 00 00 40 00 00 04 C1 27 1F 1F
					39 00 00 40 00 00 04 C2 1D 18 0D
					39 00 00 40 00 00 04 C3 1A 12 08
					39 00 00 40 00 00 04 C4 12 10 06
					39 00 00 40 00 00 04 C5 0A 07 03
					39 00 00 40 00 00 04 C6 08 04 02
					39 00 00 40 00 00 04 C7 03 02 01
					39 00 00 40 00 00 04 C8 40 06 0A
					39 00 00 40 00 00 04 C9 25 00 12
					39 00 00 40 00 00 04 CA 16 00 06
					39 00 00 40 00 00 04 CB 5A 00 00
					39 00 00 40 00 00 04 CC 06 01 06
					39 00 00 40 00 00 04 CD 03 00 05
					39 00 00 40 00 00 04 CE 30 00 00
					39 00 00 40 00 00 04 CF 10 04 06
					39 00 00 40 00 00 04 D0 0D 02 0E
					39 00 00 40 00 00 04 D1 06 00 0A
					39 00 00 40 00 00 04 D2 20 02 08
					39 00 00 40 00 00 04 D3 0D 04 06
					39 00 00 40 00 00 04 D4 08 00 05
					39 00 00 40 00 00 04 D5 06 00 03
					39 00 00 40 00 00 04 D6 05 00 01
					39 00 00 40 00 00 04 D7 26 15 16
					39 00 00 40 00 00 04 D8 12 0D 13
					39 00 00 40 00 00 04 D9 10 0A 12
					39 00 00 40 00 00 04 DA 0D 09 08
					39 00 00 40 00 00 04 DB 07 05 07
					39 00 00 40 00 00 04 DC 04 03 05
					39 00 00 40 00 00 04 DD 26 2A 26
					39 00 00 40 00 00 04 DE 20 28 23
					39 00 00 40 00 00 04 DF 16 1A 1E
					39 00 00 40 00 00 04 E0 12 16 14
					39 00 00 40 00 00 04 E1 0D 0F 0E
					39 00 00 40 00 00 04 E2 03 04 02
					39 00 00 40 00 00 04 E3 02 03 01
					39 00 00 40 00 00 04 E4 34 23 14
					39 00 00 40 00 00 04 E5 16 13 00
					39 00 00 40 00 00 04 E6 08 0D 00
					39 00 00 40 00 00 04 E7 06 0A 00
					39 00 00 40 00 00 04 E8 05 08 00
					39 00 00 40 00 00 04 E9 03 05 00
					39 00 00 40 00 00 04 EA 02 04 00
					39 00 00 40 00 00 04 EB 00 02 00
					39 00 00 40 00 00 04 FF 5A A5 5B
					39 00 00 40 00 00 04 80 05 00 00
					39 00 00 40 00 00 04 81 2A FA 10
					39 00 00 40 00 00 04 82 04 00 01
					39 00 00 40 00 00 04 83 2C FC 15
					39 00 00 40 00 00 04 84 08 01 03
					39 00 00 40 00 00 04 85 03 01 02
					39 00 00 40 00 00 04 86 0D 08 0E
					39 00 00 40 00 00 04 87 05 03 02
					39 00 00 40 00 00 04 88 04 02 03
					39 00 00 40 00 00 04 89 03 00 01
					39 00 00 40 00 00 04 8A 16 03 06
					39 00 00 40 00 00 04 8B 04 03 03
					39 00 00 40 00 00 04 8C 02 02 02
					39 00 00 40 00 00 04 8D 01 00 01
					39 00 00 40 00 00 04 8E 00 00 00
					39 00 00 40 00 00 04 8F 24 18 1B
					39 00 00 40 00 00 04 90 18 1C 1A
					39 00 00 40 00 00 04 91 14 16 14
					39 00 00 40 00 00 04 92 10 0F 11
					39 00 00 40 00 00 04 93 0A 08 0B
					39 00 00 40 00 00 04 94 05 06 04
					39 00 00 40 00 00 04 95 25 1D 1E
					39 00 00 40 00 00 04 96 16 18 1A
					39 00 00 40 00 00 04 97 12 14 16
					39 00 00 40 00 00 04 98 10 11 12
					39 00 00 40 00 00 04 99 0A 0C 0D
					39 00 00 40 00 00 04 9A 07 08 0A
					39 00 00 40 00 00 04 9B 05 06 07
					39 00 00 40 00 00 04 9C 38 2C 44
					39 00 00 40 00 00 04 9D 36 2A 40
					39 00 00 40 00 00 04 9E 32 24 3A
					39 00 00 40 00 00 04 9F 20 1A 2A
					39 00 00 40 00 00 04 A0 1A 16 1F
					39 00 00 40 00 00 04 A1 16 10 14
					39 00 00 40 00 00 04 A2 07 08 07
					39 00 00 40 00 00 04 A3 05 06 06
					39 00 00 40 00 00 04 A4 06 00 00
					39 00 00 40 00 00 04 A5 10 09 02
					39 00 00 40 00 00 04 A6 06 00 02
					39 00 00 40 00 00 04 A7 0F 08 04
					39 00 00 40 00 00 04 A8 06 02 07
					39 00 00 40 00 00 04 A9 05 01 06
					39 00 00 40 00 00 04 AA 10 02 07
					39 00 00 40 00 00 04 AB 04 02 03
					39 00 00 40 00 00 04 AC 03 01 02
					39 00 00 40 00 00 04 AD 02 00 04
					39 00 00 40 00 00 04 AE 1A 06 09
					39 00 00 40 00 00 04 AF 09 06 09
					39 00 00 40 00 00 04 B0 08 05 07
					39 00 00 40 00 00 04 B1 07 03 05
					39 00 00 40 00 00 04 B2 04 01 03
					39 00 00 40 00 00 04 B3 1F 13 16
					39 00 00 40 00 00 04 B4 18 13 19
					39 00 00 40 00 00 04 B5 15 12 17
					39 00 00 40 00 00 04 B6 11 0D 13
					39 00 00 40 00 00 04 B7 0A 08 0D
					39 00 00 40 00 00 04 B8 04 06 07
					39 00 00 40 00 00 04 B9 26 1D 23
					39 00 00 40 00 00 04 BA 1A 18 1C
					39 00 00 40 00 00 04 BB 14 10 15
					39 00 00 40 00 00 04 BC 10 13 12
					39 00 00 40 00 00 04 BD 0B 0F 0F
					39 00 00 40 00 00 04 BE 04 05 04
					39 00 00 40 00 00 04 BF 03 02 03
					39 00 00 40 00 00 04 C0 3C 30 4C
					39 00 00 40 00 00 04 C1 3A 2A 40
					39 00 00 40 00 00 04 C2 32 24 3A
					39 00 00 40 00 00 04 C3 20 1D 2C
					39 00 00 40 00 00 04 C4 1A 16 1F
					39 00 00 40 00 00 04 C5 16 10 14
					39 00 00 40 00 00 04 C6 05 06 08
					39 00 00 40 00 00 04 C7 04 05 06
					39 00 00 40 00 00 04 C8 04 00 00
					39 00 00 40 00 00 04 C9 18 0D 10
					39 00 00 40 00 00 04 CA 18 00 02
					39 00 00 40 00 00 04 CB 0C 04 04
					39 00 00 40 00 00 04 CC 03 02 01
					39 00 00 40 00 00 04 CD 02 01 00
					39 00 00 40 00 00 04 CE 06 03 08
					39 00 00 40 00 00 04 CF 04 02 04
					39 00 00 40 00 00 04 D0 03 01 03
					39 00 00 40 00 00 04 D1 02 00 00
					39 00 00 40 00 00 04 D2 0E 0A 10
					39 00 00 40 00 00 04 D3 0A 08 0D
					39 00 00 40 00 00 04 D4 07 05 0A
					39 00 00 40 00 00 04 D5 04 03 07
					39 00 00 40 00 00 04 D6 03 01 06
					39 00 00 40 00 00 04 D7 18 12 22
					39 00 00 40 00 00 04 D8 16 10 1A
					39 00 00 40 00 00 04 D9 12 0A 14
					39 00 00 40 00 00 04 DA 0D 08 12
					39 00 00 40 00 00 04 DB 06 06 0C
					39 00 00 40 00 00 04 DC 02 04 03
					39 00 00 40 00 00 04 DD 2C 28 34
					39 00 00 40 00 00 04 DE 28 22 30
					39 00 00 40 00 00 04 DF 20 18 2A
					39 00 00 40 00 00 04 E0 16 14 1A
					39 00 00 40 00 00 04 E1 0A 08 0D
					39 00 00 40 00 00 04 E2 03 03 03
					39 00 00 40 00 00 04 E3 02 02 02
					39 00 00 40 00 00 04 E4 3C 34 40
					39 00 00 40 00 00 04 E5 3A 2A 40
					39 00 00 40 00 00 04 E6 32 24 3A
					39 00 00 40 00 00 04 E7 20 1D 2C
					39 00 00 40 00 00 04 E8 1A 16 1F
					39 00 00 40 00 00 04 E9 16 10 14
					39 00 00 40 00 00 04 EA 03 02 03
					39 00 00 40 00 00 04 EB 04 05 06
					39 00 00 40 00 00 04 FF 5A A5 5C
					39 00 00 40 00 00 04 80 03 F4 FA
					39 00 00 40 00 00 04 81 05 00 02
					39 00 00 40 00 00 04 82 02 01 03
					39 00 00 40 00 00 04 83 09 04 06
					39 00 00 40 00 00 04 84 05 02 05
					39 00 00 40 00 00 04 85 04 01 04
					39 00 00 40 00 00 04 86 08 07 05
					39 00 00 40 00 00 04 87 07 05 0A
					39 00 00 40 00 00 04 88 04 04 04
					39 00 00 40 00 00 04 89 02 02 02
					39 00 00 40 00 00 04 8A 0C 08 0F
					39 00 00 40 00 00 04 8B 0A 07 0C
					39 00 00 40 00 00 04 8C 09 06 0A
					39 00 00 00 00 00 04 8D 06 05 08
					39 00 00 40 00 00 04 8E 04 03 05
					39 00 00 40 00 00 04 8F 23 1A 26
					39 00 00 40 00 00 04 90 1C 14 1D
					39 00 00 40 00 00 04 91 12 0A 18
					39 00 00 40 00 00 04 92 0D 07 14
					39 00 00 40 00 00 04 93 06 07 0A
					39 00 00 40 00 00 04 94 02 04 03
					39 00 00 40 00 00 04 95 34 32 3A
					39 00 00 40 00 00 04 96 2B 28 34
					39 00 00 40 00 00 04 97 26 24 2A
					39 00 00 40 00 00 04 98 16 14 1A
					39 00 00 40 00 00 04 99 0A 08 0D
					39 00 00 40 00 00 04 9A 03 03 02
					39 00 00 40 00 00 04 9B 02 02 02
					39 00 00 40 00 00 04 9C 44 3E 54
					39 00 00 40 00 00 04 9D 3A 2A 40
					39 00 00 40 00 00 04 9E 34 26 3A
					39 00 00 40 00 00 04 9F 20 1D 2C
					39 00 00 40 00 00 04 A0 1A 16 1F
					39 00 00 40 00 00 04 A1 16 10 14
					39 00 00 40 00 00 04 A2 03 02 03
					39 00 00 40 00 00 04 A3 04 05 06
					39 00 00 40 00 00 04 A4 04 02 02
					39 00 00 40 00 00 04 A5 06 03 03
					39 00 00 40 00 00 04 A6 02 01 01
					39 00 00 40 00 00 04 A7 03 02 02
					39 00 00 40 00 00 04 A8 02 01 02
					39 00 00 40 00 00 04 A9 02 01 02
					39 00 00 40 00 00 04 AA 05 05 06
					39 00 00 40 00 00 04 AB 04 04 05
					39 00 00 40 00 00 04 AC 03 03 04
					39 00 00 40 00 00 04 AD 02 02 03
					39 00 00 40 00 00 04 AE 08 04 08
					39 00 00 40 00 00 04 AF 06 03 07
					39 00 00 40 00 00 04 B0 05 02 06
					39 00 00 40 00 00 04 B1 03 01 05
					39 00 00 40 00 00 04 B2 02 00 04
					39 00 00 40 00 00 04 B3 25 23 24
					39 00 00 40 00 00 04 B4 23 20 21
					39 00 00 40 00 00 04 B5 13 0D 14
					39 00 00 40 00 00 04 B6 0E 0A 10
					39 00 00 40 00 00 04 B7 06 08 0A
					39 00 00 40 00 00 04 B8 02 04 03
					39 00 00 40 00 00 04 B9 34 31 37
					39 00 00 40 00 00 04 BA 2B 28 34
					39 00 00 40 00 00 04 BB 26 24 2A
					39 00 00 40 00 00 04 BC 16 15 1A
					39 00 00 40 00 00 04 BD 0A 08 0D
					39 00 00 40 00 00 04 BE 02 03 02
					39 00 00 40 00 00 04 BF 02 01 02
					39 00 00 40 00 00 04 C0 35 33 28
					39 00 00 40 00 00 04 C1 34 2A 24
					39 00 00 40 00 00 04 C2 34 26 1C
					39 00 00 40 00 00 04 C3 20 1D 18
					39 00 00 40 00 00 04 C4 1A 16 16
					39 00 00 40 00 00 04 C5 16 10 14
					39 00 00 40 00 00 04 C6 03 02 03
					39 00 00 40 00 00 04 C7 04 05 06
					39 00 00 40 00 00 04 C8 08 04 06
					39 00 00 40 00 00 04 C9 08 04 06
					39 00 00 40 00 00 04 CA 07 03 05
					39 00 00 40 00 00 04 CB 07 03 05
					39 00 00 40 00 00 04 CC 00 00 00
					39 00 00 40 00 00 04 CD 00 00 00
					39 00 00 40 00 00 04 CE 00 00 00
					39 00 00 00 00 00 04 CF 00 00 00
					15 00 00 00 14 00 02 29 00
				];
				qcom,mdss-dsi-off-command=[
					05 00 00 00 14 00 01 28
					05 00 00 00 78 00 01 10
				];
				oplus,dsi-panel-switch-low-pwm-aod-on-command = [
				];
				oplus,dsi-panel-switch-low-pwm-aod-off-command = [
				];
				qcom,mdss-dsi-hbm-off-command = [
				];
				qcom,mdss-dsi-hbm-on-command = [
				];
				qcom,mdss-dsi-change-voltage-before-bl-0-command = [
				];
				qcom,mdss-dsi-lhbm-pressed-icon-on-command = [
				];
				qcom,mdss-dsi-lhbm-pressed-icon-off-command = [
				];
				qcom,mdss-dsi-aod-off-pwm-mode2-command = [
				];
				qcom,mdss-dsi-aod-off-compensation-command = [
				];
				qcom,mdss-dsi-aod-off-compensation-onepulse-command = [
				];

				/* pwm */
				qcom,mdss-dsi-pwm-state-l3tol2-command = [
				];
				qcom,mdss-dsi-pwm-state-l2tol3-command = [
				];
				qcom,mdss-dsi-pwm-switch-mode0-command= [
				];
				qcom,mdss-dsi-pwm-switch-mode2-command = [
				];
				qcom,mdss-dsi-timming-switch-pwm-mode2-command = [
				];
				qcom,mdss-dsi-pwm-switch-mode2-panel-on-command = [
				];
				qcom,mdss-dsi-pwm-state-l1tol3-command = [
				];
				qcom,mdss-dsi-pwm-state-l3tol1-command = [
				];
				qcom,mdss-dsi-hbm-max-command = [
				];
				qcom,mdss-dsi-hbm-exit-max-command = [
				];
				mdss-dsi-timing-switch-command-state = "dsi_hs_sync1_mode";
				qcom,mdss-dsi-lp1-command-state = "dsi_hs_sync1_mode";
				qcom,mdss-dsi-nolp-command-state = "dsi_hs_sync1_mode";
				oplus,dsi-panel-switch-low-pwm-aod-on-command-state = "dsi_hs_sync1_mode";
				oplus,dsi-panel-switch-low-pwm-aod-off-command-state = "dsi_hs_sync1_mode";
				qcom,mdss-dsi-aod-off-pwm-mode2-command-state = "dsi_hs_sync1_mode";
				qcom,mdss-dsi-aod-off-compensation-command-state = "dsi_lp_sync1_mode";
				qcom,mdss-dsi-aod-off-compensation-onepulse-command-state = "dsi_lp_sync1_mode";
				qcom,mdss-dsi-nolp-hpwm-command-state = "dsi_lp_sync1_mode";
				qcom,mdss-dsi-hbm-on-command-state = "dsi_hs_sync1_mode";
				qcom,mdss-dsi-hbm-off-command-state = "dsi_hs_sync1_mode";
				qcom,mdss-dsi-panel-read-register-open-state = "dsi_lp_mode";
				qcom,mdss-dsi-panel-read-register-close-state = "dsi_lp_mode";
				qcom,mdss-dsi-lhbm-pressed-icon-gamma-command-state = "dsi_lp_mode";
				qcom,mdss-dsi-lhbm-pressed-icon-grayscale-command-state = "dsi_lp_mode";
				qcom,mdss-dsi-lhbm-pressed-icon-on-command-state = "dsi_lp_mode";
				qcom,mdss-dsi-lhbm-pressed-icon-off-command-state = "dsi_lp_mode";
				qcom,mdss-dsi-lhbm-dbv-alpha-command-state = "dsi_hs_mode";

				qcom,mdss-dsi-reset-scanline-command-state = "dsi_hs_mode";
				qcom,mdss-dsi-recovery-scanline-command-state = "dsi_hs_mode";

				qcom,mdss-dsi-osc-track-on-command-state = "dsi_hs_mode";
				qcom,mdss-dsi-osc-track-off-command-state = "dsi_hs_mode";
				qcom,mdss-dsi-hbm-max-command-state = "dsi_hs_mode";
				qcom,mdss-dsi-hbm-exit-max-command-state = "dsi_hs_mode";

				qcom,lm-split = <608 608>;
				qcom,compression-mode = "dsc";
				qcom,mdss-dsc-encoders = <2>;
				qcom,mdss-dsc-slice-height = <20>;
				qcom,mdss-dsc-slice-width = <608>;
				qcom,mdss-dsc-slice-per-pkt = <2>;
				qcom,mdss-dsc-bit-per-component = <10>;
				qcom,mdss-dsc-bit-per-pixel = <8>;
				qcom,mdss-dsc-block-prediction-enable;
			};
		};
	};
};

&soc {
	dsi_panel_AA616_P_7_A0020_dsc_cmd {
		qcom,dsi-display-active;
	};
};

&dsi_panel_AA616_P_7_A0020_dsc_cmd {
	qcom,panel-supply-entries = <&oplus_dsi_panel_custom_pwr_supply>;
	qcom,platform-te-gpio = <&tlmm 86 0>;
	qcom,platform-reset-gpio = <&tlmm 171 0>;
	// /* OLED_PMIC_RST */
	// oplus,panel-gpio1 = <&pmk8850_gpios 1 0>;
	/* VDDR_SM_1P5_EN */
	oplus,panel-gpio2 = <&pmh0101_gpios 4 0>;

	oplus,panel-reset-position = <0x02>;
	oplus,panel-power-on-sequence = "1", "vddio", "3", "vdd", "3", "gpio2", "3", "vci", "10";
	oplus,panel-power-off-sequence = "1", "vci", "3", "vdd", "3", "gpio2", "3", "vddio", "3";

	//enable mipi strength
	oplus,enhance_mipi_strength;

	/* BRIGHTNESS CONFIG */
	qcom,mdss-dsi-bl-pmic-control-type = "bl_ctrl_dcs";
	qcom,bl-update-flag = "delay_until_first_frame";
	qcom,mdss-dsi-bl-inverted-dbv;
	qcom,mdss-dsi-bl-min-level = <1>;
	qcom,mdss-dsi-bl-max-level = <4094>;
	qcom,mdss-brightness-max-level = <4094>;
	oplus,dsi-bl-normal-max-level = <3515>;
	oplus,dsi-brightness-normal-max-level = <3515>;
	oplus,dsi-dc-backlight-threshold = <1960>;
	oplus,dsi-brightness-default-level = <1638>;

	/* ESD CONFIG */
	qcom,esd-check-enabled;
	oplus,esd-check-flag-enabled;
	qcom,mdss-dsi-panel-status-check-mode = "reg_read";
	qcom,mdss-dsi-panel-status-command = [
			06 00 00 00 00 00 01 0A
		];
	qcom,mdss-dsi-panel-status-command-state = "dsi_lp_mode";
	qcom,mdss-dsi-panel-status-value = <
			0x9C
	>;
	qcom,mdss-dsi-panel-status-read-length = <1>;
	oplus,mdss-dsi-panel-status-match-modes = <0x00000000>;

	/* FACTORY CONFIG */
	oplus,mdss-dsi-vendor-name = "A0020";
	oplus,mdss-dsi-manufacture = "P_7";
	oplus,color_vivid_status;
	oplus,color_srgb_status;
	//oplus,color_softiris_status;
	oplus,color_dual_brightness_status;
	oplus,color_2nit_status;
	oplus,color_oplus_calibrate_status;
	//oplus,color_samsung_status;
	oplus,color_loading_status;
	//oplus,color_nature_profession_status;
	oplus,mdss-dsi-panel-type = <2>;

	/* OPLUS FEATURES CONFIG */
	oplus,dsi-serial-number-enabled;
	oplus,dsi-serial-number-switch-page;
	oplus,dsi-serial-number-index= <0>;
	oplus,dsi-serial-number-reg= <0x80>;
	oplus,dsi-serial-number-read-count= <7>;
	oplus,dsi-serial-number-base-year = <2020>;

	/* btb-sn config */
	oplus,dsi-btb-sn-enabled;
	oplus,dsi-btb-sn-switch-page;
	oplus,dsi-btb-sn-reg= <0x82>;
	oplus,dsi-btb-sn-index= <0>;
	oplus,dsi-btb-sn-read-count= <32>;

	qcom,ulps-enabled;
	qcom,dsi-select-clocks = "pll_byte_clk0", "pll_dsi_clk0";

	oplus,vreg_ctrl_flag;

	/* panel dynamic te support config 61hz 122hz Epic:8906208 */
	oplus,dynamic-float-te-support = <1>;

	/* ofp config */
	oplus,ofp-fp-type = <0xc0>;
	oplus,ofp-longrui-aod-config = <0x0E>;
	oplus,ofp-need-to-wait-data-before-aod-on;
	oplus,ofp-aod-off-frame-cost = <1>;
	oplus,ofp-need-to-sync-data-in-aod-unlocking;
	/* adfr config */
	// oplus,adfr-config = <0xe51>;  // 0b0000'0000'0101'0001
	// oplus,adfr-test-te-gpio = <&tlmm 85 0>;
	/* just for qsync enable*/
	qcom,qsync-enable;
	qcom,mdss-dsi-qsync-min-refresh-rate = <30>;

	// qcom,dsi-dyn-clk-enable;
	qcom,mdss-dsi-display-timings {
		timing@sdc_fhd_120 { /* FHD+ 120hz  Mbps */
			qcom,mdss-dsi-panel-phy-timings = [00 24 0A 0A 1A 18 0A 0A 09 02 04 00 1E 0F];
			qcom,display-topology = <1 1 1>,<2 2 1>;
			qcom,default-topology-index = <1>;
			qcom,dsi-mode-te-width-us = <315>;
		};
		timing@sdc_fhd_90 { /* FHD+ 90hz  Mbps */
			qcom,mdss-dsi-panel-phy-timings = [00 24 0A 0A 1A 18 0A 0A 09 02 04 00 1E 0F];
			qcom,display-topology = <1 1 1>,<2 2 1>;
			qcom,default-topology-index = <1>;
			qcom,dsi-mode-te-width-us = <315>;
		};
		timing@sdc_fhd_60 { /* FHD+ 60hz  Mbps */
			qcom,mdss-dsi-panel-phy-timings = [00 24 0A 0A 1A 18 0A 0A 09 02 04 00 1E 0F];
			qcom,display-topology = <1 1 1>,<2 2 1>;
			qcom,default-topology-index = <1>;
			qcom,dsi-mode-te-width-us = <315>;
		};
		timing@sdc_fhd_144 { /* FHD+ 144hz  Mbps */
			qcom,mdss-dsi-panel-phy-timings = [00 2C 0C 0C 1D 1B 0C 0C 0B 02 04 00 24 11];
			qcom,display-topology = <1 1 1>,<2 2 1>;
			qcom,default-topology-index = <1>;
			qcom,dsi-mode-te-width-us = <315>;
		};
		timing@sdc_fhd_165 { /* FHD+ 165hz  Mbps */
			qcom,mdss-dsi-panel-phy-timings = [00 2C 0C 0C 1D 1B 0C 0C 0B 02 04 00 24 11];
			qcom,display-topology = <1 1 1>,<2 2 1>;
			qcom,default-topology-index = <1>;
			qcom,dsi-mode-te-width-us = <315>;
		};
	};
};

&dsi_panel_AA616_P_7_A0020_dsc_cmd {
	qcom,panel_voltage_vddi_name = "vddio";
	qcom,panel_voltage_vddi = <0 1800000 1850000 1950000>;
	qcom,panel_voltage_vddr_name = "vddio";
	qcom,panel_voltage_vddr = <1 1800000 1850000 1950000>;
};

&dsi_panel_AA616_P_7_A0020_dsc_cmd{
	/* demura dbv config */

	/* pwm config */
	/*	oplus,pwm-switch-config:
		Bit0: pwm feature enable
		Bit1: pwm mode switch enable, need to config switch cmds
		Bit2: force enabled pwm mode switch cmd, will send mode cmd even dbv threshold cmd feature is configed
		Bit3: pwm dbv threshold pulse switch enable, need to config threshold switch cmds
		Bit4: wait te before sending pwm dbv threshold pulse switch cmd
		Bit5: replace specific cmd to other cmd while in pwm 1pulse mode
		Bit6: sending extend cmd while panel power on accroding to current pwm mode
		Bit7: sending extend cmd while timing switch accroding to current pwm pulse level
		Bit8: sending extend cmd after sending dbv threshold cmd in another thread
		...
		Bit24:support pwm mode0
		Bit25:support pwm mode1
		Bit26:support pwm mode2
	*/
	// oplus,pwm-switch-config = <0x0700007F>;
	/*	oplus,pwm-switch-mode0-states-info/oplus,pwm-switch-mode1-states-info:
		Specific dbv threshold and pulse info of 2 pwm mode, for pulse, 0 symbols 1pulse,
		1symbols 3pulse and 2 symbols 18pulse. The format should be 1 dbv threshold info with
		2 pwm pulse levels left and right(for example, <2 1087 1> means 18pulse while dbv <= 1087
		and 3pulse while dbv > 1087), or only one pulse level, no threshold.
	*/
	// oplus,pwm-switch-mode0-states-info = <2 1162 1>;
	// oplus,pwm-switch-mode1-states-info = <2 1162 0>;
	// oplus,pwm-switch-mode2-states-info = <0>;
	/*	oplus,pwm-mode1-cmd-switch-map/oplus,pwm-mode2-cmd-switch-map;
		Specific cmd replace relationship while in switch on(1pulse) mode. It is a string array that
		compose with cmd names, every 2 names combine 1 map. For example, map "'a', 'b'" means replace
		a to b while sending a in switch on mode.
	*/
	oplus,pwm-mode2-cmd-switch-map = "qcom,mdss-dsi-nolp-command", "qcom,mdss-dsi-aod-off-pwm-mode2-command",
			"qcom,mdss-dsi-timing-switch-command", "qcom,mdss-dsi-timming-switch-pwm-mode2-command";

	oplus,pwm-compatible-mode;
	oplus,cmdq-sync-support;
	oplus,interval-time-nolp-pre;

	oplus,interval-time-switch-fps-to-esd;

	/* SPR CONFIG */
	qcom,spr-pack-type = "pentile";
	// oplus,gamma-compensation-support;
    /*
    * ###############################################################
    * # Pentile SPR phases for SM8750 and later
    * ###############################################################
    * # RG/BG Type A    BG/RG Type A    GR/GB Type A    GB/GR Type A
    * # R B R B ...     B R B R ...      R B R B ...     B R B R ...
    * #  G G G G ...     G G G G ...    G G G G ...     G G G G ...
    * #
    * # RG/BG Type B    BG/RG Type B    GR/GB Type B    GB/GR Type B
    * #  G G G G ...     G G G G ...    G G G G ...     G G G G ...
    * # R B R B ...     B R B R ...      R B R B ...     B R B R ...
    * ###############################################################
    */
    qcom,spr-pentile-pack-type = "RG-BG Type A";
};
